[part 8 of 11: package /CANAnalyzer/CommunicationClusters]
AUTOSAR XML (schema 00051)
package /CANAnalyzer/CommunicationClusters  (continued)
  can cluster CAN_FD_IPB_41  (continued)
    can physical channel Channel  (continued)
      frame StatusUWBRangingFDD1FBD_HL: id 0x1C8, frame-length=64, can-addressing-mode=STANDARD, can-frame-rx-behavior=CAN-FD, can-frame-tx-behavior=CAN-FD
        pdu StatusUWBRangingFDD1FBD_HL: length=64, unused-bit-pattern=0
          signal StatusUWBRangingFDD1FBD_HL_SessionIDShort: start 0, 8 bit, little-endian, data-type-policy=OVERRIDE, base-type=uint8, compu {phys=raw}, range phys 0..252
          signal StatusUWBRangingFDD1FBD_HL_UWBSessionID: start 8, 32 bit, little-endian, data-type-policy=OVERRIDE, base-type=uint32, compu {phys=raw}, range phys 0..4294967292
          signal StatusUWBRangingFDD1FBD_HL_RangingBlock: start 40, 16 bit, little-endian, data-type-policy=OVERRIDE, base-type=uint16, compu {phys=raw}, range phys 0..65532
          signal StatusUWBRangingFDD1FBD_HL_HoppingFlag: start 56, 8 bit, little-endian, data-type-policy=OVERRIDE, base-type=uint8, compu {phys=raw}, range phys 0..252
          signal StatusUWBRangingFDD1FBD_HL_RoundIndex: start 64, 16 bit, little-endian, data-type-policy=OVERRIDE, base-type=uint16, compu {phys=raw}, range phys 0..65532
          signal StatusUWBRangingFDD1FBD_HL_FinalSTSIndex: start 80, 32 bit, little-endian, data-type-policy=OVERRIDE, base-type=uint32, compu {phys=raw}, range phys 0..4294967292
          signal StatusUWBRangingFDD1FBD_HL_FinalTimeStamp: start 112, 32 bit, little-endian, data-type-policy=OVERRIDE, base-type=uint32, compu {phys=raw}, range phys 0..4294967292
          signal StatusUWBRangingFDD1FBD_HL_NumberResponder: start 144, 8 bit, little-endian, data-type-policy=OVERRIDE, base-type=uint8, compu {phys=raw}, range phys 0..252
          signal StatusUWBRangingFDD1FBD_HL_IndexResponder1: start 152, 8 bit, little-endian, data-type-policy=OVERRIDE, base-type=uint8, compu {phys=raw}, range phys 0..252
          signal StatusUWBRangingFDD1FBD_HL_TimeStampResponder1: start 160, 32 bit, little-endian, data-type-policy=OVERRIDE, base-type=uint32, compu {phys=raw}, range phys 0..4294967292
          signal StatusUWBRangingFDD1FBD_HL_TimeStampUncertaintyResponder1: start 192, 8 bit, little-endian, data-type-policy=OVERRIDE, base-type=uint8, compu {phys=raw}, range phys 0..252
          signal StatusUWBRangingFDD1FBD_HL_StatusResponder1: start 200, 8 bit, little-endian, data-type-policy=OVERRIDE, base-type=uint8, compu {phys=raw}, range phys 0..252
          signal StatusUWBRangingFDD1FBD_HL_IndexResponder2: start 208, 8 bit, little-endian, data-type-policy=OVERRIDE, base-type=uint8, compu {phys=raw}, range phys 0..252
          signal StatusUWBRangingFDD1FBD_HL_TimeStampResponder2: start 216, 32 bit, little-endian, data-type-policy=OVERRIDE, base-type=uint32, compu {phys=raw}, range phys 0..4294967292
          signal StatusUWBRangingFDD1FBD_HL_TimeStampUncertaintyResponder2: start 248, 8 bit, little-endian, data-type-policy=OVERRIDE, base-type=uint8, compu {phys=raw}, range phys 0..252
          signal StatusUWBRangingFDD1FBD_HL_StatusResponder2: start 256, 8 bit, little-endian, data-type-policy=OVERRIDE, base-type=uint8, compu {phys=raw}, range phys 0..252
          signal StatusUWBRangingFDD1FBD_HL_IndexResponder3: start 264, 8 bit, little-endian, data-type-policy=OVERRIDE, base-type=uint8, compu {phys=raw}, range phys 0..252
          signal StatusUWBRangingFDD1FBD_HL_TimeStampResponder3: start 272, 32 bit, little-endian, data-type-policy=OVERRIDE, base-type=uint32, compu {phys=raw}, range phys 0..4294967292
          signal StatusUWBRangingFDD1FBD_HL_TimeStampUncertaintyResponder3: start 304, 8 bit, little-endian, data-type-policy=OVERRIDE, base-type=uint8, compu {phys=raw}, range phys 0..252
          signal StatusUWBRangingFDD1FBD_HL_StatusResponder3: start 312, 8 bit, little-endian, data-type-policy=OVERRIDE, base-type=uint8, compu {phys=raw}, range phys 0..252
          signal StatusUWBRangingFDD1FBD_HL_IndexResponder4: start 320, 8 bit, little-endian, data-type-policy=OVERRIDE, base-type=uint8, compu {phys=raw}, range phys 0..252
          signal StatusUWBRangingFDD1FBD_HL_TimeStampResponder4: start 328, 32 bit, little-endian, data-type-policy=OVERRIDE, base-type=uint32, compu {phys=raw}, range phys 0..4294967292
          signal StatusUWBRangingFDD1FBD_HL_TimeStampUncertaintyResponder4: start 360, 8 bit, little-endian, data-type-policy=OVERRIDE, base-type=uint8, compu {phys=raw}, range phys 0..252
          signal StatusUWBRangingFDD1FBD_HL_StatusResponder4: start 368, 8 bit, little-endian, data-type-policy=OVERRIDE, base-type=uint8, compu {phys=raw}, range phys 0..252
          signal StatusUWBRangingFDD1FBD_HL_IndexResponder5: start 376, 8 bit, little-endian, data-type-policy=OVERRIDE, base-type=uint8, compu {phys=raw}, range phys 0..252
          signal StatusUWBRangingFDD1FBD_HL_TimeStampResponder5: start 384, 32 bit, little-endian, data-type-policy=OVERRIDE, base-type=uint32, compu {phys=raw}, range phys 0..4294967292
          signal StatusUWBRangingFDD1FBD_HL_TimeStampUncertaintyResponder5: start 416, 8 bit, little-endian, data-type-policy=OVERRIDE, base-type=uint8, compu {phys=raw}, range phys 0..252
          signal StatusUWBRangingFDD1FBD_HL_StatusResponder5: start 424, 8 bit, little-endian, data-type-policy=OVERRIDE, base-type=uint8, compu {phys=raw}, range phys 0..252
          signal StatusUWBRangingFDD1FBD_HL_IndexResponder6: start 432, 8 bit, little-endian, data-type-policy=OVERRIDE, base-type=uint8, compu {phys=raw}, range phys 0..252
          signal StatusUWBRangingFDD1FBD_HL_TimeStampResponder6: start 440, 32 bit, little-endian, data-type-policy=OVERRIDE, base-type=uint32, compu {phys=raw}, range phys 0..4294967292
          signal StatusUWBRangingFDD1FBD_HL_TimeStampUncertaintyResponder6: start 472, 8 bit, little-endian, data-type-policy=OVERRIDE, base-type=uint8, compu {phys=raw}, range phys 0..252
          signal StatusUWBRangingFDD1FBD_HL_StatusResponder6: start 480, 8 bit, little-endian, data-type-policy=OVERRIDE, base-type=uint8, compu {phys=raw}, range phys 0..252
          signal StatusUWBRangingFDD1FBD_HL_IV0: start 488, 8 bit, little-endian, data-type-policy=OVERRIDE, base-type=uint8, compu {phys=raw}, range phys 0..255
          signal StatusUWBRangingFDD1FBD_HL_IV1: start 496, 8 bit, little-endian, data-type-policy=OVERRIDE, base-type=uint8, compu {phys=raw}, range phys 0..255
      frame StatusUWBRangingFDD1FBD_HM: id 0x1C3, frame-length=64, can-addressing-mode=STANDARD, can-frame-rx-behavior=CAN-FD, can-frame-tx-behavior=CAN-FD
        pdu StatusUWBRangingFDD1FBD_HM: length=64, unused-bit-pattern=0
          signal StatusUWBRangingFDD1FBD_HM_SessionIDShort: start 0, 8 bit, little-endian, data-type-policy=OVERRIDE, base-type=uint8, compu {phys=raw}, range phys 0..252
          signal StatusUWBRangingFDD1FBD_HM_UWBSessionID: start 8, 32 bit, little-endian, data-type-policy=OVERRIDE, base-type=uint32, compu {phys=raw}, range phys 0..4294967292
          signal StatusUWBRangingFDD1FBD_HM_RangingBlock: start 40, 16 bit, little-endian, data-type-policy=OVERRIDE, base-type=uint16, compu {phys=raw}, range phys 0..65532
          signal StatusUWBRangingFDD1FBD_HM_HoppingFlag: start 56, 8 bit, little-endian, data-type-policy=OVERRIDE, base-type=uint8, compu {phys=raw}, range phys 0..252
          signal StatusUWBRangingFDD1FBD_HM_RoundIndex: start 64, 16 bit, little-endian, data-type-policy=OVERRIDE, base-type=uint16, compu {phys=raw}, range phys 0..65532
          signal StatusUWBRangingFDD1FBD_HM_FinalSTSIndex: start 80, 32 bit, little-endian, data-type-policy=OVERRIDE, base-type=uint32, compu {phys=raw}, range phys 0..4294967292
          signal StatusUWBRangingFDD1FBD_HM_FinalTimeStamp: start 112, 32 bit, little-endian, data-type-policy=OVERRIDE, base-type=uint32, compu {phys=raw}, range phys 0..4294967292
          signal StatusUWBRangingFDD1FBD_HM_NumberResponder: start 144, 8 bit, little-endian, data-type-policy=OVERRIDE, base-type=uint8, compu {phys=raw}, range phys 0..252
          signal StatusUWBRangingFDD1FBD_HM_IndexResponder1: start 152, 8 bit, little-endian, data-type-policy=OVERRIDE, base-type=uint8, compu {phys=raw}, range phys 0..252
          signal StatusUWBRangingFDD1FBD_HM_TimeStampResponder1: start 160, 32 bit, little-endian, data-type-policy=OVERRIDE, base-type=uint32, compu {phys=raw}, range phys 0..4294967292
          signal StatusUWBRangingFDD1FBD_HM_TimeStampUncertaintyResponder1: start 192, 8 bit, little-endian, data-type-policy=OVERRIDE, base-type=uint8, compu {phys=raw}, range phys 0..252
          signal StatusUWBRangingFDD1FBD_HM_StatusResponder1: start 200, 8 bit, little-endian, data-type-policy=OVERRIDE, base-type=uint8, compu {phys=raw}, range phys 0..252
          signal StatusUWBRangingFDD1FBD_HM_IndexResponder2: start 208, 8 bit, little-endian, data-type-policy=OVERRIDE, base-type=uint8, compu {phys=raw}, range phys 0..252
          signal StatusUWBRangingFDD1FBD_HM_TimeStampResponder2: start 216, 32 bit, little-endian, data-type-policy=OVERRIDE, base-type=uint32, compu {phys=raw}, range phys 0..4294967292
          signal StatusUWBRangingFDD1FBD_HM_TimeStampUncertaintyResponder2: start 248, 8 bit, little-endian, data-type-policy=OVERRIDE, base-type=uint8, compu {phys=raw}, range phys 0..252
          signal StatusUWBRangingFDD1FBD_HM_StatusResponder2: start 256, 8 bit, little-endian, data-type-policy=OVERRIDE, base-type=uint8, compu {phys=raw}, range phys 0..252
          signal StatusUWBRangingFDD1FBD_HM_IndexResponder3: start 264, 8 bit, little-endian, data-type-policy=OVERRIDE, base-type=uint8, compu {phys=raw}, range phys 0..252
          signal StatusUWBRangingFDD1FBD_HM_TimeStampResponder3: start 272, 32 bit, little-endian, data-type-policy=OVERRIDE, base-type=uint32, compu {phys=raw}, range phys 0..4294967292
          signal StatusUWBRangingFDD1FBD_HM_TimeStampUncertaintyResponder3: start 304, 8 bit, little-endian, data-type-policy=OVERRIDE, base-type=uint8, compu {phys=raw}, range phys 0..252
          signal StatusUWBRangingFDD1FBD_HM_StatusResponder3: start 312, 8 bit, little-endian, data-type-policy=OVERRIDE, base-type=uint8, compu {phys=raw}, range phys 0..252
          signal StatusUWBRangingFDD1FBD_HM_IndexResponder4: start 320, 8 bit, little-endian, data-type-policy=OVERRIDE, base-type=uint8, compu {phys=raw}, range phys 0..252
          signal StatusUWBRangingFDD1FBD_HM_TimeStampResponder4: start 328, 32 bit, little-endian, data-type-policy=OVERRIDE, base-type=uint32, compu {phys=raw}, range phys 0..4294967292
          signal StatusUWBRangingFDD1FBD_HM_TimeStampUncertaintyResponder4: start 360, 8 bit, little-endian, data-type-policy=OVERRIDE, base-type=uint8, compu {phys=raw}, range phys 0..252
          signal StatusUWBRangingFDD1FBD_HM_StatusResponder4: start 368, 8 bit, little-endian, data-type-policy=OVERRIDE, base-type=uint8, compu {phys=raw}, range phys 0..252
          signal StatusUWBRangingFDD1FBD_HM_IndexResponder5: start 376, 8 bit, little-endian, data-type-policy=OVERRIDE, base-type=uint8, compu {phys=raw}, range phys 0..252
          signal StatusUWBRangingFDD1FBD_HM_TimeStampResponder5: start 384, 32 bit, little-endian, data-type-policy=OVERRIDE, base-type=uint32, compu {phys=raw}, range phys 0..4294967292
          signal StatusUWBRangingFDD1FBD_HM_TimeStampUncertaintyResponder5: start 416, 8 bit, little-endian, data-type-policy=OVERRIDE, base-type=uint8, compu {phys=raw}, range phys 0..252
          signal StatusUWBRangingFDD1FBD_HM_StatusResponder5: start 424, 8 bit, little-endian, data-type-policy=OVERRIDE, base-type=uint8, compu {phys=raw}, range phys 0..252
          signal StatusUWBRangingFDD1FBD_HM_IndexResponder6: start 432, 8 bit, little-endian, data-type-policy=OVERRIDE, base-type=uint8, compu {phys=raw}, range phys 0..252
          signal StatusUWBRangingFDD1FBD_HM_TimeStampResponder6: start 440, 32 bit, little-endian, data-type-policy=OVERRIDE, base-type=uint32, compu {phys=raw}, range phys 0..4294967292
          signal StatusUWBRangingFDD1FBD_HM_TimeStampUncertaintyResponder6: start 472, 8 bit, little-endian, data-type-policy=OVERRIDE, base-type=uint8, compu {phys=raw}, range phys 0..252
          signal StatusUWBRangingFDD1FBD_HM_StatusResponder6: start 480, 8 bit, little-endian, data-type-policy=OVERRIDE, base-type=uint8, compu {phys=raw}, range phys 0..252
          signal StatusUWBRangingFDD1FBD_HM_IV0: start 488, 8 bit, little-endian, data-type-policy=OVERRIDE, base-type=uint8, compu {phys=raw}, range phys 0..255
          signal StatusUWBRangingFDD1FBD_HM_IV1: start 496, 8 bit, little-endian, data-type-policy=OVERRIDE, base-type=uint8, compu {phys=raw}, range phys 0..255
      frame StatusUWBRangingFDD1FBD_HR: id 0x1C9, frame-length=64, can-addressing-mode=STANDARD, can-frame-rx-behavior=CAN-FD, can-frame-tx-behavior=CAN-FD
        pdu StatusUWBRangingFDD1FBD_HR: length=64, unused-bit-pattern=0
          signal StatusUWBRangingFDD1FBD_HR_SessionIDShort: start 0, 8 bit, little-endian, data-type-policy=OVERRIDE, base-type=uint8, compu {phys=raw}, range phys 0..252
          signal StatusUWBRangingFDD1FBD_HR_UWBSessionID: start 8, 32 bit, little-endian, data-type-policy=OVERRIDE, base-type=uint32, compu {phys=raw}, range phys 0..4294967292
          signal StatusUWBRangingFDD1FBD_HR_RangingBlock: start 40, 16 bit, little-endian, data-type-policy=OVERRIDE, base-type=uint16, compu {phys=raw}, range phys 0..65532
          signal StatusUWBRangingFDD1FBD_HR_HoppingFlag: start 56, 8 bit, little-endian, data-type-policy=OVERRIDE, base-type=uint8, compu {phys=raw}, range phys 0..252
          signal StatusUWBRangingFDD1FBD_HR_RoundIndex: start 64, 16 bit, little-endian, data-type-policy=OVERRIDE, base-type=uint16, compu {phys=raw}, range phys 0..65532
          signal StatusUWBRangingFDD1FBD_HR_FinalSTSIndex: start 80, 32 bit, little-endian, data-type-policy=OVERRIDE, base-type=uint32, compu {phys=raw}, range phys 0..4294967292
          signal StatusUWBRangingFDD1FBD_HR_FinalTimeStamp: start 112, 32 bit, little-endian, data-type-policy=OVERRIDE, base-type=uint32, compu {phys=raw}, range phys 0..4294967292
          signal StatusUWBRangingFDD1FBD_HR_NumberResponder: start 144, 8 bit, little-endian, data-type-policy=OVERRIDE, base-type=uint8, compu {phys=raw}, range phys 0..252
          signal StatusUWBRangingFDD1FBD_HR_IndexResponder1: start 152, 8 bit, little-endian, data-type-policy=OVERRIDE, base-type=uint8, compu {phys=raw}, range phys 0..252
          signal StatusUWBRangingFDD1FBD_HR_TimeStampResponder1: start 160, 32 bit, little-endian, data-type-policy=OVERRIDE, base-type=uint32, compu {phys=raw}, range phys 0..4294967292
          signal StatusUWBRangingFDD1FBD_HR_TimeStampUncertaintyResponder1: start 192, 8 bit, little-endian, data-type-policy=OVERRIDE, base-type=uint8, compu {phys=raw}, range phys 0..252
          signal StatusUWBRangingFDD1FBD_HR_StatusResponder1: start 200, 8 bit, little-endian, data-type-policy=OVERRIDE, base-type=uint8, compu {phys=raw}, range phys 0..252
          signal StatusUWBRangingFDD1FBD_HR_IndexResponder2: start 208, 8 bit, little-endian, data-type-policy=OVERRIDE, base-type=uint8, compu {phys=raw}, range phys 0..252
          signal StatusUWBRangingFDD1FBD_HR_TimeStampResponder2: start 216, 32 bit, little-endian, data-type-policy=OVERRIDE, base-type=uint32, compu {phys=raw}, range phys 0..4294967292
          signal StatusUWBRangingFDD1FBD_HR_TimeStampUncertaintyResponder2: start 248, 8 bit, little-endian, data-type-policy=OVERRIDE, base-type=uint8, compu {phys=raw}, range phys 0..252
          signal StatusUWBRangingFDD1FBD_HR_StatusResponder2: start 256, 8 bit, little-endian, data-type-policy=OVERRIDE, base-type=uint8, compu {phys=raw}, range phys 0..252
          signal StatusUWBRangingFDD1FBD_HR_IndexResponder3: start 264, 8 bit, little-endian, data-type-policy=OVERRIDE, base-type=uint8, compu {phys=raw}, range phys 0..252
          signal StatusUWBRangingFDD1FBD_HR_TimeStampResponder3: start 272, 32 bit, little-endian, data-type-policy=OVERRIDE, base-type=uint32, compu {phys=raw}, range phys 0..4294967292
          signal StatusUWBRangingFDD1FBD_HR_TimeStampUncertaintyResponder3: start 304, 8 bit, little-endian, data-type-policy=OVERRIDE, base-type=uint8, compu {phys=raw}, range phys 0..252
          signal StatusUWBRangingFDD1FBD_HR_StatusResponder3: start 312, 8 bit, little-endian, data-type-policy=OVERRIDE, base-type=uint8, compu {phys=raw}, range phys 0..252
          signal StatusUWBRangingFDD1FBD_HR_IndexResponder4: start 320, 8 bit, little-endian, data-type-policy=OVERRIDE, base-type=uint8, compu {phys=raw}, range phys 0..252
          signal StatusUWBRangingFDD1FBD_HR_TimeStampResponder4: start 328, 32 bit, little-endian, data-type-policy=OVERRIDE, base-type=uint32, compu {phys=raw}, range phys 0..4294967292
          signal StatusUWBRangingFDD1FBD_HR_TimeStampUncertaintyResponder4: start 360, 8 bit, little-endian, data-type-policy=OVERRIDE, base-type=uint8, compu {phys=raw}, range phys 0..252
          signal StatusUWBRangingFDD1FBD_HR_StatusResponder4: start 368, 8 bit, little-endian, data-type-policy=OVERRIDE, base-type=uint8, compu {phys=raw}, range phys 0..252
          signal StatusUWBRangingFDD1FBD_HR_IndexResponder5: start 376, 8 bit, little-endian, data-type-policy=OVERRIDE, base-type=uint8, compu {phys=raw}, range phys 0..252
          signal StatusUWBRangingFDD1FBD_HR_TimeStampResponder5: start 384, 32 bit, little-endian, data-type-policy=OVERRIDE, base-type=uint32, compu {phys=raw}, range phys 0..4294967292
          signal StatusUWBRangingFDD1FBD_HR_TimeStampUncertaintyResponder5: start 416, 8 bit, little-endian, data-type-policy=OVERRIDE, base-type=uint8, compu {phys=raw}, range phys 0..252
          signal StatusUWBRangingFDD1FBD_HR_StatusResponder5: start 424, 8 bit, little-endian, data-type-policy=OVERRIDE, base-type=uint8, compu {phys=raw}, range phys 0..252
          signal StatusUWBRangingFDD1FBD_HR_IndexResponder6: start 432, 8 bit, little-endian, data-type-policy=OVERRIDE, base-type=uint8, compu {phys=raw}, range phys 0..252
          signal StatusUWBRangingFDD1FBD_HR_TimeStampResponder6: start 440, 32 bit, little-endian, data-type-policy=OVERRIDE, base-type=uint32, compu {phys=raw}, range phys 0..4294967292
          signal StatusUWBRangingFDD1FBD_HR_TimeStampUncertaintyResponder6: start 472, 8 bit, little-endian, data-type-policy=OVERRIDE, base-type=uint8, compu {phys=raw}, range phys 0..252
          signal StatusUWBRangingFDD1FBD_HR_StatusResponder6: start 480, 8 bit, little-endian, data-type-policy=OVERRIDE, base-type=uint8, compu {phys=raw}, range phys 0..252
          signal StatusUWBRangingFDD1FBD_HR_IV0: start 488, 8 bit, little-endian, data-type-policy=OVERRIDE, base-type=uint8, compu {phys=raw}, range phys 0..255
          signal StatusUWBRangingFDD1FBD_HR_IV1: start 496, 8 bit, little-endian, data-type-policy=OVERRIDE, base-type=uint8, compu {phys=raw}, range phys 0..255
      frame StatusUWBRangingFDD1FBD_Miko: id 0x1C4, frame-length=64, can-addressing-mode=STANDARD, can-frame-rx-behavior=CAN-FD, can-frame-tx-behavior=CAN-FD
        pdu StatusUWBRangingFDD1FBD_Miko: length=64, unused-bit-pattern=0
          signal StatusUWBRangingFDD1FBD_Miko_SessionIDShort: start 0, 8 bit, little-endian, data-type-policy=OVERRIDE, base-type=uint8, compu {phys=raw}, range phys 0..252
          signal StatusUWBRangingFDD1FBD_Miko_UWBSessionID: start 8, 32 bit, little-endian, data-type-policy=OVERRIDE, base-type=uint32, compu {phys=raw}, range phys 0..4294967292
          signal StatusUWBRangingFDD1FBD_Miko_RangingBlock: start 40, 16 bit, little-endian, data-type-policy=OVERRIDE, base-type=uint16, compu {phys=raw}, range phys 0..65532
          signal StatusUWBRangingFDD1FBD_Miko_HoppingFlag: start 56, 8 bit, little-endian, data-type-policy=OVERRIDE, base-type=uint8, compu {phys=raw}, range phys 0..252
          signal StatusUWBRangingFDD1FBD_Miko_RoundIndex: start 64, 16 bit, little-endian, data-type-policy=OVERRIDE, base-type=uint16, compu {phys=raw}, range phys 0..65532
          signal StatusUWBRangingFDD1FBD_Miko_FinalSTSIndex: start 80, 32 bit, little-endian, data-type-policy=OVERRIDE, base-type=uint32, compu {phys=raw}, range phys 0..4294967292
          signal StatusUWBRangingFDD1FBD_Miko_FinalTimeStamp: start 112, 32 bit, little-endian, data-type-policy=OVERRIDE, base-type=uint32, compu {phys=raw}, range phys 0..4294967292
          signal StatusUWBRangingFDD1FBD_Miko_NumberResponder: start 144, 8 bit, little-endian, data-type-policy=OVERRIDE, base-type=uint8, compu {phys=raw}, range phys 0..252
          signal StatusUWBRangingFDD1FBD_Miko_IndexResponder1: start 152, 8 bit, little-endian, data-type-policy=OVERRIDE, base-type=uint8, compu {phys=raw}, range phys 0..252
          signal StatusUWBRangingFDD1FBD_Miko_TimeStampResponder1: start 160, 32 bit, little-endian, data-type-policy=OVERRIDE, base-type=uint32, compu {phys=raw}, range phys 0..4294967292
          signal StatusUWBRangingFDD1FBD_Miko_TimeStampUncertaintyResponder1: start 192, 8 bit, little-endian, data-type-policy=OVERRIDE, base-type=uint8, compu {phys=raw}, range phys 0..252
          signal StatusUWBRangingFDD1FBD_Miko_StatusResponder1: start 200, 8 bit, little-endian, data-type-policy=OVERRIDE, base-type=uint8, compu {phys=raw}, range phys 0..252
          signal StatusUWBRangingFDD1FBD_Miko_IndexResponder2: start 208, 8 bit, little-endian, data-type-policy=OVERRIDE, base-type=uint8, compu {phys=raw}, range phys 0..252
          signal StatusUWBRangingFDD1FBD_Miko_TimeStampResponder2: start 216, 32 bit, little-endian, data-type-policy=OVERRIDE, base-type=uint32, compu {phys=raw}, range phys 0..4294967292
          signal StatusUWBRangingFDD1FBD_Miko_TimeStampUncertaintyResponder2: start 248, 8 bit, little-endian, data-type-policy=OVERRIDE, base-type=uint8, compu {phys=raw}, range phys 0..252
          signal StatusUWBRangingFDD1FBD_Miko_StatusResponder2: start 256, 8 bit, little-endian, data-type-policy=OVERRIDE, base-type=uint8, compu {phys=raw}, range phys 0..252
          signal StatusUWBRangingFDD1FBD_Miko_IndexResponder3: start 264, 8 bit, little-endian, data-type-policy=OVERRIDE, base-type=uint8, compu {phys=raw}, range phys 0..252
          signal StatusUWBRangingFDD1FBD_Miko_TimeStampResponder3: start 272, 32 bit, little-endian, data-type-policy=OVERRIDE, base-type=uint32, compu {phys=raw}, range phys 0..4294967292
          signal StatusUWBRangingFDD1FBD_Miko_TimeStampUncertaintyResponder3: start 304, 8 bit, little-endian, data-type-policy=OVERRIDE, base-type=uint8, compu {phys=raw}, range phys 0..252
          signal StatusUWBRangingFDD1FBD_Miko_StatusResponder3: start 312, 8 bit, little-endian, data-type-policy=OVERRIDE, base-type=uint8, compu {phys=raw}, range phys 0..252
          signal StatusUWBRangingFDD1FBD_Miko_IndexResponder4: start 320, 8 bit, little-endian, data-type-policy=OVERRIDE, base-type=uint8, compu {phys=raw}, range phys 0..252
          signal StatusUWBRangingFDD1FBD_Miko_TimeStampResponder4: start 328, 32 bit, little-endian, data-type-policy=OVERRIDE, base-type=uint32, compu {phys=raw}, range phys 0..4294967292
          signal StatusUWBRangingFDD1FBD_Miko_TimeStampUncertaintyResponder4: start 360, 8 bit, little-endian, data-type-policy=OVERRIDE, base-type=uint8, compu {phys=raw}, range phys 0..252
          signal StatusUWBRangingFDD1FBD_Miko_StatusResponder4: start 368, 8 bit, little-endian, data-type-policy=OVERRIDE, base-type=uint8, compu {phys=raw}, range phys 0..252
          signal StatusUWBRangingFDD1FBD_Miko_IndexResponder5: start 376, 8 bit, little-endian, data-type-policy=OVERRIDE, base-type=uint8, compu {phys=raw}, range phys 0..252
          signal StatusUWBRangingFDD1FBD_Miko_TimeStampResponder5: start 384, 32 bit, little-endian, data-type-policy=OVERRIDE, base-type=uint32, compu {phys=raw}, range phys 0..4294967292
          signal StatusUWBRangingFDD1FBD_Miko_TimeStampUncertaintyResponder5: start 416, 8 bit, little-endian, data-type-policy=OVERRIDE, base-type=uint8, compu {phys=raw}, range phys 0..252
          signal StatusUWBRangingFDD1FBD_Miko_StatusResponder5: start 424, 8 bit, little-endian, data-type-policy=OVERRIDE, base-type=uint8, compu {phys=raw}, range phys 0..252
          signal StatusUWBRangingFDD1FBD_Miko_IndexResponder6: start 432, 8 bit, little-endian, data-type-policy=OVERRIDE, base-type=uint8, compu {phys=raw}, range phys 0..252
          signal StatusUWBRangingFDD1FBD_Miko_TimeStampResponder6: start 440, 32 bit, little-endian, data-type-policy=OVERRIDE, base-type=uint32, compu {phys=raw}, range phys 0..4294967292
          signal StatusUWBRangingFDD1FBD_Miko_TimeStampUncertaintyResponder6: start 472, 8 bit, little-endian, data-type-policy=OVERRIDE, base-type=uint8, compu {phys=raw}, range phys 0..252
          signal StatusUWBRangingFDD1FBD_Miko_StatusResponder6: start 480, 8 bit, little-endian, data-type-policy=OVERRIDE, base-type=uint8, compu {phys=raw}, range phys 0..252
          signal StatusUWBRangingFDD1FBD_Miko_IV0: start 488, 8 bit, little-endian, data-type-policy=OVERRIDE, base-type=uint8, compu {phys=raw}, range phys 0..255
          signal StatusUWBRangingFDD1FBD_Miko_IV1: start 496, 8 bit, little-endian, data-type-policy=OVERRIDE, base-type=uint8, compu {phys=raw}, range phys 0..255
      frame StatusUWBRangingFDD1FBD_MM: id 0x1BC, frame-length=64, can-addressing-mode=STANDARD, can-frame-rx-behavior=CAN-FD, can-frame-tx-behavior=CAN-FD
        pdu StatusUWBRangingFDD1FBD_MM: length=64, unused-bit-pattern=0
          signal StatusUWBRangingFDD1FBD_MM_SessionIDShort: start 0, 8 bit, little-endian, data-type-policy=OVERRIDE, base-type=uint8, compu {phys=raw}, range phys 0..252
          signal StatusUWBRangingFDD1FBD_MM_UWBSessionID: start 8, 32 bit, little-endian, data-type-policy=OVERRIDE, base-type=uint32, compu {phys=raw}, range phys 0..4294967292
          signal StatusUWBRangingFDD1FBD_MM_RangingBlock: start 40, 16 bit, little-endian, data-type-policy=OVERRIDE, base-type=uint16, compu {phys=raw}, range phys 0..65532
          signal StatusUWBRangingFDD1FBD_MM_HoppingFlag: start 56, 8 bit, little-endian, data-type-policy=OVERRIDE, base-type=uint8, compu {phys=raw}, range phys 0..252
          signal StatusUWBRangingFDD1FBD_MM_RoundIndex: start 64, 16 bit, little-endian, data-type-policy=OVERRIDE, base-type=uint16, compu {phys=raw}, range phys 0..65532
          signal StatusUWBRangingFDD1FBD_MM_FinalSTSIndex: start 80, 32 bit, little-endian, data-type-policy=OVERRIDE, base-type=uint32, compu {phys=raw}, range phys 0..4294967292
          signal StatusUWBRangingFDD1FBD_MM_FinalTimeStamp: start 112, 32 bit, little-endian, data-type-policy=OVERRIDE, base-type=uint32, compu {phys=raw}, range phys 0..4294967292
          signal StatusUWBRangingFDD1FBD_MM_NumberResponder: start 144, 8 bit, little-endian, data-type-policy=OVERRIDE, base-type=uint8, compu {phys=raw}, range phys 0..252
          signal StatusUWBRangingFDD1FBD_MM_IndexResponder1: start 152, 8 bit, little-endian, data-type-policy=OVERRIDE, base-type=uint8, compu {phys=raw}, range phys 0..252
          signal StatusUWBRangingFDD1FBD_MM_TimeStampResponder1: start 160, 32 bit, little-endian, data-type-policy=OVERRIDE, base-type=uint32, compu {phys=raw}, range phys 0..4294967292
          signal StatusUWBRangingFDD1FBD_MM_TimeStampUncertaintyResponder1: start 192, 8 bit, little-endian, data-type-policy=OVERRIDE, base-type=uint8, compu {phys=raw}, range phys 0..252
          signal StatusUWBRangingFDD1FBD_MM_StatusResponder1: start 200, 8 bit, little-endian, data-type-policy=OVERRIDE, base-type=uint8, compu {phys=raw}, range phys 0..252
          signal StatusUWBRangingFDD1FBD_MM_IndexResponder2: start 208, 8 bit, little-endian, data-type-policy=OVERRIDE, base-type=uint8, compu {phys=raw}, range phys 0..252
          signal StatusUWBRangingFDD1FBD_MM_TimeStampResponder2: start 216, 32 bit, little-endian, data-type-policy=OVERRIDE, base-type=uint32, compu {phys=raw}, range phys 0..4294967292
          signal StatusUWBRangingFDD1FBD_MM_TimeStampUncertaintyResponder2: start 248, 8 bit, little-endian, data-type-policy=OVERRIDE, base-type=uint8, compu {phys=raw}, range phys 0..252
          signal StatusUWBRangingFDD1FBD_MM_StatusResponder2: start 256, 8 bit, little-endian, data-type-policy=OVERRIDE, base-type=uint8, compu {phys=raw}, range phys 0..252
          signal StatusUWBRangingFDD1FBD_MM_IndexResponder3: start 264, 8 bit, little-endian, data-type-policy=OVERRIDE, base-type=uint8, compu {phys=raw}, range phys 0..252
          signal StatusUWBRangingFDD1FBD_MM_TimeStampResponder3: start 272, 32 bit, little-endian, data-type-policy=OVERRIDE, base-type=uint32, compu {phys=raw}, range phys 0..4294967292
          signal StatusUWBRangingFDD1FBD_MM_TimeStampUncertaintyResponder3: start 304, 8 bit, little-endian, data-type-policy=OVERRIDE, base-type=uint8, compu {phys=raw}, range phys 0..252
          signal StatusUWBRangingFDD1FBD_MM_StatusResponder3: start 312, 8 bit, little-endian, data-type-policy=OVERRIDE, base-type=uint8, compu {phys=raw}, range phys 0..252
          signal StatusUWBRangingFDD1FBD_MM_IndexResponder4: start 320, 8 bit, little-endian, data-type-policy=OVERRIDE, base-type=uint8, compu {phys=raw}, range phys 0..252
          signal StatusUWBRangingFDD1FBD_MM_TimeStampResponder4: start 328, 32 bit, little-endian, data-type-policy=OVERRIDE, base-type=uint32, compu {phys=raw}, range phys 0..4294967292
          signal StatusUWBRangingFDD1FBD_MM_TimeStampUncertaintyResponder4: start 360, 8 bit, little-endian, data-type-policy=OVERRIDE, base-type=uint8, compu {phys=raw}, range phys 0..252
          signal StatusUWBRangingFDD1FBD_MM_StatusResponder4: start 368, 8 bit, little-endian, data-type-policy=OVERRIDE, base-type=uint8, compu {phys=raw}, range phys 0..252
          signal StatusUWBRangingFDD1FBD_MM_IndexResponder5: start 376, 8 bit, little-endian, data-type-policy=OVERRIDE, base-type=uint8, compu {phys=raw}, range phys 0..252
          signal StatusUWBRangingFDD1FBD_MM_TimeStampResponder5: start 384, 32 bit, little-endian, data-type-policy=OVERRIDE, base-type=uint32, compu {phys=raw}, range phys 0..4294967292
          signal StatusUWBRangingFDD1FBD_MM_TimeStampUncertaintyResponder5: start 416, 8 bit, little-endian, data-type-policy=OVERRIDE, base-type=uint8, compu {phys=raw}, range phys 0..252
          signal StatusUWBRangingFDD1FBD_MM_StatusResponder5: start 424, 8 bit, little-endian, data-type-policy=OVERRIDE, base-type=uint8, compu {phys=raw}, range phys 0..252
          signal StatusUWBRangingFDD1FBD_MM_IndexResponder6: start 432, 8 bit, little-endian, data-type-policy=OVERRIDE, base-type=uint8, compu {phys=raw}, range phys 0..252
          signal StatusUWBRangingFDD1FBD_MM_TimeStampResponder6: start 440, 32 bit, little-endian, data-type-policy=OVERRIDE, base-type=uint32, compu {phys=raw}, range phys 0..4294967292
          signal StatusUWBRangingFDD1FBD_MM_TimeStampUncertaintyResponder6: start 472, 8 bit, little-endian, data-type-policy=OVERRIDE, base-type=uint8, compu {phys=raw}, range phys 0..252
          signal StatusUWBRangingFDD1FBD_MM_StatusResponder6: start 480, 8 bit, little-endian, data-type-policy=OVERRIDE, base-type=uint8, compu {phys=raw}, range phys 0..252
          signal StatusUWBRangingFDD1FBD_MM_IV0: start 488, 8 bit, little-endian, data-type-policy=OVERRIDE, base-type=uint8, compu {phys=raw}, range phys 0..255
          signal StatusUWBRangingFDD1FBD_MM_IV1: start 496, 8 bit, little-endian, data-type-policy=OVERRIDE, base-type=uint8, compu {phys=raw}, range phys 0..255
      frame StatusUWBRangingFDD1FBD_SML: id 0x1CA, frame-length=64, can-addressing-mode=STANDARD, can-frame-rx-behavior=CAN-FD, can-frame-tx-behavior=CAN-FD
        pdu StatusUWBRangingFDD1FBD_SML: length=64, unused-bit-pattern=0
          signal StatusUWBRangingFDD1FBD_SML_SessionIDShort: start 0, 8 bit, little-endian, data-type-policy=OVERRIDE, base-type=uint8, compu {phys=raw}, range phys 0..252
          signal StatusUWBRangingFDD1FBD_SML_UWBSessionID: start 8, 32 bit, little-endian, data-type-policy=OVERRIDE, base-type=uint32, compu {phys=raw}, range phys 0..4294967292
          signal StatusUWBRangingFDD1FBD_SML_RangingBlock: start 40, 16 bit, little-endian, data-type-policy=OVERRIDE, base-type=uint16, compu {phys=raw}, range phys 0..65532
          signal StatusUWBRangingFDD1FBD_SML_HoppingFlag: start 56, 8 bit, little-endian, data-type-policy=OVERRIDE, base-type=uint8, compu {phys=raw}, range phys 0..252
          signal StatusUWBRangingFDD1FBD_SML_RoundIndex: start 64, 16 bit, little-endian, data-type-policy=OVERRIDE, base-type=uint16, compu {phys=raw}, range phys 0..65532
          signal StatusUWBRangingFDD1FBD_SML_FinalSTSIndex: start 80, 32 bit, little-endian, data-type-policy=OVERRIDE, base-type=uint32, compu {phys=raw}, range phys 0..4294967292
          signal StatusUWBRangingFDD1FBD_SML_FinalTimeStamp: start 112, 32 bit, little-endian, data-type-policy=OVERRIDE, base-type=uint32, compu {phys=raw}, range phys 0..4294967292
          signal StatusUWBRangingFDD1FBD_SML_NumberResponder: start 144, 8 bit, little-endian, data-type-policy=OVERRIDE, base-type=uint8, compu {phys=raw}, range phys 0..252
          signal StatusUWBRangingFDD1FBD_SML_IndexResponder1: start 152, 8 bit, little-endian, data-type-policy=OVERRIDE, base-type=uint8, compu {phys=raw}, range phys 0..252
          signal StatusUWBRangingFDD1FBD_SML_TimeStampResponder1: start 160, 32 bit, little-endian, data-type-policy=OVERRIDE, base-type=uint32, compu {phys=raw}, range phys 0..4294967292
          signal StatusUWBRangingFDD1FBD_SML_TimeStampUncertaintyResponder1: start 192, 8 bit, little-endian, data-type-policy=OVERRIDE, base-type=uint8, compu {phys=raw}, range phys 0..252
          signal StatusUWBRangingFDD1FBD_SML_StatusResponder1: start 200, 8 bit, little-endian, data-type-policy=OVERRIDE, base-type=uint8, compu {phys=raw}, range phys 0..252
          signal StatusUWBRangingFDD1FBD_SML_IndexResponder2: start 208, 8 bit, little-endian, data-type-policy=OVERRIDE, base-type=uint8, compu {phys=raw}, range phys 0..252
          signal StatusUWBRangingFDD1FBD_SML_TimeStampResponder2: start 216, 32 bit, little-endian, data-type-policy=OVERRIDE, base-type=uint32, compu {phys=raw}, range phys 0..4294967292
          signal StatusUWBRangingFDD1FBD_SML_TimeStampUncertaintyResponder2: start 248, 8 bit, little-endian, data-type-policy=OVERRIDE, base-type=uint8, compu {phys=raw}, range phys 0..252
          signal StatusUWBRangingFDD1FBD_SML_StatusResponder2: start 256, 8 bit, little-endian, data-type-policy=OVERRIDE, base-type=uint8, compu {phys=raw}, range phys 0..252
          signal StatusUWBRangingFDD1FBD_SML_IndexResponder3: start 264, 8 bit, little-endian, data-type-policy=OVERRIDE, base-type=uint8, compu {phys=raw}, range phys 0..252
          signal StatusUWBRangingFDD1FBD_SML_TimeStampResponder3: start 272, 32 bit, little-endian, data-type-policy=OVERRIDE, base-type=uint32, compu {phys=raw}, range phys 0..4294967292
          signal StatusUWBRangingFDD1FBD_SML_TimeStampUncertaintyResponder3: start 304, 8 bit, little-endian, data-type-policy=OVERRIDE, base-type=uint8, compu {phys=raw}, range phys 0..252
          signal StatusUWBRangingFDD1FBD_SML_StatusResponder3: start 312, 8 bit, little-endian, data-type-policy=OVERRIDE, base-type=uint8, compu {phys=raw}, range phys 0..252
          signal StatusUWBRangingFDD1FBD_SML_IndexResponder4: start 320, 8 bit, little-endian, data-type-policy=OVERRIDE, base-type=uint8, compu {phys=raw}, range phys 0..252
          signal StatusUWBRangingFDD1FBD_SML_TimeStampResponder4: start 328, 32 bit, little-endian, data-type-policy=OVERRIDE, base-type=uint32, compu {phys=raw}, range phys 0..4294967292
          signal StatusUWBRangingFDD1FBD_SML_TimeStampUncertaintyResponder4: start 360, 8 bit, little-endian, data-type-policy=OVERRIDE, base-type=uint8, compu {phys=raw}, range phys 0..252
          signal StatusUWBRangingFDD1FBD_SML_StatusResponder4: start 368, 8 bit, little-endian, data-type-policy=OVERRIDE, base-type=uint8, compu {phys=raw}, range phys 0..252
          signal StatusUWBRangingFDD1FBD_SML_IndexResponder5: start 376, 8 bit, little-endian, data-type-policy=OVERRIDE, base-type=uint8, compu {phys=raw}, range phys 0..252
          signal StatusUWBRangingFDD1FBD_SML_TimeStampResponder5: start 384, 32 bit, little-endian, data-type-policy=OVERRIDE, base-type=uint32, compu {phys=raw}, range phys 0..4294967292
          signal StatusUWBRangingFDD1FBD_SML_TimeStampUncertaintyResponder5: start 416, 8 bit, little-endian, data-type-policy=OVERRIDE, base-type=uint8, compu {phys=raw}, range phys 0..252
          signal StatusUWBRangingFDD1FBD_SML_StatusResponder5: start 424, 8 bit, little-endian, data-type-policy=OVERRIDE, base-type=uint8, compu {phys=raw}, range phys 0..252
          signal StatusUWBRangingFDD1FBD_SML_IndexResponder6: start 432, 8 bit, little-endian, data-type-policy=OVERRIDE, base-type=uint8, compu {phys=raw}, range phys 0..252
          signal StatusUWBRangingFDD1FBD_SML_TimeStampResponder6: start 440, 32 bit, little-endian, data-type-policy=OVERRIDE, base-type=uint32, compu {phys=raw}, range phys 0..4294967292
          signal StatusUWBRangingFDD1FBD_SML_TimeStampUncertaintyResponder6: start 472, 8 bit, little-endian, data-type-policy=OVERRIDE, base-type=uint8, compu {phys=raw}, range phys 0..252
          signal StatusUWBRangingFDD1FBD_SML_StatusResponder6: start 480, 8 bit, little-endian, data-type-policy=OVERRIDE, base-type=uint8, compu {phys=raw}, range phys 0..252
          signal StatusUWBRangingFDD1FBD_SML_IV0: start 488, 8 bit, little-endian, data-type-policy=OVERRIDE, base-type=uint8, compu {phys=raw}, range phys 0..255
          signal StatusUWBRangingFDD1FBD_SML_IV1: start 496, 8 bit, little-endian, data-type-policy=OVERRIDE, base-type=uint8, compu {phys=raw}, range phys 0..255
      frame StatusUWBRangingFDD1FBD_SMR: id 0x1CB, frame-length=64, can-addressing-mode=STANDARD, can-frame-rx-behavior=CAN-FD, can-frame-tx-behavior=CAN-FD
        pdu StatusUWBRangingFDD1FBD_SMR: length=64, unused-bit-pattern=0
          signal StatusUWBRangingFDD1FBD_SMR_SessionIDShort: start 0, 8 bit, little-endian, data-type-policy=OVERRIDE, base-type=uint8, compu {phys=raw}, range phys 0..252
          signal StatusUWBRangingFDD1FBD_SMR_UWBSessionID: start 8, 32 bit, little-endian, data-type-policy=OVERRIDE, base-type=uint32, compu {phys=raw}, range phys 0..4294967292
          signal StatusUWBRangingFDD1FBD_SMR_RangingBlock: start 40, 16 bit, little-endian, data-type-policy=OVERRIDE, base-type=uint16, compu {phys=raw}, range phys 0..65532
          signal StatusUWBRangingFDD1FBD_SMR_HoppingFlag: start 56, 8 bit, little-endian, data-type-policy=OVERRIDE, base-type=uint8, compu {phys=raw}, range phys 0..252
          signal StatusUWBRangingFDD1FBD_SMR_RoundIndex: start 64, 16 bit, little-endian, data-type-policy=OVERRIDE, base-type=uint16, compu {phys=raw}, range phys 0..65532
          signal StatusUWBRangingFDD1FBD_SMR_FinalSTSIndex: start 80, 32 bit, little-endian, data-type-policy=OVERRIDE, base-type=uint32, compu {phys=raw}, range phys 0..4294967292
          signal StatusUWBRangingFDD1FBD_SMR_FinalTimeStamp: start 112, 32 bit, little-endian, data-type-policy=OVERRIDE, base-type=uint32, compu {phys=raw}, range phys 0..4294967292
          signal StatusUWBRangingFDD1FBD_SMR_NumberResponder: start 144, 8 bit, little-endian, data-type-policy=OVERRIDE, base-type=uint8, compu {phys=raw}, range phys 0..252
          signal StatusUWBRangingFDD1FBD_SMR_IndexResponder1: start 152, 8 bit, little-endian, data-type-policy=OVERRIDE, base-type=uint8, compu {phys=raw}, range phys 0..252
          signal StatusUWBRangingFDD1FBD_SMR_TimeStampResponder1: start 160, 32 bit, little-endian, data-type-policy=OVERRIDE, base-type=uint32, compu {phys=raw}, range phys 0..4294967292
          signal StatusUWBRangingFDD1FBD_SMR_TimeStampUncertaintyResponder1: start 192, 8 bit, little-endian, data-type-policy=OVERRIDE, base-type=uint8, compu {phys=raw}, range phys 0..252
          signal StatusUWBRangingFDD1FBD_SMR_StatusResponder1: start 200, 8 bit, little-endian, data-type-policy=OVERRIDE, base-type=uint8, compu {phys=raw}, range phys 0..252
          signal StatusUWBRangingFDD1FBD_SMR_IndexResponder2: start 208, 8 bit, little-endian, data-type-policy=OVERRIDE, base-type=uint8, compu {phys=raw}, range phys 0..252
          signal StatusUWBRangingFDD1FBD_SMR_TimeStampResponder2: start 216, 32 bit, little-endian, data-type-policy=OVERRIDE, base-type=uint32, compu {phys=raw}, range phys 0..4294967292
          signal StatusUWBRangingFDD1FBD_SMR_TimeStampUncertaintyResponder2: start 248, 8 bit, little-endian, data-type-policy=OVERRIDE, base-type=uint8, compu {phys=raw}, range phys 0..252
          signal StatusUWBRangingFDD1FBD_SMR_StatusResponder2: start 256, 8 bit, little-endian, data-type-policy=OVERRIDE, base-type=uint8, compu {phys=raw}, range phys 0..252
          signal StatusUWBRangingFDD1FBD_SMR_IndexResponder3: start 264, 8 bit, little-endian, data-type-policy=OVERRIDE, base-type=uint8, compu {phys=raw}, range phys 0..252
          signal StatusUWBRangingFDD1FBD_SMR_TimeStampResponder3: start 272, 32 bit, little-endian, data-type-policy=OVERRIDE, base-type=uint32, compu {phys=raw}, range phys 0..4294967292
          signal StatusUWBRangingFDD1FBD_SMR_TimeStampUncertaintyResponder3: start 304, 8 bit, little-endian, data-type-policy=OVERRIDE, base-type=uint8, compu {phys=raw}, range phys 0..252
          signal StatusUWBRangingFDD1FBD_SMR_StatusResponder3: start 312, 8 bit, little-endian, data-type-policy=OVERRIDE, base-type=uint8, compu {phys=raw}, range phys 0..252
          signal StatusUWBRangingFDD1FBD_SMR_IndexResponder4: start 320, 8 bit, little-endian, data-type-policy=OVERRIDE, base-type=uint8, compu {phys=raw}, range phys 0..252
          signal StatusUWBRangingFDD1FBD_SMR_TimeStampResponder4: start 328, 32 bit, little-endian, data-type-policy=OVERRIDE, base-type=uint32, compu {phys=raw}, range phys 0..4294967292
          signal StatusUWBRangingFDD1FBD_SMR_TimeStampUncertaintyResponder4: start 360, 8 bit, little-endian, data-type-policy=OVERRIDE, base-type=uint8, compu {phys=raw}, range phys 0..252
          signal StatusUWBRangingFDD1FBD_SMR_StatusResponder4: start 368, 8 bit, little-endian, data-type-policy=OVERRIDE, base-type=uint8, compu {phys=raw}, range phys 0..252
          signal StatusUWBRangingFDD1FBD_SMR_IndexResponder5: start 376, 8 bit, little-endian, data-type-policy=OVERRIDE, base-type=uint8, compu {phys=raw}, range phys 0..252
          signal StatusUWBRangingFDD1FBD_SMR_TimeStampResponder5: start 384, 32 bit, little-endian, data-type-policy=OVERRIDE, base-type=uint32, compu {phys=raw}, range phys 0..4294967292
          signal StatusUWBRangingFDD1FBD_SMR_TimeStampUncertaintyResponder5: start 416, 8 bit, little-endian, data-type-policy=OVERRIDE, base-type=uint8, compu {phys=raw}, range phys 0..252
          signal StatusUWBRangingFDD1FBD_SMR_StatusResponder5: start 424, 8 bit, little-endian, data-type-policy=OVERRIDE, base-type=uint8, compu {phys=raw}, range phys 0..252
          signal StatusUWBRangingFDD1FBD_SMR_IndexResponder6: start 432, 8 bit, little-endian, data-type-policy=OVERRIDE, base-type=uint8, compu {phys=raw}, range phys 0..252
          signal StatusUWBRangingFDD1FBD_SMR_TimeStampResponder6: start 440, 32 bit, little-endian, data-type-policy=OVERRIDE, base-type=uint32, compu {phys=raw}, range phys 0..4294967292
          signal StatusUWBRangingFDD1FBD_SMR_TimeStampUncertaintyResponder6: start 472, 8 bit, little-endian, data-type-policy=OVERRIDE, base-type=uint8, compu {phys=raw}, range phys 0..252
          signal StatusUWBRangingFDD1FBD_SMR_StatusResponder6: start 480, 8 bit, little-endian, data-type-policy=OVERRIDE, base-type=uint8, compu {phys=raw}, range phys 0..252
          signal StatusUWBRangingFDD1FBD_SMR_IV0: start 488, 8 bit, little-endian, data-type-policy=OVERRIDE, base-type=uint8, compu {phys=raw}, range phys 0..255
          signal StatusUWBRangingFDD1FBD_SMR_IV1: start 496, 8 bit, little-endian, data-type-policy=OVERRIDE, base-type=uint8, compu {phys=raw}, range phys 0..255
      frame StatusUWBRangingFDD1FBD_Trunk: id 0x1C5, frame-length=64, can-addressing-mode=STANDARD, can-frame-rx-behavior=CAN-FD, can-frame-tx-behavior=CAN-FD
        pdu StatusUWBRangingFDD1FBD_Trunk: length=64, unused-bit-pattern=0
          signal StatusUWBRangingFDD1FBD_Trunk_SessionIDShort: start 0, 8 bit, little-endian, data-type-policy=OVERRIDE, base-type=uint8, compu {phys=raw}, range phys 0..252
          signal StatusUWBRangingFDD1FBD_Trunk_UWBSessionID: start 8, 32 bit, little-endian, data-type-policy=OVERRIDE, base-type=uint32, compu {phys=raw}, range phys 0..4294967292
          signal StatusUWBRangingFDD1FBD_Trunk_RangingBlock: start 40, 16 bit, little-endian, data-type-policy=OVERRIDE, base-type=uint16, compu {phys=raw}, range phys 0..65532
          signal StatusUWBRangingFDD1FBD_Trunk_HoppingFlag: start 56, 8 bit, little-endian, data-type-policy=OVERRIDE, base-type=uint8, compu {phys=raw}, range phys 0..252
          signal StatusUWBRangingFDD1FBD_Trunk_RoundIndex: start 64, 16 bit, little-endian, data-type-policy=OVERRIDE, base-type=uint16, compu {phys=raw}, range phys 0..65532
          signal StatusUWBRangingFDD1FBD_Trunk_FinalSTSIndex: start 80, 32 bit, little-endian, data-type-policy=OVERRIDE, base-type=uint32, compu {phys=raw}, range phys 0..4294967292
          signal StatusUWBRangingFDD1FBD_Trunk_FinalTimeStamp: start 112, 32 bit, little-endian, data-type-policy=OVERRIDE, base-type=uint32, compu {phys=raw}, range phys 0..4294967292
          signal StatusUWBRangingFDD1FBD_Trunk_NumberResponder: start 144, 8 bit, little-endian, data-type-policy=OVERRIDE, base-type=uint8, compu {phys=raw}, range phys 0..252
          signal StatusUWBRangingFDD1FBD_Trunk_IndexResponder1: start 152, 8 bit, little-endian, data-type-policy=OVERRIDE, base-type=uint8, compu {phys=raw}, range phys 0..252
          signal StatusUWBRangingFDD1FBD_Trunk_TimeStampResponder1: start 160, 32 bit, little-endian, data-type-policy=OVERRIDE, base-type=uint32, compu {phys=raw}, range phys 0..4294967292
          signal StatusUWBRangingFDD1FBD_Trunk_TimeStampUncertaintyResponder1: start 192, 8 bit, little-endian, data-type-policy=OVERRIDE, base-type=uint8, compu {phys=raw}, range phys 0..252
          signal StatusUWBRangingFDD1FBD_Trunk_StatusResponder1: start 200, 8 bit, little-endian, data-type-policy=OVERRIDE, base-type=uint8, compu {phys=raw}, range phys 0..252
          signal StatusUWBRangingFDD1FBD_Trunk_IndexResponder2: start 208, 8 bit, little-endian, data-type-policy=OVERRIDE, base-type=uint8, compu {phys=raw}, range phys 0..252
          signal StatusUWBRangingFDD1FBD_Trunk_TimeStampResponder2: start 216, 32 bit, little-endian, data-type-policy=OVERRIDE, base-type=uint32, compu {phys=raw}, range phys 0..4294967292
          signal StatusUWBRangingFDD1FBD_Trunk_TimeStampUncertaintyResponder2: start 248, 8 bit, little-endian, data-type-policy=OVERRIDE, base-type=uint8, compu {phys=raw}, range phys 0..252
          signal StatusUWBRangingFDD1FBD_Trunk_StatusResponder2: start 256, 8 bit, little-endian, data-type-policy=OVERRIDE, base-type=uint8, compu {phys=raw}, range phys 0..252
          signal StatusUWBRangingFDD1FBD_Trunk_IndexResponder3: start 264, 8 bit, little-endian, data-type-policy=OVERRIDE, base-type=uint8, compu {phys=raw}, range phys 0..252
          signal StatusUWBRangingFDD1FBD_Trunk_TimeStampResponder3: start 272, 32 bit, little-endian, data-type-policy=OVERRIDE, base-type=uint32, compu {phys=raw}, range phys 0..4294967292
          signal StatusUWBRangingFDD1FBD_Trunk_TimeStampUncertaintyResponder3: start 304, 8 bit, little-endian, data-type-policy=OVERRIDE, base-type=uint8, compu {phys=raw}, range phys 0..252
          signal StatusUWBRangingFDD1FBD_Trunk_StatusResponder3: start 312, 8 bit, little-endian, data-type-policy=OVERRIDE, base-type=uint8, compu {phys=raw}, range phys 0..252
          signal StatusUWBRangingFDD1FBD_Trunk_IndexResponder4: start 320, 8 bit, little-endian, data-type-policy=OVERRIDE, base-type=uint8, compu {phys=raw}, range phys 0..252
          signal StatusUWBRangingFDD1FBD_Trunk_TimeStampResponder4: start 328, 32 bit, little-endian, data-type-policy=OVERRIDE, base-type=uint32, compu {phys=raw}, range phys 0..4294967292
          signal StatusUWBRangingFDD1FBD_Trunk_TimeStampUncertaintyResponder4: start 360, 8 bit, little-endian, data-type-policy=OVERRIDE, base-type=uint8, compu {phys=raw}, range phys 0..252
          signal StatusUWBRangingFDD1FBD_Trunk_StatusResponder4: start 368, 8 bit, little-endian, data-type-policy=OVERRIDE, base-type=uint8, compu {phys=raw}, range phys 0..252
          signal StatusUWBRangingFDD1FBD_Trunk_IndexResponder5: start 376, 8 bit, little-endian, data-type-policy=OVERRIDE, base-type=uint8, compu {phys=raw}, range phys 0..252
          signal StatusUWBRangingFDD1FBD_Trunk_TimeStampResponder5: start 384, 32 bit, little-endian, data-type-policy=OVERRIDE, base-type=uint32, compu {phys=raw}, range phys 0..4294967292
          signal StatusUWBRangingFDD1FBD_Trunk_TimeStampUncertaintyResponder5: start 416, 8 bit, little-endian, data-type-policy=OVERRIDE, base-type=uint8, compu {phys=raw}, range phys 0..252
          signal StatusUWBRangingFDD1FBD_Trunk_StatusResponder5: start 424, 8 bit, little-endian, data-type-policy=OVERRIDE, base-type=uint8, compu {phys=raw}, range phys 0..252
          signal StatusUWBRangingFDD1FBD_Trunk_IndexResponder6: start 432, 8 bit, little-endian, data-type-policy=OVERRIDE, base-type=uint8, compu {phys=raw}, range phys 0..252
          signal StatusUWBRangingFDD1FBD_Trunk_TimeStampResponder6: start 440, 32 bit, little-endian, data-type-policy=OVERRIDE, base-type=uint32, compu {phys=raw}, range phys 0..4294967292
          signal StatusUWBRangingFDD1FBD_Trunk_TimeStampUncertaintyResponder6: start 472, 8 bit, little-endian, data-type-policy=OVERRIDE, base-type=uint8, compu {phys=raw}, range phys 0..252
          signal StatusUWBRangingFDD1FBD_Trunk_StatusResponder6: start 480, 8 bit, little-endian, data-type-policy=OVERRIDE, base-type=uint8, compu {phys=raw}, range phys 0..252
          signal StatusUWBRangingFDD1FBD_Trunk_IV0: start 488, 8 bit, little-endian, data-type-policy=OVERRIDE, base-type=uint8, compu {phys=raw}, range phys 0..255
          signal StatusUWBRangingFDD1FBD_Trunk_IV1: start 496, 8 bit, little-endian, data-type-policy=OVERRIDE, base-type=uint8, compu {phys=raw}, range phys 0..255
      frame StatusUWBRangingFDD1FBD_VL: id 0x1C6, frame-length=64, can-addressing-mode=STANDARD, can-frame-rx-behavior=CAN-FD, can-frame-tx-behavior=CAN-FD
        pdu StatusUWBRangingFDD1FBD_VL: length=64, unused-bit-pattern=0
          signal StatusUWBRangingFDD1FBD_VL_SessionIDShort: start 0, 8 bit, little-endian, data-type-policy=OVERRIDE, base-type=uint8, compu {phys=raw}, range phys 0..252
          signal StatusUWBRangingFDD1FBD_VL_UWBSessionID: start 8, 32 bit, little-endian, data-type-policy=OVERRIDE, base-type=uint32, compu {phys=raw}, range phys 0..4294967292
          signal StatusUWBRangingFDD1FBD_VL_RangingBlock: start 40, 16 bit, little-endian, data-type-policy=OVERRIDE, base-type=uint16, compu {phys=raw}, range phys 0..65532
          signal StatusUWBRangingFDD1FBD_VL_HoppingFlag: start 56, 8 bit, little-endian, data-type-policy=OVERRIDE, base-type=uint8, compu {phys=raw}, range phys 0..252
          signal StatusUWBRangingFDD1FBD_VL_RoundIndex: start 64, 16 bit, little-endian, data-type-policy=OVERRIDE, base-type=uint16, compu {phys=raw}, range phys 0..65532
          signal StatusUWBRangingFDD1FBD_VL_FinalSTSIndex: start 80, 32 bit, little-endian, data-type-policy=OVERRIDE, base-type=uint32, compu {phys=raw}, range phys 0..4294967292
          signal StatusUWBRangingFDD1FBD_VL_FinalTimeStamp: start 112, 32 bit, little-endian, data-type-policy=OVERRIDE, base-type=uint32, compu {phys=raw}, range phys 0..4294967292
          signal StatusUWBRangingFDD1FBD_VL_NumberResponder: start 144, 8 bit, little-endian, data-type-policy=OVERRIDE, base-type=uint8, compu {phys=raw}, range phys 0..252
          signal StatusUWBRangingFDD1FBD_VL_IndexResponder1: start 152, 8 bit, little-endian, data-type-policy=OVERRIDE, base-type=uint8, compu {phys=raw}, range phys 0..252
          signal StatusUWBRangingFDD1FBD_VL_TimeStampResponder1: start 160, 32 bit, little-endian, data-type-policy=OVERRIDE, base-type=uint32, compu {phys=raw}, range phys 0..4294967292
          signal StatusUWBRangingFDD1FBD_VL_TimeStampUncertaintyResponder1: start 192, 8 bit, little-endian, data-type-policy=OVERRIDE, base-type=uint8, compu {phys=raw}, range phys 0..252
          signal StatusUWBRangingFDD1FBD_VL_StatusResponder1: start 200, 8 bit, little-endian, data-type-policy=OVERRIDE, base-type=uint8, compu {phys=raw}, range phys 0..252
          signal StatusUWBRangingFDD1FBD_VL_IndexResponder2: start 208, 8 bit, little-endian, data-type-policy=OVERRIDE, base-type=uint8, compu {phys=raw}, range phys 0..252
          signal StatusUWBRangingFDD1FBD_VL_TimeStampResponder2: start 216, 32 bit, little-endian, data-type-policy=OVERRIDE, base-type=uint32, compu {phys=raw}, range phys 0..4294967292
          signal StatusUWBRangingFDD1FBD_VL_TimeStampUncertaintyResponder2: start 248, 8 bit, little-endian, data-type-policy=OVERRIDE, base-type=uint8, compu {phys=raw}, range phys 0..252
          signal StatusUWBRangingFDD1FBD_VL_StatusResponder2: start 256, 8 bit, little-endian, data-type-policy=OVERRIDE, base-type=uint8, compu {phys=raw}, range phys 0..252
          signal StatusUWBRangingFDD1FBD_VL_IndexResponder3: start 264, 8 bit, little-endian, data-type-policy=OVERRIDE, base-type=uint8, compu {phys=raw}, range phys 0..252
          signal StatusUWBRangingFDD1FBD_VL_TimeStampResponder3: start 272, 32 bit, little-endian, data-type-policy=OVERRIDE, base-type=uint32, compu {phys=raw}, range phys 0..4294967292
          signal StatusUWBRangingFDD1FBD_VL_TimeStampUncertaintyResponder3: start 304, 8 bit, little-endian, data-type-policy=OVERRIDE, base-type=uint8, compu {phys=raw}, range phys 0..252
          signal StatusUWBRangingFDD1FBD_VL_StatusResponder3: start 312, 8 bit, little-endian, data-type-policy=OVERRIDE, base-type=uint8, compu {phys=raw}, range phys 0..252
          signal StatusUWBRangingFDD1FBD_VL_IndexResponder4: start 320, 8 bit, little-endian, data-type-policy=OVERRIDE, base-type=uint8, compu {phys=raw}, range phys 0..252
          signal StatusUWBRangingFDD1FBD_VL_TimeStampResponder4: start 328, 32 bit, little-endian, data-type-policy=OVERRIDE, base-type=uint32, compu {phys=raw}, range phys 0..4294967292
          signal StatusUWBRangingFDD1FBD_VL_TimeStampUncertaintyResponder4: start 360, 8 bit, little-endian, data-type-policy=OVERRIDE, base-type=uint8, compu {phys=raw}, range phys 0..252
          signal StatusUWBRangingFDD1FBD_VL_StatusResponder4: start 368, 8 bit, little-endian, data-type-policy=OVERRIDE, base-type=uint8, compu {phys=raw}, range phys 0..252
          signal StatusUWBRangingFDD1FBD_VL_IndexResponder5: start 376, 8 bit, little-endian, data-type-policy=OVERRIDE, base-type=uint8, compu {phys=raw}, range phys 0..252
          signal StatusUWBRangingFDD1FBD_VL_TimeStampResponder5: start 384, 32 bit, little-endian, data-type-policy=OVERRIDE, base-type=uint32, compu {phys=raw}, range phys 0..4294967292
          signal StatusUWBRangingFDD1FBD_VL_TimeStampUncertaintyResponder5: start 416, 8 bit, little-endian, data-type-policy=OVERRIDE, base-type=uint8, compu {phys=raw}, range phys 0..252
          signal StatusUWBRangingFDD1FBD_VL_StatusResponder5: start 424, 8 bit, little-endian, data-type-policy=OVERRIDE, base-type=uint8, compu {phys=raw}, range phys 0..252
          signal StatusUWBRangingFDD1FBD_VL_IndexResponder6: start 432, 8 bit, little-endian, data-type-policy=OVERRIDE, base-type=uint8, compu {phys=raw}, range phys 0..252
          signal StatusUWBRangingFDD1FBD_VL_TimeStampResponder6: start 440, 32 bit, little-endian, data-type-policy=OVERRIDE, base-type=uint32, compu {phys=raw}, range phys 0..4294967292
          signal StatusUWBRangingFDD1FBD_VL_TimeStampUncertaintyResponder6: start 472, 8 bit, little-endian, data-type-policy=OVERRIDE, base-type=uint8, compu {phys=raw}, range phys 0..252
          signal StatusUWBRangingFDD1FBD_VL_StatusResponder6: start 480, 8 bit, little-endian, data-type-policy=OVERRIDE, base-type=uint8, compu {phys=raw}, range phys 0..252
          signal StatusUWBRangingFDD1FBD_VL_IV0: start 488, 8 bit, little-endian, data-type-policy=OVERRIDE, base-type=uint8, compu {phys=raw}, range phys 0..255
          signal StatusUWBRangingFDD1FBD_VL_IV1: start 496, 8 bit, little-endian, data-type-policy=OVERRIDE, base-type=uint8, compu {phys=raw}, range phys 0..255
      frame StatusUWBRangingFDD1FBD_VM: id 0x1C2, frame-length=64, can-addressing-mode=STANDARD, can-frame-rx-behavior=CAN-FD, can-frame-tx-behavior=CAN-FD
        pdu StatusUWBRangingFDD1FBD_VM: length=64, unused-bit-pattern=0
          signal StatusUWBRangingFDD1FBD_VM_SessionIDShort: start 0, 8 bit, little-endian, data-type-policy=OVERRIDE, base-type=uint8, compu {phys=raw}, range phys 0..252
          signal StatusUWBRangingFDD1FBD_VM_UWBSessionID: start 8, 32 bit, little-endian, data-type-policy=OVERRIDE, base-type=uint32, compu {phys=raw}, range phys 0..4294967292
          signal StatusUWBRangingFDD1FBD_VM_RangingBlock: start 40, 16 bit, little-endian, data-type-policy=OVERRIDE, base-type=uint16, compu {phys=raw}, range phys 0..65532
          signal StatusUWBRangingFDD1FBD_VM_HoppingFlag: start 56, 8 bit, little-endian, data-type-policy=OVERRIDE, base-type=uint8, compu {phys=raw}, range phys 0..252
          signal StatusUWBRangingFDD1FBD_VM_RoundIndex: start 64, 16 bit, little-endian, data-type-policy=OVERRIDE, base-type=uint16, compu {phys=raw}, range phys 0..65532
          signal StatusUWBRangingFDD1FBD_VM_FinalSTSIndex: start 80, 32 bit, little-endian, data-type-policy=OVERRIDE, base-type=uint32, compu {phys=raw}, range phys 0..4294967292
          signal StatusUWBRangingFDD1FBD_VM_FinalTimeStamp: start 112, 32 bit, little-endian, data-type-policy=OVERRIDE, base-type=uint32, compu {phys=raw}, range phys 0..4294967292
          signal StatusUWBRangingFDD1FBD_VM_NumberResponder: start 144, 8 bit, little-endian, data-type-policy=OVERRIDE, base-type=uint8, compu {phys=raw}, range phys 0..252
          signal StatusUWBRangingFDD1FBD_VM_IndexResponder1: start 152, 8 bit, little-endian, data-type-policy=OVERRIDE, base-type=uint8, compu {phys=raw}, range phys 0..252
          signal StatusUWBRangingFDD1FBD_VM_TimeStampResponder1: start 160, 32 bit, little-endian, data-type-policy=OVERRIDE, base-type=uint32, compu {phys=raw}, range phys 0..4294967292
          signal StatusUWBRangingFDD1FBD_VM_TimeStampUncertaintyResponder1: start 192, 8 bit, little-endian, data-type-policy=OVERRIDE, base-type=uint8, compu {phys=raw}, range phys 0..252
          signal StatusUWBRangingFDD1FBD_VM_StatusResponder1: start 200, 8 bit, little-endian, data-type-policy=OVERRIDE, base-type=uint8, compu {phys=raw}, range phys 0..252
          signal StatusUWBRangingFDD1FBD_VM_IndexResponder2: start 208, 8 bit, little-endian, data-type-policy=OVERRIDE, base-type=uint8, compu {phys=raw}, range phys 0..252
          signal StatusUWBRangingFDD1FBD_VM_TimeStampResponder2: start 216, 32 bit, little-endian, data-type-policy=OVERRIDE, base-type=uint32, compu {phys=raw}, range phys 0..4294967292
          signal StatusUWBRangingFDD1FBD_VM_TimeStampUncertaintyResponder2: start 248, 8 bit, little-endian, data-type-policy=OVERRIDE, base-type=uint8, compu {phys=raw}, range phys 0..252
          signal StatusUWBRangingFDD1FBD_VM_StatusResponder2: start 256, 8 bit, little-endian, data-type-policy=OVERRIDE, base-type=uint8, compu {phys=raw}, range phys 0..252
          signal StatusUWBRangingFDD1FBD_VM_IndexResponder3: start 264, 8 bit, little-endian, data-type-policy=OVERRIDE, base-type=uint8, compu {phys=raw}, range phys 0..252
          signal StatusUWBRangingFDD1FBD_VM_TimeStampResponder3: start 272, 32 bit, little-endian, data-type-policy=OVERRIDE, base-type=uint32, compu {phys=raw}, range phys 0..4294967292
          signal StatusUWBRangingFDD1FBD_VM_TimeStampUncertaintyResponder3: start 304, 8 bit, little-endian, data-type-policy=OVERRIDE, base-type=uint8, compu {phys=raw}, range phys 0..252
          signal StatusUWBRangingFDD1FBD_VM_StatusResponder3: start 312, 8 bit, little-endian, data-type-policy=OVERRIDE, base-type=uint8, compu {phys=raw}, range phys 0..252
          signal StatusUWBRangingFDD1FBD_VM_IndexResponder4: start 320, 8 bit, little-endian, data-type-policy=OVERRIDE, base-type=uint8, compu {phys=raw}, range phys 0..252
          signal StatusUWBRangingFDD1FBD_VM_TimeStampResponder4: start 328, 32 bit, little-endian, data-type-policy=OVERRIDE, base-type=uint32, compu {phys=raw}, range phys 0..4294967292
          signal StatusUWBRangingFDD1FBD_VM_TimeStampUncertaintyResponder4: start 360, 8 bit, little-endian, data-type-policy=OVERRIDE, base-type=uint8, compu {phys=raw}, range phys 0..252
          signal StatusUWBRangingFDD1FBD_VM_StatusResponder4: start 368, 8 bit, little-endian, data-type-policy=OVERRIDE, base-type=uint8, compu {phys=raw}, range phys 0..252
          signal StatusUWBRangingFDD1FBD_VM_IndexResponder5: start 376, 8 bit, little-endian, data-type-policy=OVERRIDE, base-type=uint8, compu {phys=raw}, range phys 0..252
          signal StatusUWBRangingFDD1FBD_VM_TimeStampResponder5: start 384, 32 bit, little-endian, data-type-policy=OVERRIDE, base-type=uint32, compu {phys=raw}, range phys 0..4294967292
          signal StatusUWBRangingFDD1FBD_VM_TimeStampUncertaintyResponder5: start 416, 8 bit, little-endian, data-type-policy=OVERRIDE, base-type=uint8, compu {phys=raw}, range phys 0..252
          signal StatusUWBRangingFDD1FBD_VM_StatusResponder5: start 424, 8 bit, little-endian, data-type-policy=OVERRIDE, base-type=uint8, compu {phys=raw}, range phys 0..252
          signal StatusUWBRangingFDD1FBD_VM_IndexResponder6: start 432, 8 bit, little-endian, data-type-policy=OVERRIDE, base-type=uint8, compu {phys=raw}, range phys 0..252
          signal StatusUWBRangingFDD1FBD_VM_TimeStampResponder6: start 440, 32 bit, little-endian, data-type-policy=OVERRIDE, base-type=uint32, compu {phys=raw}, range phys 0..4294967292
          signal StatusUWBRangingFDD1FBD_VM_TimeStampUncertaintyResponder6: start 472, 8 bit, little-endian, data-type-policy=OVERRIDE, base-type=uint8, compu {phys=raw}, range phys 0..252
          signal StatusUWBRangingFDD1FBD_VM_StatusResponder6: start 480, 8 bit, little-endian, data-type-policy=OVERRIDE, base-type=uint8, compu {phys=raw}, range phys 0..252
          signal StatusUWBRangingFDD1FBD_VM_IV0: start 488, 8 bit, little-endian, data-type-policy=OVERRIDE, base-type=uint8, compu {phys=raw}, range phys 0..255
          signal StatusUWBRangingFDD1FBD_VM_IV1: start 496, 8 bit, little-endian, data-type-policy=OVERRIDE, base-type=uint8, compu {phys=raw}, range phys 0..255
      frame StatusUWBRangingFDD1FBD_VR: id 0x1C7, frame-length=64, can-addressing-mode=STANDARD, can-frame-rx-behavior=CAN-FD, can-frame-tx-behavior=CAN-FD
        pdu StatusUWBRangingFDD1FBD_VR: length=64, unused-bit-pattern=0
          signal StatusUWBRangingFDD1FBD_VR_SessionIDShort: start 0, 8 bit, little-endian, data-type-policy=OVERRIDE, base-type=uint8, compu {phys=raw}, range phys 0..252
          signal StatusUWBRangingFDD1FBD_VR_UWBSessionID: start 8, 32 bit, little-endian, data-type-policy=OVERRIDE, base-type=uint32, compu {phys=raw}, range phys 0..4294967292
          signal StatusUWBRangingFDD1FBD_VR_RangingBlock: start 40, 16 bit, little-endian, data-type-policy=OVERRIDE, base-type=uint16, compu {phys=raw}, range phys 0..65532
          signal StatusUWBRangingFDD1FBD_VR_HoppingFlag: start 56, 8 bit, little-endian, data-type-policy=OVERRIDE, base-type=uint8, compu {phys=raw}, range phys 0..252
          signal StatusUWBRangingFDD1FBD_VR_RoundIndex: start 64, 16 bit, little-endian, data-type-policy=OVERRIDE, base-type=uint16, compu {phys=raw}, range phys 0..65532
          signal StatusUWBRangingFDD1FBD_VR_FinalSTSIndex: start 80, 32 bit, little-endian, data-type-policy=OVERRIDE, base-type=uint32, compu {phys=raw}, range phys 0..4294967292
          signal StatusUWBRangingFDD1FBD_VR_FinalTimeStamp: start 112, 32 bit, little-endian, data-type-policy=OVERRIDE, base-type=uint32, compu {phys=raw}, range phys 0..4294967292
          signal StatusUWBRangingFDD1FBD_VR_NumberResponder: start 144, 8 bit, little-endian, data-type-policy=OVERRIDE, base-type=uint8, compu {phys=raw}, range phys 0..252
          signal StatusUWBRangingFDD1FBD_VR_IndexResponder1: start 152, 8 bit, little-endian, data-type-policy=OVERRIDE, base-type=uint8, compu {phys=raw}, range phys 0..252
          signal StatusUWBRangingFDD1FBD_VR_TimeStampResponder1: start 160, 32 bit, little-endian, data-type-policy=OVERRIDE, base-type=uint32, compu {phys=raw}, range phys 0..4294967292
          signal StatusUWBRangingFDD1FBD_VR_TimeStampUncertaintyResponder1: start 192, 8 bit, little-endian, data-type-policy=OVERRIDE, base-type=uint8, compu {phys=raw}, range phys 0..252
          signal StatusUWBRangingFDD1FBD_VR_StatusResponder1: start 200, 8 bit, little-endian, data-type-policy=OVERRIDE, base-type=uint8, compu {phys=raw}, range phys 0..252
          signal StatusUWBRangingFDD1FBD_VR_IndexResponder2: start 208, 8 bit, little-endian, data-type-policy=OVERRIDE, base-type=uint8, compu {phys=raw}, range phys 0..252
          signal StatusUWBRangingFDD1FBD_VR_TimeStampResponder2: start 216, 32 bit, little-endian, data-type-policy=OVERRIDE, base-type=uint32, compu {phys=raw}, range phys 0..4294967292
          signal StatusUWBRangingFDD1FBD_VR_TimeStampUncertaintyResponder2: start 248, 8 bit, little-endian, data-type-policy=OVERRIDE, base-type=uint8, compu {phys=raw}, range phys 0..252
          signal StatusUWBRangingFDD1FBD_VR_StatusResponder2: start 256, 8 bit, little-endian, data-type-policy=OVERRIDE, base-type=uint8, compu {phys=raw}, range phys 0..252
          signal StatusUWBRangingFDD1FBD_VR_IndexResponder3: start 264, 8 bit, little-endian, data-type-policy=OVERRIDE, base-type=uint8, compu {phys=raw}, range phys 0..252
          signal StatusUWBRangingFDD1FBD_VR_TimeStampResponder3: start 272, 32 bit, little-endian, data-type-policy=OVERRIDE, base-type=uint32, compu {phys=raw}, range phys 0..4294967292
          signal StatusUWBRangingFDD1FBD_VR_TimeStampUncertaintyResponder3: start 304, 8 bit, little-endian, data-type-policy=OVERRIDE, base-type=uint8, compu {phys=raw}, range phys 0..252
          signal StatusUWBRangingFDD1FBD_VR_StatusResponder3: start 312, 8 bit, little-endian, data-type-policy=OVERRIDE, base-type=uint8, compu {phys=raw}, range phys 0..252
          signal StatusUWBRangingFDD1FBD_VR_IndexResponder4: start 320, 8 bit, little-endian, data-type-policy=OVERRIDE, base-type=uint8, compu {phys=raw}, range phys 0..252
          signal StatusUWBRangingFDD1FBD_VR_TimeStampResponder4: start 328, 32 bit, little-endian, data-type-policy=OVERRIDE, base-type=uint32, compu {phys=raw}, range phys 0..4294967292
          signal StatusUWBRangingFDD1FBD_VR_TimeStampUncertaintyResponder4: start 360, 8 bit, little-endian, data-type-policy=OVERRIDE, base-type=uint8, compu {phys=raw}, range phys 0..252
          signal StatusUWBRangingFDD1FBD_VR_StatusResponder4: start 368, 8 bit, little-endian, data-type-policy=OVERRIDE, base-type=uint8, compu {phys=raw}, range phys 0..252
          signal StatusUWBRangingFDD1FBD_VR_IndexResponder5: start 376, 8 bit, little-endian, data-type-policy=OVERRIDE, base-type=uint8, compu {phys=raw}, range phys 0..252
          signal StatusUWBRangingFDD1FBD_VR_TimeStampResponder5: start 384, 32 bit, little-endian, data-type-policy=OVERRIDE, base-type=uint32, compu {phys=raw}, range phys 0..4294967292
          signal StatusUWBRangingFDD1FBD_VR_TimeStampUncertaintyResponder5: start 416, 8 bit, little-endian, data-type-policy=OVERRIDE, base-type=uint8, compu {phys=raw}, range phys 0..252
          signal StatusUWBRangingFDD1FBD_VR_StatusResponder5: start 424, 8 bit, little-endian, data-type-policy=OVERRIDE, base-type=uint8, compu {phys=raw}, range phys 0..252
          signal StatusUWBRangingFDD1FBD_VR_IndexResponder6: start 432, 8 bit, little-endian, data-type-policy=OVERRIDE, base-type=uint8, compu {phys=raw}, range phys 0..252
          signal StatusUWBRangingFDD1FBD_VR_TimeStampResponder6: start 440, 32 bit, little-endian, data-type-policy=OVERRIDE, base-type=uint32, compu {phys=raw}, range phys 0..4294967292
          signal StatusUWBRangingFDD1FBD_VR_TimeStampUncertaintyResponder6: start 472, 8 bit, little-endian, data-type-policy=OVERRIDE, base-type=uint8, compu {phys=raw}, range phys 0..252
          signal StatusUWBRangingFDD1FBD_VR_StatusResponder6: start 480, 8 bit, little-endian, data-type-policy=OVERRIDE, base-type=uint8, compu {phys=raw}, range phys 0..252
          signal StatusUWBRangingFDD1FBD_VR_IV0: start 488, 8 bit, little-endian, data-type-policy=OVERRIDE, base-type=uint8, compu {phys=raw}, range phys 0..255
          signal StatusUWBRangingFDD1FBD_VR_IV1: start 496, 8 bit, little-endian, data-type-policy=OVERRIDE, base-type=uint8, compu {phys=raw}, range phys 0..255
      frame StatusUWBRangingFDD2FBD_HL: id 0x1D2, frame-length=48, can-addressing-mode=STANDARD, can-frame-rx-behavior=CAN-FD, can-frame-tx-behavior=CAN-FD
        pdu StatusUWBRangingFDD2FBD_HL: length=48, unused-bit-pattern=0
          signal StatusUWBRangingFDD2FBD_HL_SessionIDShort: start 0, 8 bit, little-endian, data-type-policy=OVERRIDE, base-type=uint8, compu {phys=raw}, range phys 0..252
          signal StatusUWBRangingFDD2FBD_HL_IndexResponder7: start 8, 8 bit, little-endian, data-type-policy=OVERRIDE, base-type=uint8, compu {phys=raw}, range phys 0..252
          signal StatusUWBRangingFDD2FBD_HL_TimeStampResponder7: start 16, 32 bit, little-endian, data-type-policy=OVERRIDE, base-type=uint32, compu {phys=raw}, range phys 0..4294967292
          signal StatusUWBRangingFDD2FBD_HL_TimeStampUncertaintyResponder7: start 48, 8 bit, little-endian, data-type-policy=OVERRIDE, base-type=uint8, compu {phys=raw}, range phys 0..252
          signal StatusUWBRangingFDD2FBD_HL_StatusResponder7: start 56, 8 bit, little-endian, data-type-policy=OVERRIDE, base-type=uint8, compu {phys=raw}, range phys 0..252
          signal StatusUWBRangingFDD2FBD_HL_IndexResponder8: start 64, 8 bit, little-endian, data-type-policy=OVERRIDE, base-type=uint8, compu {phys=raw}, range phys 0..252
          signal StatusUWBRangingFDD2FBD_HL_TimeStampResponder8: start 72, 32 bit, little-endian, data-type-policy=OVERRIDE, base-type=uint32, compu {phys=raw}, range phys 0..4294967292
          signal StatusUWBRangingFDD2FBD_HL_TimeStampUncertaintyResponder8: start 104, 8 bit, little-endian, data-type-policy=OVERRIDE, base-type=uint8, compu {phys=raw}, range phys 0..252
          signal StatusUWBRangingFDD2FBD_HL_StatusResponder8: start 112, 8 bit, little-endian, data-type-policy=OVERRIDE, base-type=uint8, compu {phys=raw}, range phys 0..252
          signal StatusUWBRangingFDD2FBD_HL_IndexResponder9: start 120, 8 bit, little-endian, data-type-policy=OVERRIDE, base-type=uint8, compu {phys=raw}, range phys 0..252
          signal StatusUWBRangingFDD2FBD_HL_TimeStampResponder9: start 128, 32 bit, little-endian, data-type-policy=OVERRIDE, base-type=uint32, compu {phys=raw}, range phys 0..4294967292
          signal StatusUWBRangingFDD2FBD_HL_TimeStampUncertaintyResponder9: start 160, 8 bit, little-endian, data-type-policy=OVERRIDE, base-type=uint8, compu {phys=raw}, range phys 0..252
          signal StatusUWBRangingFDD2FBD_HL_StatusResponder9: start 168, 8 bit, little-endian, data-type-policy=OVERRIDE, base-type=uint8, compu {phys=raw}, range phys 0..252
          signal StatusUWBRangingFDD2FBD_HL_IndexResponder10: start 176, 8 bit, little-endian, data-type-policy=OVERRIDE, base-type=uint8, compu {phys=raw}, range phys 0..252
          signal StatusUWBRangingFDD2FBD_HL_TimeStampResponder10: start 184, 32 bit, little-endian, data-type-policy=OVERRIDE, base-type=uint32, compu {phys=raw}, range phys 0..4294967292
          signal StatusUWBRangingFDD2FBD_HL_TimeStampUncertaintyResponder10: start 216, 8 bit, little-endian, data-type-policy=OVERRIDE, base-type=uint8, compu {phys=raw}, range phys 0..252
          signal StatusUWBRangingFDD2FBD_HL_StatusResponder10: start 224, 8 bit, little-endian, data-type-policy=OVERRIDE, base-type=uint8, compu {phys=raw}, range phys 0..252
          signal StatusUWBRangingFDD2FBD_HL_TimeStampPoll: start 232, 64 bit, little-endian, data-type-policy=OVERRIDE, base-type=uint64, compu {phys=raw}, range phys 0..18446744073709551612
          signal StatusUWBRangingFDD2FBD_HL_Signature: start 296, 64 bit, little-endian, data-type-policy=OVERRIDE, base-type=uint64, compu {phys=raw}, range phys 0..18446744073709551614
          signal StatusUWBRangingFDD2FBD_HL_IV2: start 360, 8 bit, little-endian, data-type-policy=OVERRIDE, base-type=uint8, compu {phys=raw}, range phys 0..255
          signal StatusUWBRangingFDD2FBD_HL_IV3: start 368, 8 bit, little-endian, data-type-policy=OVERRIDE, base-type=uint8, compu {phys=raw}, range phys 0..255
      frame StatusUWBRangingFDD2FBD_HM: id 0x1CD, frame-length=48, can-addressing-mode=STANDARD, can-frame-rx-behavior=CAN-FD, can-frame-tx-behavior=CAN-FD
        pdu StatusUWBRangingFDD2FBD_HM: length=48, unused-bit-pattern=0
          signal StatusUWBRangingFDD2FBD_HM_SessionIDShort: start 0, 8 bit, little-endian, data-type-policy=OVERRIDE, base-type=uint8, compu {phys=raw}, range phys 0..252
          signal StatusUWBRangingFDD2FBD_HM_IndexResponder7: start 8, 8 bit, little-endian, data-type-policy=OVERRIDE, base-type=uint8, compu {phys=raw}, range phys 0..252
          signal StatusUWBRangingFDD2FBD_HM_TimeStampResponder7: start 16, 32 bit, little-endian, data-type-policy=OVERRIDE, base-type=uint32, compu {phys=raw}, range phys 0..4294967292
          signal StatusUWBRangingFDD2FBD_HM_TimeStampUncertaintyResponder7: start 48, 8 bit, little-endian, data-type-policy=OVERRIDE, base-type=uint8, compu {phys=raw}, range phys 0..252
          signal StatusUWBRangingFDD2FBD_HM_StatusResponder7: start 56, 8 bit, little-endian, data-type-policy=OVERRIDE, base-type=uint8, compu {phys=raw}, range phys 0..252
          signal StatusUWBRangingFDD2FBD_HM_IndexResponder8: start 64, 8 bit, little-endian, data-type-policy=OVERRIDE, base-type=uint8, compu {phys=raw}, range phys 0..252
          signal StatusUWBRangingFDD2FBD_HM_TimeStampResponder8: start 72, 32 bit, little-endian, data-type-policy=OVERRIDE, base-type=uint32, compu {phys=raw}, range phys 0..4294967292
          signal StatusUWBRangingFDD2FBD_HM_TimeStampUncertaintyResponder8: start 104, 8 bit, little-endian, data-type-policy=OVERRIDE, base-type=uint8, compu {phys=raw}, range phys 0..252
          signal StatusUWBRangingFDD2FBD_HM_StatusResponder8: start 112, 8 bit, little-endian, data-type-policy=OVERRIDE, base-type=uint8, compu {phys=raw}, range phys 0..252
          signal StatusUWBRangingFDD2FBD_HM_IndexResponder9: start 120, 8 bit, little-endian, data-type-policy=OVERRIDE, base-type=uint8, compu {phys=raw}, range phys 0..252
          signal StatusUWBRangingFDD2FBD_HM_TimeStampResponder9: start 128, 32 bit, little-endian, data-type-policy=OVERRIDE, base-type=uint32, compu {phys=raw}, range phys 0..4294967292
          signal StatusUWBRangingFDD2FBD_HM_TimeStampUncertaintyResponder9: start 160, 8 bit, little-endian, data-type-policy=OVERRIDE, base-type=uint8, compu {phys=raw}, range phys 0..252
          signal StatusUWBRangingFDD2FBD_HM_StatusResponder9: start 168, 8 bit, little-endian, data-type-policy=OVERRIDE, base-type=uint8, compu {phys=raw}, range phys 0..252
          signal StatusUWBRangingFDD2FBD_HM_IndexResponder10: start 176, 8 bit, little-endian, data-type-policy=OVERRIDE, base-type=uint8, compu {phys=raw}, range phys 0..252
          signal StatusUWBRangingFDD2FBD_HM_TimeStampResponder10: start 184, 32 bit, little-endian, data-type-policy=OVERRIDE, base-type=uint32, compu {phys=raw}, range phys 0..4294967292
          signal StatusUWBRangingFDD2FBD_HM_TimeStampUncertaintyResponder10: start 216, 8 bit, little-endian, data-type-policy=OVERRIDE, base-type=uint8, compu {phys=raw}, range phys 0..252
          signal StatusUWBRangingFDD2FBD_HM_StatusResponder10: start 224, 8 bit, little-endian, data-type-policy=OVERRIDE, base-type=uint8, compu {phys=raw}, range phys 0..252
          signal StatusUWBRangingFDD2FBD_HM_TimeStampPoll: start 232, 64 bit, little-endian, data-type-policy=OVERRIDE, base-type=uint64, compu {phys=raw}, range phys 0..18446744073709551612
          signal StatusUWBRangingFDD2FBD_HM_Signature: start 296, 64 bit, little-endian, data-type-policy=OVERRIDE, base-type=uint64, compu {phys=raw}, range phys 0..18446744073709551614
          signal StatusUWBRangingFDD2FBD_HM_IV2: start 360, 8 bit, little-endian, data-type-policy=OVERRIDE, base-type=uint8, compu {phys=raw}, range phys 0..255
          signal StatusUWBRangingFDD2FBD_HM_IV3: start 368, 8 bit, little-endian, data-type-policy=OVERRIDE, base-type=uint8, compu {phys=raw}, range phys 0..255
      frame StatusUWBRangingFDD2FBD_HR: id 0x1D3, frame-length=48, can-addressing-mode=STANDARD, can-frame-rx-behavior=CAN-FD, can-frame-tx-behavior=CAN-FD
        pdu StatusUWBRangingFDD2FBD_HR: length=48, unused-bit-pattern=0
          signal StatusUWBRangingFDD2FBD_HR_SessionIDShort: start 0, 8 bit, little-endian, data-type-policy=OVERRIDE, base-type=uint8, compu {phys=raw}, range phys 0..252
          signal StatusUWBRangingFDD2FBD_HR_IndexResponder7: start 8, 8 bit, little-endian, data-type-policy=OVERRIDE, base-type=uint8, compu {phys=raw}, range phys 0..252
          signal StatusUWBRangingFDD2FBD_HR_TimeStampResponder7: start 16, 32 bit, little-endian, data-type-policy=OVERRIDE, base-type=uint32, compu {phys=raw}, range phys 0..4294967292
          signal StatusUWBRangingFDD2FBD_HR_TimeStampUncertaintyResponder7: start 48, 8 bit, little-endian, data-type-policy=OVERRIDE, base-type=uint8, compu {phys=raw}, range phys 0..252
          signal StatusUWBRangingFDD2FBD_HR_StatusResponder7: start 56, 8 bit, little-endian, data-type-policy=OVERRIDE, base-type=uint8, compu {phys=raw}, range phys 0..252
          signal StatusUWBRangingFDD2FBD_HR_IndexResponder8: start 64, 8 bit, little-endian, data-type-policy=OVERRIDE, base-type=uint8, compu {phys=raw}, range phys 0..252
          signal StatusUWBRangingFDD2FBD_HR_TimeStampResponder8: start 72, 32 bit, little-endian, data-type-policy=OVERRIDE, base-type=uint32, compu {phys=raw}, range phys 0..4294967292
          signal StatusUWBRangingFDD2FBD_HR_TimeStampUncertaintyResponder8: start 104, 8 bit, little-endian, data-type-policy=OVERRIDE, base-type=uint8, compu {phys=raw}, range phys 0..252
          signal StatusUWBRangingFDD2FBD_HR_StatusResponder8: start 112, 8 bit, little-endian, data-type-policy=OVERRIDE, base-type=uint8, compu {phys=raw}, range phys 0..252
          signal StatusUWBRangingFDD2FBD_HR_IndexResponder9: start 120, 8 bit, little-endian, data-type-policy=OVERRIDE, base-type=uint8, compu {phys=raw}, range phys 0..252
          signal StatusUWBRangingFDD2FBD_HR_TimeStampResponder9: start 128, 32 bit, little-endian, data-type-policy=OVERRIDE, base-type=uint32, compu {phys=raw}, range phys 0..4294967292
          signal StatusUWBRangingFDD2FBD_HR_TimeStampUncertaintyResponder9: start 160, 8 bit, little-endian, data-type-policy=OVERRIDE, base-type=uint8, compu {phys=raw}, range phys 0..252
          signal StatusUWBRangingFDD2FBD_HR_StatusResponder9: start 168, 8 bit, little-endian, data-type-policy=OVERRIDE, base-type=uint8, compu {phys=raw}, range phys 0..252
          signal StatusUWBRangingFDD2FBD_HR_IndexResponder10: start 176, 8 bit, little-endian, data-type-policy=OVERRIDE, base-type=uint8, compu {phys=raw}, range phys 0..252
          signal StatusUWBRangingFDD2FBD_HR_TimeStampResponder10: start 184, 32 bit, little-endian, data-type-policy=OVERRIDE, base-type=uint32, compu {phys=raw}, range phys 0..4294967292
          signal StatusUWBRangingFDD2FBD_HR_TimeStampUncertaintyResponder10: start 216, 8 bit, little-endian, data-type-policy=OVERRIDE, base-type=uint8, compu {phys=raw}, range phys 0..252
          signal StatusUWBRangingFDD2FBD_HR_StatusResponder10: start 224, 8 bit, little-endian, data-type-policy=OVERRIDE, base-type=uint8, compu {phys=raw}, range phys 0..252
          signal StatusUWBRangingFDD2FBD_HR_TimeStampPoll: start 232, 64 bit, little-endian, data-type-policy=OVERRIDE, base-type=uint64, compu {phys=raw}, range phys 0..18446744073709551612
          signal StatusUWBRangingFDD2FBD_HR_Signature: start 296, 64 bit, little-endian, data-type-policy=OVERRIDE, base-type=uint64, compu {phys=raw}, range phys 0..18446744073709551614
          signal StatusUWBRangingFDD2FBD_HR_IV2: start 360, 8 bit, little-endian, data-type-policy=OVERRIDE, base-type=uint8, compu {phys=raw}, range phys 0..255
          signal StatusUWBRangingFDD2FBD_HR_IV3: start 368, 8 bit, little-endian, data-type-policy=OVERRIDE, base-type=uint8, compu {phys=raw}, range phys 0..255
      frame StatusUWBRangingFDD2FBD_Miko: id 0x1CE, frame-length=48, can-addressing-mode=STANDARD, can-frame-rx-behavior=CAN-FD, can-frame-tx-behavior=CAN-FD
        pdu StatusUWBRangingFDD2FBD_Miko: length=48, unused-bit-pattern=0
          signal StatusUWBRangingFDD2FBD_Miko_SessionIDShort: start 0, 8 bit, little-endian, data-type-policy=OVERRIDE, base-type=uint8, compu {phys=raw}, range phys 0..252
          signal StatusUWBRangingFDD2FBD_Miko_IndexResponder7: start 8, 8 bit, little-endian, data-type-policy=OVERRIDE, base-type=uint8, compu {phys=raw}, range phys 0..252
          signal StatusUWBRangingFDD2FBD_Miko_TimeStampResponder7: start 16, 32 bit, little-endian, data-type-policy=OVERRIDE, base-type=uint32, compu {phys=raw}, range phys 0..4294967292
          signal StatusUWBRangingFDD2FBD_Miko_TimeStampUncertaintyResponder7: start 48, 8 bit, little-endian, data-type-policy=OVERRIDE, base-type=uint8, compu {phys=raw}, range phys 0..252
          signal StatusUWBRangingFDD2FBD_Miko_StatusResponder7: start 56, 8 bit, little-endian, data-type-policy=OVERRIDE, base-type=uint8, compu {phys=raw}, range phys 0..252
          signal StatusUWBRangingFDD2FBD_Miko_IndexResponder8: start 64, 8 bit, little-endian, data-type-policy=OVERRIDE, base-type=uint8, compu {phys=raw}, range phys 0..252
          signal StatusUWBRangingFDD2FBD_Miko_TimeStampResponder8: start 72, 32 bit, little-endian, data-type-policy=OVERRIDE, base-type=uint32, compu {phys=raw}, range phys 0..4294967292
          signal StatusUWBRangingFDD2FBD_Miko_TimeStampUncertaintyResponder8: start 104, 8 bit, little-endian, data-type-policy=OVERRIDE, base-type=uint8, compu {phys=raw}, range phys 0..252
          signal StatusUWBRangingFDD2FBD_Miko_StatusResponder8: start 112, 8 bit, little-endian, data-type-policy=OVERRIDE, base-type=uint8, compu {phys=raw}, range phys 0..252
          signal StatusUWBRangingFDD2FBD_Miko_IndexResponder9: start 120, 8 bit, little-endian, data-type-policy=OVERRIDE, base-type=uint8, compu {phys=raw}, range phys 0..252
          signal StatusUWBRangingFDD2FBD_Miko_TimeStampResponder9: start 128, 32 bit, little-endian, data-type-policy=OVERRIDE, base-type=uint32, compu {phys=raw}, range phys 0..4294967292
          signal StatusUWBRangingFDD2FBD_Miko_TimeStampUncertaintyResponder9: start 160, 8 bit, little-endian, data-type-policy=OVERRIDE, base-type=uint8, compu {phys=raw}, range phys 0..252
          signal StatusUWBRangingFDD2FBD_Miko_StatusResponder9: start 168, 8 bit, little-endian, data-type-policy=OVERRIDE, base-type=uint8, compu {phys=raw}, range phys 0..252
          signal StatusUWBRangingFDD2FBD_Miko_IndexResponder10: start 176, 8 bit, little-endian, data-type-policy=OVERRIDE, base-type=uint8, compu {phys=raw}, range phys 0..252
          signal StatusUWBRangingFDD2FBD_Miko_TimeStampResponder10: start 184, 32 bit, little-endian, data-type-policy=OVERRIDE, base-type=uint32, compu {phys=raw}, range phys 0..4294967292
          signal StatusUWBRangingFDD2FBD_Miko_TimeStampUncertaintyResponder10: start 216, 8 bit, little-endian, data-type-policy=OVERRIDE, base-type=uint8, compu {phys=raw}, range phys 0..252
          signal StatusUWBRangingFDD2FBD_Miko_StatusResponder10: start 224, 8 bit, little-endian, data-type-policy=OVERRIDE, base-type=uint8, compu {phys=raw}, range phys 0..252
          signal StatusUWBRangingFDD2FBD_Miko_TimeStampPoll: start 232, 64 bit, little-endian, data-type-policy=OVERRIDE, base-type=uint64, compu {phys=raw}, range phys 0..18446744073709551612
          signal StatusUWBRangingFDD2FBD_Miko_Signature: start 296, 64 bit, little-endian, data-type-policy=OVERRIDE, base-type=uint64, compu {phys=raw}, range phys 0..18446744073709551614
          signal StatusUWBRangingFDD2FBD_Miko_IV2: start 360, 8 bit, little-endian, data-type-policy=OVERRIDE, base-type=uint8, compu {phys=raw}, range phys 0..255
          signal StatusUWBRangingFDD2FBD_Miko_IV3: start 368, 8 bit, little-endian, data-type-policy=OVERRIDE, base-type=uint8, compu {phys=raw}, range phys 0..255
      frame StatusUWBRangingFDD2FBD_MM: id 0x1BD, frame-length=48, can-addressing-mode=STANDARD, can-frame-rx-behavior=CAN-FD, can-frame-tx-behavior=CAN-FD
        pdu StatusUWBRangingFDD2FBD_MM: length=48, unused-bit-pattern=0
          signal StatusUWBRangingFDD2FBD_MM_SessionIDShort: start 0, 8 bit, little-endian, data-type-policy=OVERRIDE, base-type=uint8, compu {phys=raw}, range phys 0..252
          signal StatusUWBRangingFDD2FBD_MM_IndexResponder7: start 8, 8 bit, little-endian, data-type-policy=OVERRIDE, base-type=uint8, compu {phys=raw}, range phys 0..252
          signal StatusUWBRangingFDD2FBD_MM_TimeStampResponder7: start 16, 32 bit, little-endian, data-type-policy=OVERRIDE, base-type=uint32, compu {phys=raw}, range phys 0..4294967292
          signal StatusUWBRangingFDD2FBD_MM_TimeStampUncertaintyResponder7: start 48, 8 bit, little-endian, data-type-policy=OVERRIDE, base-type=uint8, compu {phys=raw}, range phys 0..252
          signal StatusUWBRangingFDD2FBD_MM_StatusResponder7: start 56, 8 bit, little-endian, data-type-policy=OVERRIDE, base-type=uint8, compu {phys=raw}, range phys 0..252
          signal StatusUWBRangingFDD2FBD_MM_IndexResponder8: start 64, 8 bit, little-endian, data-type-policy=OVERRIDE, base-type=uint8, compu {phys=raw}, range phys 0..252
          signal StatusUWBRangingFDD2FBD_MM_TimeStampResponder8: start 72, 32 bit, little-endian, data-type-policy=OVERRIDE, base-type=uint32, compu {phys=raw}, range phys 0..4294967292
          signal StatusUWBRangingFDD2FBD_MM_TimeStampUncertaintyResponder8: start 104, 8 bit, little-endian, data-type-policy=OVERRIDE, base-type=uint8, compu {phys=raw}, range phys 0..252
          signal StatusUWBRangingFDD2FBD_MM_StatusResponder8: start 112, 8 bit, little-endian, data-type-policy=OVERRIDE, base-type=uint8, compu {phys=raw}, range phys 0..252
          signal StatusUWBRangingFDD2FBD_MM_IndexResponder9: start 120, 8 bit, little-endian, data-type-policy=OVERRIDE, base-type=uint8, compu {phys=raw}, range phys 0..252
          signal StatusUWBRangingFDD2FBD_MM_TimeStampResponder9: start 128, 32 bit, little-endian, data-type-policy=OVERRIDE, base-type=uint32, compu {phys=raw}, range phys 0..4294967292
          signal StatusUWBRangingFDD2FBD_MM_TimeStampUncertaintyResponder9: start 160, 8 bit, little-endian, data-type-policy=OVERRIDE, base-type=uint8, compu {phys=raw}, range phys 0..252
          signal StatusUWBRangingFDD2FBD_MM_StatusResponder9: start 168, 8 bit, little-endian, data-type-policy=OVERRIDE, base-type=uint8, compu {phys=raw}, range phys 0..252
          signal StatusUWBRangingFDD2FBD_MM_IndexResponder10: start 176, 8 bit, little-endian, data-type-policy=OVERRIDE, base-type=uint8, compu {phys=raw}, range phys 0..252
          signal StatusUWBRangingFDD2FBD_MM_TimeStampResponder10: start 184, 32 bit, little-endian, data-type-policy=OVERRIDE, base-type=uint32, compu {phys=raw}, range phys 0..4294967292
          signal StatusUWBRangingFDD2FBD_MM_TimeStampUncertaintyResponder10: start 216, 8 bit, little-endian, data-type-policy=OVERRIDE, base-type=uint8, compu {phys=raw}, range phys 0..252
          signal StatusUWBRangingFDD2FBD_MM_StatusResponder10: start 224, 8 bit, little-endian, data-type-policy=OVERRIDE, base-type=uint8, compu {phys=raw}, range phys 0..252
          signal StatusUWBRangingFDD2FBD_MM_TimeStampPoll: start 232, 64 bit, little-endian, data-type-policy=OVERRIDE, base-type=uint64, compu {phys=raw}, range phys 0..18446744073709551612
          signal StatusUWBRangingFDD2FBD_MM_Signature: start 296, 64 bit, little-endian, data-type-policy=OVERRIDE, base-type=uint64, compu {phys=raw}, range phys 0..18446744073709551614
          signal StatusUWBRangingFDD2FBD_MM_IV2: start 360, 8 bit, little-endian, data-type-policy=OVERRIDE, base-type=uint8, compu {phys=raw}, range phys 0..255
          signal StatusUWBRangingFDD2FBD_MM_IV3: start 368, 8 bit, little-endian, data-type-policy=OVERRIDE, base-type=uint8, compu {phys=raw}, range phys 0..255
      frame StatusUWBRangingFDD2FBD_SML: id 0x1D4, frame-length=48, can-addressing-mode=STANDARD, can-frame-rx-behavior=CAN-FD, can-frame-tx-behavior=CAN-FD
        pdu StatusUWBRangingFDD2FBD_SML: length=48, unused-bit-pattern=0
          signal StatusUWBRangingFDD2FBD_SML_SessionIDShort: start 0, 8 bit, little-endian, data-type-policy=OVERRIDE, base-type=uint8, compu {phys=raw}, range phys 0..252
          signal StatusUWBRangingFDD2FBD_SML_IndexResponder7: start 8, 8 bit, little-endian, data-type-policy=OVERRIDE, base-type=uint8, compu {phys=raw}, range phys 0..252
          signal StatusUWBRangingFDD2FBD_SML_TimeStampResponder7: start 16, 32 bit, little-endian, data-type-policy=OVERRIDE, base-type=uint32, compu {phys=raw}, range phys 0..4294967292
          signal StatusUWBRangingFDD2FBD_SML_TimeStampUncertaintyResponder7: start 48, 8 bit, little-endian, data-type-policy=OVERRIDE, base-type=uint8, compu {phys=raw}, range phys 0..252
          signal StatusUWBRangingFDD2FBD_SML_StatusResponder7: start 56, 8 bit, little-endian, data-type-policy=OVERRIDE, base-type=uint8, compu {phys=raw}, range phys 0..252
          signal StatusUWBRangingFDD2FBD_SML_IndexResponder8: start 64, 8 bit, little-endian, data-type-policy=OVERRIDE, base-type=uint8, compu {phys=raw}, range phys 0..252
          signal StatusUWBRangingFDD2FBD_SML_TimeStampResponder8: start 72, 32 bit, little-endian, data-type-policy=OVERRIDE, base-type=uint32, compu {phys=raw}, range phys 0..4294967292
          signal StatusUWBRangingFDD2FBD_SML_TimeStampUncertaintyResponder8: start 104, 8 bit, little-endian, data-type-policy=OVERRIDE, base-type=uint8, compu {phys=raw}, range phys 0..252
          signal StatusUWBRangingFDD2FBD_SML_StatusResponder8: start 112, 8 bit, little-endian, data-type-policy=OVERRIDE, base-type=uint8, compu {phys=raw}, range phys 0..252
          signal StatusUWBRangingFDD2FBD_SML_IndexResponder9: start 120, 8 bit, little-endian, data-type-policy=OVERRIDE, base-type=uint8, compu {phys=raw}, range phys 0..252
          signal StatusUWBRangingFDD2FBD_SML_TimeStampResponder9: start 128, 32 bit, little-endian, data-type-policy=OVERRIDE, base-type=uint32, compu {phys=raw}, range phys 0..4294967292
          signal StatusUWBRangingFDD2FBD_SML_TimeStampUncertaintyResponder9: start 160, 8 bit, little-endian, data-type-policy=OVERRIDE, base-type=uint8, compu {phys=raw}, range phys 0..252
          signal StatusUWBRangingFDD2FBD_SML_StatusResponder9: start 168, 8 bit, little-endian, data-type-policy=OVERRIDE, base-type=uint8, compu {phys=raw}, range phys 0..252
          signal StatusUWBRangingFDD2FBD_SML_IndexResponder10: start 176, 8 bit, little-endian, data-type-policy=OVERRIDE, base-type=uint8, compu {phys=raw}, range phys 0..252
          signal StatusUWBRangingFDD2FBD_SML_TimeStampResponder10: start 184, 32 bit, little-endian, data-type-policy=OVERRIDE, base-type=uint32, compu {phys=raw}, range phys 0..4294967292
          signal StatusUWBRangingFDD2FBD_SML_TimeStampUncertaintyResponder10: start 216, 8 bit, little-endian, data-type-policy=OVERRIDE, base-type=uint8, compu {phys=raw}, range phys 0..252
          signal StatusUWBRangingFDD2FBD_SML_StatusResponder10: start 224, 8 bit, little-endian, data-type-policy=OVERRIDE, base-type=uint8, compu {phys=raw}, range phys 0..252
          signal StatusUWBRangingFDD2FBD_SML_TimeStampPoll: start 232, 64 bit, little-endian, data-type-policy=OVERRIDE, base-type=uint64, compu {phys=raw}, range phys 0..18446744073709551612
          signal StatusUWBRangingFDD2FBD_SML_Signature: start 296, 64 bit, little-endian, data-type-policy=OVERRIDE, base-type=uint64, compu {phys=raw}, range phys 0..18446744073709551614
          signal StatusUWBRangingFDD2FBD_SML_IV2: start 360, 8 bit, little-endian, data-type-policy=OVERRIDE, base-type=uint8, compu {phys=raw}, range phys 0..255
          signal StatusUWBRangingFDD2FBD_SML_IV3: start 368, 8 bit, little-endian, data-type-policy=OVERRIDE, base-type=uint8, compu {phys=raw}, range phys 0..255
      frame StatusUWBRangingFDD2FBD_SMR: id 0x1D5, frame-length=48, can-addressing-mode=STANDARD, can-frame-rx-behavior=CAN-FD, can-frame-tx-behavior=CAN-FD
        pdu StatusUWBRangingFDD2FBD_SMR: length=48, unused-bit-pattern=0
          signal StatusUWBRangingFDD2FBD_SMR_SessionIDShort: start 0, 8 bit, little-endian, data-type-policy=OVERRIDE, base-type=uint8, compu {phys=raw}, range phys 0..252
          signal StatusUWBRangingFDD2FBD_SMR_IndexResponder7: start 8, 8 bit, little-endian, data-type-policy=OVERRIDE, base-type=uint8, compu {phys=raw}, range phys 0..252
          signal StatusUWBRangingFDD2FBD_SMR_TimeStampResponder7: start 16, 32 bit, little-endian, data-type-policy=OVERRIDE, base-type=uint32, compu {phys=raw}, range phys 0..4294967292
          signal StatusUWBRangingFDD2FBD_SMR_TimeStampUncertaintyResponder7: start 48, 8 bit, little-endian, data-type-policy=OVERRIDE, base-type=uint8, compu {phys=raw}, range phys 0..252
          signal StatusUWBRangingFDD2FBD_SMR_StatusResponder7: start 56, 8 bit, little-endian, data-type-policy=OVERRIDE, base-type=uint8, compu {phys=raw}, range phys 0..252
          signal StatusUWBRangingFDD2FBD_SMR_IndexResponder8: start 64, 8 bit, little-endian, data-type-policy=OVERRIDE, base-type=uint8, compu {phys=raw}, range phys 0..252
          signal StatusUWBRangingFDD2FBD_SMR_TimeStampResponder8: start 72, 32 bit, little-endian, data-type-policy=OVERRIDE, base-type=uint32, compu {phys=raw}, range phys 0..4294967292
          signal StatusUWBRangingFDD2FBD_SMR_TimeStampUncertaintyResponder8: start 104, 8 bit, little-endian, data-type-policy=OVERRIDE, base-type=uint8, compu {phys=raw}, range phys 0..252
          signal StatusUWBRangingFDD2FBD_SMR_StatusResponder8: start 112, 8 bit, little-endian, data-type-policy=OVERRIDE, base-type=uint8, compu {phys=raw}, range phys 0..252
          signal StatusUWBRangingFDD2FBD_SMR_IndexResponder9: start 120, 8 bit, little-endian, data-type-policy=OVERRIDE, base-type=uint8, compu {phys=raw}, range phys 0..252
          signal StatusUWBRangingFDD2FBD_SMR_TimeStampResponder9: start 128, 32 bit, little-endian, data-type-policy=OVERRIDE, base-type=uint32, compu {phys=raw}, range phys 0..4294967292
          signal StatusUWBRangingFDD2FBD_SMR_TimeStampUncertaintyResponder9: start 160, 8 bit, little-endian, data-type-policy=OVERRIDE, base-type=uint8, compu {phys=raw}, range phys 0..252
          signal StatusUWBRangingFDD2FBD_SMR_StatusResponder9: start 168, 8 bit, little-endian, data-type-policy=OVERRIDE, base-type=uint8, compu {phys=raw}, range phys 0..252
          signal StatusUWBRangingFDD2FBD_SMR_IndexResponder10: start 176, 8 bit, little-endian, data-type-policy=OVERRIDE, base-type=uint8, compu {phys=raw}, range phys 0..252
          signal StatusUWBRangingFDD2FBD_SMR_TimeStampResponder10: start 184, 32 bit, little-endian, data-type-policy=OVERRIDE, base-type=uint32, compu {phys=raw}, range phys 0..4294967292
          signal StatusUWBRangingFDD2FBD_SMR_TimeStampUncertaintyResponder10: start 216, 8 bit, little-endian, data-type-policy=OVERRIDE, base-type=uint8, compu {phys=raw}, range phys 0..252
          signal StatusUWBRangingFDD2FBD_SMR_StatusResponder10: start 224, 8 bit, little-endian, data-type-policy=OVERRIDE, base-type=uint8, compu {phys=raw}, range phys 0..252
          signal StatusUWBRangingFDD2FBD_SMR_TimeStampPoll: start 232, 64 bit, little-endian, data-type-policy=OVERRIDE, base-type=uint64, compu {phys=raw}, range phys 0..18446744073709551612
          signal StatusUWBRangingFDD2FBD_SMR_Signature: start 296, 64 bit, little-endian, data-type-policy=OVERRIDE, base-type=uint64, compu {phys=raw}, range phys 0..18446744073709551614
          signal StatusUWBRangingFDD2FBD_SMR_IV2: start 360, 8 bit, little-endian, data-type-policy=OVERRIDE, base-type=uint8, compu {phys=raw}, range phys 0..255
          signal StatusUWBRangingFDD2FBD_SMR_IV3: start 368, 8 bit, little-endian, data-type-policy=OVERRIDE, base-type=uint8, compu {phys=raw}, range phys 0..255
      frame StatusUWBRangingFDD2FBD_Trunk: id 0x1CF, frame-length=48, can-addressing-mode=STANDARD, can-frame-rx-behavior=CAN-FD, can-frame-tx-behavior=CAN-FD
        pdu StatusUWBRangingFDD2FBD_Trunk: length=48, unused-bit-pattern=0
          signal StatusUWBRangingFDD2FBD_Trunk_SessionIDShort: start 0, 8 bit, little-endian, data-type-policy=OVERRIDE, base-type=uint8, compu {phys=raw}, range phys 0..252
          signal StatusUWBRangingFDD2FBD_Trunk_IndexResponder7: start 8, 8 bit, little-endian, data-type-policy=OVERRIDE, base-type=uint8, compu {phys=raw}, range phys 0..252
          signal StatusUWBRangingFDD2FBD_Trunk_TimeStampResponder7: start 16, 32 bit, little-endian, data-type-policy=OVERRIDE, base-type=uint32, compu {phys=raw}, range phys 0..4294967292
          signal StatusUWBRangingFDD2FBD_Trunk_TimeStampUncertaintyResponder7: start 48, 8 bit, little-endian, data-type-policy=OVERRIDE, base-type=uint8, compu {phys=raw}, range phys 0..252
          signal StatusUWBRangingFDD2FBD_Trunk_StatusResponder7: start 56, 8 bit, little-endian, data-type-policy=OVERRIDE, base-type=uint8, compu {phys=raw}, range phys 0..252
          signal StatusUWBRangingFDD2FBD_Trunk_IndexResponder8: start 64, 8 bit, little-endian, data-type-policy=OVERRIDE, base-type=uint8, compu {phys=raw}, range phys 0..252
          signal StatusUWBRangingFDD2FBD_Trunk_TimeStampResponder8: start 72, 32 bit, little-endian, data-type-policy=OVERRIDE, base-type=uint32, compu {phys=raw}, range phys 0..4294967292
          signal StatusUWBRangingFDD2FBD_Trunk_TimeStampUncertaintyResponder8: start 104, 8 bit, little-endian, data-type-policy=OVERRIDE, base-type=uint8, compu {phys=raw}, range phys 0..252
          signal StatusUWBRangingFDD2FBD_Trunk_StatusResponder8: start 112, 8 bit, little-endian, data-type-policy=OVERRIDE, base-type=uint8, compu {phys=raw}, range phys 0..252
          signal StatusUWBRangingFDD2FBD_Trunk_IndexResponder9: start 120, 8 bit, little-endian, data-type-policy=OVERRIDE, base-type=uint8, compu {phys=raw}, range phys 0..252
          signal StatusUWBRangingFDD2FBD_Trunk_TimeStampResponder9: start 128, 32 bit, little-endian, data-type-policy=OVERRIDE, base-type=uint32, compu {phys=raw}, range phys 0..4294967292
          signal StatusUWBRangingFDD2FBD_Trunk_TimeStampUncertaintyResponder9: start 160, 8 bit, little-endian, data-type-policy=OVERRIDE, base-type=uint8, compu {phys=raw}, range phys 0..252
          signal StatusUWBRangingFDD2FBD_Trunk_StatusResponder9: start 168, 8 bit, little-endian, data-type-policy=OVERRIDE, base-type=uint8, compu {phys=raw}, range phys 0..252
          signal StatusUWBRangingFDD2FBD_Trunk_IndexResponder10: start 176, 8 bit, little-endian, data-type-policy=OVERRIDE, base-type=uint8, compu {phys=raw}, range phys 0..252
          signal StatusUWBRangingFDD2FBD_Trunk_TimeStampResponder10: start 184, 32 bit, little-endian, data-type-policy=OVERRIDE, base-type=uint32, compu {phys=raw}, range phys 0..4294967292
          signal StatusUWBRangingFDD2FBD_Trunk_TimeStampUncertaintyResponder10: start 216, 8 bit, little-endian, data-type-policy=OVERRIDE, base-type=uint8, compu {phys=raw}, range phys 0..252
          signal StatusUWBRangingFDD2FBD_Trunk_StatusResponder10: start 224, 8 bit, little-endian, data-type-policy=OVERRIDE, base-type=uint8, compu {phys=raw}, range phys 0..252
          signal StatusUWBRangingFDD2FBD_Trunk_TimeStampPoll: start 232, 64 bit, little-endian, data-type-policy=OVERRIDE, base-type=uint64, compu {phys=raw}, range phys 0..18446744073709551612
          signal StatusUWBRangingFDD2FBD_Trunk_Signature: start 296, 64 bit, little-endian, data-type-policy=OVERRIDE, base-type=uint64, compu {phys=raw}, range phys 0..18446744073709551614
          signal StatusUWBRangingFDD2FBD_Trunk_IV2: start 360, 8 bit, little-endian, data-type-policy=OVERRIDE, base-type=uint8, compu {phys=raw}, range phys 0..255
          signal StatusUWBRangingFDD2FBD_Trunk_IV3: start 368, 8 bit, little-endian, data-type-policy=OVERRIDE, base-type=uint8, compu {phys=raw}, range phys 0..255
      frame StatusUWBRangingFDD2FBD_VL: id 0x1D0, frame-length=48, can-addressing-mode=STANDARD, can-frame-rx-behavior=CAN-FD, can-frame-tx-behavior=CAN-FD
        pdu StatusUWBRangingFDD2FBD_VL: length=48, unused-bit-pattern=0
          signal StatusUWBRangingFDD2FBD_VL_SessionIDShort: start 0, 8 bit, little-endian, data-type-policy=OVERRIDE, base-type=uint8, compu {phys=raw}, range phys 0..252
          signal StatusUWBRangingFDD2FBD_VL_IndexResponder7: start 8, 8 bit, little-endian, data-type-policy=OVERRIDE, base-type=uint8, compu {phys=raw}, range phys 0..252
          signal StatusUWBRangingFDD2FBD_VL_TimeStampResponder7: start 16, 32 bit, little-endian, data-type-policy=OVERRIDE, base-type=uint32, compu {phys=raw}, range phys 0..4294967292
          signal StatusUWBRangingFDD2FBD_VL_TimeStampUncertaintyResponder7: start 48, 8 bit, little-endian, data-type-policy=OVERRIDE, base-type=uint8, compu {phys=raw}, range phys 0..252
          signal StatusUWBRangingFDD2FBD_VL_StatusResponder7: start 56, 8 bit, little-endian, data-type-policy=OVERRIDE, base-type=uint8, compu {phys=raw}, range phys 0..252
          signal StatusUWBRangingFDD2FBD_VL_IndexResponder8: start 64, 8 bit, little-endian, data-type-policy=OVERRIDE, base-type=uint8, compu {phys=raw}, range phys 0..252
          signal StatusUWBRangingFDD2FBD_VL_TimeStampResponder8: start 72, 32 bit, little-endian, data-type-policy=OVERRIDE, base-type=uint32, compu {phys=raw}, range phys 0..4294967292
          signal StatusUWBRangingFDD2FBD_VL_TimeStampUncertaintyResponder8: start 104, 8 bit, little-endian, data-type-policy=OVERRIDE, base-type=uint8, compu {phys=raw}, range phys 0..252
          signal StatusUWBRangingFDD2FBD_VL_StatusResponder8: start 112, 8 bit, little-endian, data-type-policy=OVERRIDE, base-type=uint8, compu {phys=raw}, range phys 0..252
          signal StatusUWBRangingFDD2FBD_VL_IndexResponder9: start 120, 8 bit, little-endian, data-type-policy=OVERRIDE, base-type=uint8, compu {phys=raw}, range phys 0..252
          signal StatusUWBRangingFDD2FBD_VL_TimeStampResponder9: start 128, 32 bit, little-endian, data-type-policy=OVERRIDE, base-type=uint32, compu {phys=raw}, range phys 0..4294967292
          signal StatusUWBRangingFDD2FBD_VL_TimeStampUncertaintyResponder9: start 160, 8 bit, little-endian, data-type-policy=OVERRIDE, base-type=uint8, compu {phys=raw}, range phys 0..252
          signal StatusUWBRangingFDD2FBD_VL_StatusResponder9: start 168, 8 bit, little-endian, data-type-policy=OVERRIDE, base-type=uint8, compu {phys=raw}, range phys 0..252
          signal StatusUWBRangingFDD2FBD_VL_IndexResponder10: start 176, 8 bit, little-endian, data-type-policy=OVERRIDE, base-type=uint8, compu {phys=raw}, range phys 0..252
          signal StatusUWBRangingFDD2FBD_VL_TimeStampResponder10: start 184, 32 bit, little-endian, data-type-policy=OVERRIDE, base-type=uint32, compu {phys=raw}, range phys 0..4294967292
          signal StatusUWBRangingFDD2FBD_VL_TimeStampUncertaintyResponder10: start 216, 8 bit, little-endian, data-type-policy=OVERRIDE, base-type=uint8, compu {phys=raw}, range phys 0..252
          signal StatusUWBRangingFDD2FBD_VL_StatusResponder10: start 224, 8 bit, little-endian, data-type-policy=OVERRIDE, base-type=uint8, compu {phys=raw}, range phys 0..252
          signal StatusUWBRangingFDD2FBD_VL_TimeStampPoll: start 232, 64 bit, little-endian, data-type-policy=OVERRIDE, base-type=uint64, compu {phys=raw}, range phys 0..18446744073709551612
          signal StatusUWBRangingFDD2FBD_VL_Signature: start 296, 64 bit, little-endian, data-type-policy=OVERRIDE, base-type=uint64, compu {phys=raw}, range phys 0..18446744073709551614
          signal StatusUWBRangingFDD2FBD_VL_IV2: start 360, 8 bit, little-endian, data-type-policy=OVERRIDE, base-type=uint8, compu {phys=raw}, range phys 0..255
          signal StatusUWBRangingFDD2FBD_VL_IV3: start 368, 8 bit, little-endian, data-type-policy=OVERRIDE, base-type=uint8, compu {phys=raw}, range phys 0..255
      frame StatusUWBRangingFDD2FBD_VM: id 0x1CC, frame-length=48, can-addressing-mode=STANDARD, can-frame-rx-behavior=CAN-FD, can-frame-tx-behavior=CAN-FD
        pdu StatusUWBRangingFDD2FBD_VM: length=48, unused-bit-pattern=0
          signal StatusUWBRangingFDD2FBD_VM_SessionIDShort: start 0, 8 bit, little-endian, data-type-policy=OVERRIDE, base-type=uint8, compu {phys=raw}, range phys 0..252
          signal StatusUWBRangingFDD2FBD_VM_IndexResponder7: start 8, 8 bit, little-endian, data-type-policy=OVERRIDE, base-type=uint8, compu {phys=raw}, range phys 0..252
          signal StatusUWBRangingFDD2FBD_VM_TimeStampResponder7: start 16, 32 bit, little-endian, data-type-policy=OVERRIDE, base-type=uint32, compu {phys=raw}, range phys 0..4294967292
          signal StatusUWBRangingFDD2FBD_VM_TimeStampUncertaintyResponder7: start 48, 8 bit, little-endian, data-type-policy=OVERRIDE, base-type=uint8, compu {phys=raw}, range phys 0..252
          signal StatusUWBRangingFDD2FBD_VM_StatusResponder7: start 56, 8 bit, little-endian, data-type-policy=OVERRIDE, base-type=uint8, compu {phys=raw}, range phys 0..252
          signal StatusUWBRangingFDD2FBD_VM_IndexResponder8: start 64, 8 bit, little-endian, data-type-policy=OVERRIDE, base-type=uint8, compu {phys=raw}, range phys 0..252
          signal StatusUWBRangingFDD2FBD_VM_TimeStampResponder8: start 72, 32 bit, little-endian, data-type-policy=OVERRIDE, base-type=uint32, compu {phys=raw}, range phys 0..4294967292
          signal StatusUWBRangingFDD2FBD_VM_TimeStampUncertaintyResponder8: start 104, 8 bit, little-endian, data-type-policy=OVERRIDE, base-type=uint8, compu {phys=raw}, range phys 0..252
          signal StatusUWBRangingFDD2FBD_VM_StatusResponder8: start 112, 8 bit, little-endian, data-type-policy=OVERRIDE, base-type=uint8, compu {phys=raw}, range phys 0..252
          signal StatusUWBRangingFDD2FBD_VM_IndexResponder9: start 120, 8 bit, little-endian, data-type-policy=OVERRIDE, base-type=uint8, compu {phys=raw}, range phys 0..252
          signal StatusUWBRangingFDD2FBD_VM_TimeStampResponder9: start 128, 32 bit, little-endian, data-type-policy=OVERRIDE, base-type=uint32, compu {phys=raw}, range phys 0..4294967292
          signal StatusUWBRangingFDD2FBD_VM_TimeStampUncertaintyResponder9: start 160, 8 bit, little-endian, data-type-policy=OVERRIDE, base-type=uint8, compu {phys=raw}, range phys 0..252
          signal StatusUWBRangingFDD2FBD_VM_StatusResponder9: start 168, 8 bit, little-endian, data-type-policy=OVERRIDE, base-type=uint8, compu {phys=raw}, range phys 0..252
          signal StatusUWBRangingFDD2FBD_VM_IndexResponder10: start 176, 8 bit, little-endian, data-type-policy=OVERRIDE, base-type=uint8, compu {phys=raw}, range phys 0..252
          signal StatusUWBRangingFDD2FBD_VM_TimeStampResponder10: start 184, 32 bit, little-endian, data-type-policy=OVERRIDE, base-type=uint32, compu {phys=raw}, range phys 0..4294967292
          signal StatusUWBRangingFDD2FBD_VM_TimeStampUncertaintyResponder10: start 216, 8 bit, little-endian, data-type-policy=OVERRIDE, base-type=uint8, compu {phys=raw}, range phys 0..252
          signal StatusUWBRangingFDD2FBD_VM_StatusResponder10: start 224, 8 bit, little-endian, data-type-policy=OVERRIDE, base-type=uint8, compu {phys=raw}, range phys 0..252
          signal StatusUWBRangingFDD2FBD_VM_TimeStampPoll: start 232, 64 bit, little-endian, data-type-policy=OVERRIDE, base-type=uint64, compu {phys=raw}, range phys 0..18446744073709551612
          signal StatusUWBRangingFDD2FBD_VM_Signature: start 296, 64 bit, little-endian, data-type-policy=OVERRIDE, base-type=uint64, compu {phys=raw}, range phys 0..18446744073709551614
          signal StatusUWBRangingFDD2FBD_VM_IV2: start 360, 8 bit, little-endian, data-type-policy=OVERRIDE, base-type=uint8, compu {phys=raw}, range phys 0..255
          signal StatusUWBRangingFDD2FBD_VM_IV3: start 368, 8 bit, little-endian, data-type-policy=OVERRIDE, base-type=uint8, compu {phys=raw}, range phys 0..255
      frame StatusUWBRangingFDD2FBD_VR: id 0x1D1, frame-length=48, can-addressing-mode=STANDARD, can-frame-rx-behavior=CAN-FD, can-frame-tx-behavior=CAN-FD
        pdu StatusUWBRangingFDD2FBD_VR: length=48, unused-bit-pattern=0
          signal StatusUWBRangingFDD2FBD_VR_SessionIDShort: start 0, 8 bit, little-endian, data-type-policy=OVERRIDE, base-type=uint8, compu {phys=raw}, range phys 0..252
          signal StatusUWBRangingFDD2FBD_VR_IndexResponder7: start 8, 8 bit, little-endian, data-type-policy=OVERRIDE, base-type=uint8, compu {phys=raw}, range phys 0..252
          signal StatusUWBRangingFDD2FBD_VR_TimeStampResponder7: start 16, 32 bit, little-endian, data-type-policy=OVERRIDE, base-type=uint32, compu {phys=raw}, range phys 0..4294967292
          signal StatusUWBRangingFDD2FBD_VR_TimeStampUncertaintyResponder7: start 48, 8 bit, little-endian, data-type-policy=OVERRIDE, base-type=uint8, compu {phys=raw}, range phys 0..252
          signal StatusUWBRangingFDD2FBD_VR_StatusResponder7: start 56, 8 bit, little-endian, data-type-policy=OVERRIDE, base-type=uint8, compu {phys=raw}, range phys 0..252
          signal StatusUWBRangingFDD2FBD_VR_IndexResponder8: start 64, 8 bit, little-endian, data-type-policy=OVERRIDE, base-type=uint8, compu {phys=raw}, range phys 0..252
          signal StatusUWBRangingFDD2FBD_VR_TimeStampResponder8: start 72, 32 bit, little-endian, data-type-policy=OVERRIDE, base-type=uint32, compu {phys=raw}, range phys 0..4294967292
          signal StatusUWBRangingFDD2FBD_VR_TimeStampUncertaintyResponder8: start 104, 8 bit, little-endian, data-type-policy=OVERRIDE, base-type=uint8, compu {phys=raw}, range phys 0..252
          signal StatusUWBRangingFDD2FBD_VR_StatusResponder8: start 112, 8 bit, little-endian, data-type-policy=OVERRIDE, base-type=uint8, compu {phys=raw}, range phys 0..252
          signal StatusUWBRangingFDD2FBD_VR_IndexResponder9: start 120, 8 bit, little-endian, data-type-policy=OVERRIDE, base-type=uint8, compu {phys=raw}, range phys 0..252
          signal StatusUWBRangingFDD2FBD_VR_TimeStampResponder9: start 128, 32 bit, little-endian, data-type-policy=OVERRIDE, base-type=uint32, compu {phys=raw}, range phys 0..4294967292
          signal StatusUWBRangingFDD2FBD_VR_TimeStampUncertaintyResponder9: start 160, 8 bit, little-endian, data-type-policy=OVERRIDE, base-type=uint8, compu {phys=raw}, range phys 0..252
          signal StatusUWBRangingFDD2FBD_VR_StatusResponder9: start 168, 8 bit, little-endian, data-type-policy=OVERRIDE, base-type=uint8, compu {phys=raw}, range phys 0..252
          signal StatusUWBRangingFDD2FBD_VR_IndexResponder10: start 176, 8 bit, little-endian, data-type-policy=OVERRIDE, base-type=uint8, compu {phys=raw}, range phys 0..252
          signal StatusUWBRangingFDD2FBD_VR_TimeStampResponder10: start 184, 32 bit, little-endian, data-type-policy=OVERRIDE, base-type=uint32, compu {phys=raw}, range phys 0..4294967292
          signal StatusUWBRangingFDD2FBD_VR_TimeStampUncertaintyResponder10: start 216, 8 bit, little-endian, data-type-policy=OVERRIDE, base-type=uint8, compu {phys=raw}, range phys 0..252
          signal StatusUWBRangingFDD2FBD_VR_StatusResponder10: start 224, 8 bit, little-endian, data-type-policy=OVERRIDE, base-type=uint8, compu {phys=raw}, range phys 0..252
          signal StatusUWBRangingFDD2FBD_VR_TimeStampPoll: start 232, 64 bit, little-endian, data-type-policy=OVERRIDE, base-type=uint64, compu {phys=raw}, range phys 0..18446744073709551612
          signal StatusUWBRangingFDD2FBD_VR_Signature: start 296, 64 bit, little-endian, data-type-policy=OVERRIDE, base-type=uint64, compu {phys=raw}, range phys 0..18446744073709551614
          signal StatusUWBRangingFDD2FBD_VR_IV2: start 360, 8 bit, little-endian, data-type-policy=OVERRIDE, base-type=uint8, compu {phys=raw}, range phys 0..255
          signal StatusUWBRangingFDD2FBD_VR_IV3: start 368, 8 bit, little-endian, data-type-policy=OVERRIDE, base-type=uint8, compu {phys=raw}, range phys 0..255
      frame StatusWakeUpFBDOnlyMode_HL: id 0xB0, frame-length=8, can-addressing-mode=STANDARD, can-frame-rx-behavior=CAN-20, can-frame-tx-behavior=CAN-20
        pdu StatusWakeUpFBDOnlyMode_HL: length=8, unused-bit-pattern=0
          signal StatusWakeUpFBDOnlyMode_HL_PowerMode: start 0, 8 bit, little-endian, data-type-policy=OVERRIDE, compu {phys=raw}
      frame StatusWakeUpFBDOnlyMode_HM: id 0xAB, frame-length=8, can-addressing-mode=STANDARD, can-frame-rx-behavior=CAN-20, can-frame-tx-behavior=CAN-20
        pdu StatusWakeUpFBDOnlyMode_HM: length=8, unused-bit-pattern=0
          signal StatusWakeUpFBDOnlyMode_HM_PowerMode: start 0, 8 bit, little-endian, data-type-policy=OVERRIDE, compu {phys=raw}
      frame StatusWakeUpFBDOnlyMode_HR: id 0xB1, frame-length=8, can-addressing-mode=STANDARD, can-frame-rx-behavior=CAN-20, can-frame-tx-behavior=CAN-20
        pdu StatusWakeUpFBDOnlyMode_HR: length=8, unused-bit-pattern=0
          signal StatusWakeUpFBDOnlyMode_HR_PowerMode: start 0, 8 bit, little-endian, data-type-policy=OVERRIDE, compu {phys=raw}
      frame StatusWakeUpFBDOnlyMode_Miko: id 0xAC, frame-length=8, can-addressing-mode=STANDARD, can-frame-rx-behavior=CAN-20, can-frame-tx-behavior=CAN-20
        pdu StatusWakeUpFBDOnlyMode_Miko: length=8, unused-bit-pattern=0
          signal StatusWakeUpFBDOnlyMode_Miko_PowerMode: start 0, 8 bit, little-endian, data-type-policy=OVERRIDE, compu {phys=raw}
      frame StatusWakeUpFBDOnlyMode_MM: id 0xB5, frame-length=8, can-addressing-mode=STANDARD, can-frame-rx-behavior=CAN-20, can-frame-tx-behavior=CAN-20
        pdu StatusWakeUpFBDOnlyMode_MM: length=8, unused-bit-pattern=0
          signal StatusWakeUpFBDOnlyMode_MM_PowerMode: start 0, 8 bit, little-endian, data-type-policy=OVERRIDE, compu {phys=raw}
      frame StatusWakeUpFBDOnlyMode_SML: id 0xB2, frame-length=8, can-addressing-mode=STANDARD, can-frame-rx-behavior=CAN-20, can-frame-tx-behavior=CAN-20
        pdu StatusWakeUpFBDOnlyMode_SML: length=8, unused-bit-pattern=0
          signal StatusWakeUpFBDOnlyMode_SML_PowerMode: start 0, 8 bit, little-endian, data-type-policy=OVERRIDE, compu {phys=raw}
      frame StatusWakeUpFBDOnlyMode_SMR: id 0xB3, frame-length=8, can-addressing-mode=STANDARD, can-frame-rx-behavior=CAN-20, can-frame-tx-behavior=CAN-20
        pdu StatusWakeUpFBDOnlyMode_SMR: length=8, unused-bit-pattern=0
          signal StatusWakeUpFBDOnlyMode_SMR_PowerMode: start 0, 8 bit, little-endian, data-type-policy=OVERRIDE, compu {phys=raw}
      frame StatusWakeUpFBDOnlyMode_Trunk: id 0xAD, frame-length=8, can-addressing-mode=STANDARD, can-frame-rx-behavior=CAN-20, can-frame-tx-behavior=CAN-20
        pdu StatusWakeUpFBDOnlyMode_Trunk: length=8, unused-bit-pattern=0
          signal StatusWakeUpFBDOnlyMode_Trunk_PowerMode: start 0, 8 bit, little-endian, data-type-policy=OVERRIDE, compu {phys=raw}
      frame StatusWakeUpFBDOnlyMode_VL: id 0xAE, frame-length=8, can-addressing-mode=STANDARD, can-frame-rx-behavior=CAN-20, can-frame-tx-behavior=CAN-20
        pdu StatusWakeUpFBDOnlyMode_VL: length=8, unused-bit-pattern=0
          signal StatusWakeUpFBDOnlyMode_VL_PowerMode: start 0, 8 bit, little-endian, data-type-policy=OVERRIDE, compu {phys=raw}
      frame StatusWakeUpFBDOnlyMode_VM: id 0xAA, frame-length=8, can-addressing-mode=STANDARD, can-frame-rx-behavior=CAN-20, can-frame-tx-behavior=CAN-20
        pdu StatusWakeUpFBDOnlyMode_VM: length=8, unused-bit-pattern=0
          signal StatusWakeUpFBDOnlyMode_VM_PowerMode: start 0, 8 bit, little-endian, data-type-policy=OVERRIDE, compu {phys=raw}
      frame StatusWakeUpFBDOnlyMode_VR: id 0xAF, frame-length=8, can-addressing-mode=STANDARD, can-frame-rx-behavior=CAN-20, can-frame-tx-behavior=CAN-20
        pdu StatusWakeUpFBDOnlyMode_VR: length=8, unused-bit-pattern=0
          signal StatusWakeUpFBDOnlyMode_VR_PowerMode: start 0, 8 bit, little-endian, data-type-policy=OVERRIDE, compu {phys=raw}
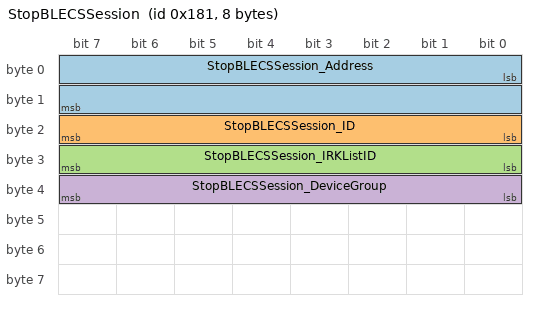
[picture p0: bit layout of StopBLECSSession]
      frame StopBLECSSession: id 0x181, frame-length=8, can-addressing-mode=STANDARD, can-frame-rx-behavior=CAN-20, can-frame-tx-behavior=CAN-20
        pdu StopBLECSSession: length=8, unused-bit-pattern=0
          signal StopBLECSSession_Address: start 0, 16 bit, little-endian, data-type-policy=OVERRIDE, compu {phys=raw}
          signal StopBLECSSession_ID: start 16, 8 bit, little-endian, data-type-policy=OVERRIDE, base-type=uint8, compu {phys=raw}, range phys 0..252
          signal StopBLECSSession_IRKListID: start 24, 8 bit, little-endian, data-type-policy=OVERRIDE, base-type=uint8, compu {phys=raw}, range phys 0..252
          signal StopBLECSSession_DeviceGroup: start 32, 8 bit, little-endian, data-type-policy=OVERRIDE, base-type=uint8, compu {phys=raw}, range phys 0..252
      frame TimeSyncDeviceOffsetFBD_HL: id 0x74, frame-length=16, can-addressing-mode=STANDARD, can-frame-rx-behavior=CAN-FD, can-frame-tx-behavior=CAN-FD
        pdu TimeSyncDeviceOffsetFBD_HL: length=16, unused-bit-pattern=0
          signal TimeSyncDeviceOffsetFBD_HL_SessionIDShort: start 0, 8 bit, little-endian, data-type-policy=OVERRIDE, base-type=uint8, compu {phys=raw}, range phys 0..252
          signal TimeSyncDeviceOffsetFBD_HL_IRKListID: start 8, 8 bit, little-endian, data-type-policy=OVERRIDE, base-type=uint8, compu {phys=raw}, range phys 0..252
          signal TimeSyncDeviceOffsetFBD_HL_TimeOffset: start 16, 64 bit, little-endian, data-type-policy=OVERRIDE, base-type=uint64, compu {phys=raw}, range phys 0..18446744073709551612
          signal TimeSyncDeviceOffsetFBD_HL_TimeOffsetUncertainty: start 80, 16 bit, little-endian, data-type-policy=OVERRIDE, base-type=uint16, compu {phys=raw}, range phys 0..65532
          signal TimeSyncDeviceOffsetFBD_HL_UWBDeviceTimeUncertainity: start 96, 8 bit, little-endian, data-type-policy=OVERRIDE, base-type=uint8, compu {phys=raw}, range phys 0..252
          signal TimeSyncDeviceOffsetFBD_HL_UWBDeviceMaxPPM: start 104, 16 bit, little-endian, data-type-policy=OVERRIDE, base-type=uint16, compu {phys=raw}, range phys 0..65532
          signal TimeSyncDeviceOffsetFBD_HL_UWBClockSkewMeasurementAvailable: start 120, 8 bit, little-endian, data-type-policy=OVERRIDE, base-type=uint8, compu {phys=raw}, range phys 0..252
      frame TimeSyncDeviceOffsetFBD_HM: id 0x6F, frame-length=16, can-addressing-mode=STANDARD, can-frame-rx-behavior=CAN-FD, can-frame-tx-behavior=CAN-FD
        pdu TimeSyncDeviceOffsetFBD_HM: length=16, unused-bit-pattern=0
          signal TimeSyncDeviceOffsetFBD_HM_SessionIDShort: start 0, 8 bit, little-endian, data-type-policy=OVERRIDE, base-type=uint8, compu {phys=raw}, range phys 0..252
          signal TimeSyncDeviceOffsetFBD_HM_IRKListID: start 8, 8 bit, little-endian, data-type-policy=OVERRIDE, base-type=uint8, compu {phys=raw}, range phys 0..252
          signal TimeSyncDeviceOffsetFBD_HM_TimeOffset: start 16, 64 bit, little-endian, data-type-policy=OVERRIDE, base-type=uint64, compu {phys=raw}, range phys 0..18446744073709551612
          signal TimeSyncDeviceOffsetFBD_HM_TimeOffsetUncertainty: start 80, 16 bit, little-endian, data-type-policy=OVERRIDE, base-type=uint16, compu {phys=raw}, range phys 0..65532
          signal TimeSyncDeviceOffsetFBD_HM_UWBDeviceTimeUncertainity: start 96, 8 bit, little-endian, data-type-policy=OVERRIDE, base-type=uint8, compu {phys=raw}, range phys 0..252
          signal TimeSyncDeviceOffsetFBD_HM_UWBDeviceMaxPPM: start 104, 16 bit, little-endian, data-type-policy=OVERRIDE, base-type=uint16, compu {phys=raw}, range phys 0..65532
          signal TimeSyncDeviceOffsetFBD_HM_UWBClockSkewMeasurementAvailable: start 120, 8 bit, little-endian, data-type-policy=OVERRIDE, base-type=uint8, compu {phys=raw}, range phys 0..252
      frame TimeSyncDeviceOffsetFBD_HR: id 0x75, frame-length=16, can-addressing-mode=STANDARD, can-frame-rx-behavior=CAN-FD, can-frame-tx-behavior=CAN-FD
        pdu TimeSyncDeviceOffsetFBD_HR: length=16, unused-bit-pattern=0
          signal TimeSyncDeviceOffsetFBD_HR_SessionIDShort: start 0, 8 bit, little-endian, data-type-policy=OVERRIDE, base-type=uint8, compu {phys=raw}, range phys 0..252
          signal TimeSyncDeviceOffsetFBD_HR_IRKListID: start 8, 8 bit, little-endian, data-type-policy=OVERRIDE, base-type=uint8, compu {phys=raw}, range phys 0..252
          signal TimeSyncDeviceOffsetFBD_HR_TimeOffset: start 16, 64 bit, little-endian, data-type-policy=OVERRIDE, base-type=uint64, compu {phys=raw}, range phys 0..18446744073709551612
          signal TimeSyncDeviceOffsetFBD_HR_TimeOffsetUncertainty: start 80, 16 bit, little-endian, data-type-policy=OVERRIDE, base-type=uint16, compu {phys=raw}, range phys 0..65532
          signal TimeSyncDeviceOffsetFBD_HR_UWBDeviceTimeUncertainity: start 96, 8 bit, little-endian, data-type-policy=OVERRIDE, base-type=uint8, compu {phys=raw}, range phys 0..252
          signal TimeSyncDeviceOffsetFBD_HR_UWBDeviceMaxPPM: start 104, 16 bit, little-endian, data-type-policy=OVERRIDE, base-type=uint16, compu {phys=raw}, range phys 0..65532
          signal TimeSyncDeviceOffsetFBD_HR_UWBClockSkewMeasurementAvailable: start 120, 8 bit, little-endian, data-type-policy=OVERRIDE, base-type=uint8, compu {phys=raw}, range phys 0..252
      frame TimeSyncDeviceOffsetFBD_Miko: id 0x70, frame-length=16, can-addressing-mode=STANDARD, can-frame-rx-behavior=CAN-FD, can-frame-tx-behavior=CAN-FD
        pdu TimeSyncDeviceOffsetFBD_Miko: length=16, unused-bit-pattern=0
          signal TimeSyncDeviceOffsetFBD_Miko_SessionIDShort: start 0, 8 bit, little-endian, data-type-policy=OVERRIDE, base-type=uint8, compu {phys=raw}, range phys 0..252
          signal TimeSyncDeviceOffsetFBD_Miko_IRKListID: start 8, 8 bit, little-endian, data-type-policy=OVERRIDE, base-type=uint8, compu {phys=raw}, range phys 0..252
          signal TimeSyncDeviceOffsetFBD_Miko_TimeOffset: start 16, 64 bit, little-endian, data-type-policy=OVERRIDE, base-type=uint64, compu {phys=raw}, range phys 0..18446744073709551612
          signal TimeSyncDeviceOffsetFBD_Miko_TimeOffsetUncertainty: start 80, 16 bit, little-endian, data-type-policy=OVERRIDE, base-type=uint16, compu {phys=raw}, range phys 0..65532
          signal TimeSyncDeviceOffsetFBD_Miko_UWBDeviceTimeUncertainity: start 96, 8 bit, little-endian, data-type-policy=OVERRIDE, base-type=uint8, compu {phys=raw}, range phys 0..252
          signal TimeSyncDeviceOffsetFBD_Miko_UWBDeviceMaxPPM: start 104, 16 bit, little-endian, data-type-policy=OVERRIDE, base-type=uint16, compu {phys=raw}, range phys 0..65532
          signal TimeSyncDeviceOffsetFBD_Miko_UWBClockSkewMeasurementAvailable: start 120, 8 bit, little-endian, data-type-policy=OVERRIDE, base-type=uint8, compu {phys=raw}, range phys 0..252
      frame TimeSyncDeviceOffsetFBD_MM: id 0x32B, frame-length=16, can-addressing-mode=STANDARD, can-frame-rx-behavior=CAN-FD, can-frame-tx-behavior=CAN-FD
        pdu TimeSyncDeviceOffsetFBD_MM: length=16, unused-bit-pattern=0
          signal TimeSyncDeviceOffsetFBD_MM_SessionIDShort: start 0, 8 bit, little-endian, data-type-policy=OVERRIDE, base-type=uint8, compu {phys=raw}, range phys 0..252
          signal TimeSyncDeviceOffsetFBD_MM_IRKListID: start 8, 8 bit, little-endian, data-type-policy=OVERRIDE, base-type=uint8, compu {phys=raw}, range phys 0..252
          signal TimeSyncDeviceOffsetFBD_MM_TimeOffset: start 16, 64 bit, little-endian, data-type-policy=OVERRIDE, base-type=uint64, compu {phys=raw}, range phys 0..18446744073709551612
          signal TimeSyncDeviceOffsetFBD_MM_TimeOffsetUncertainty: start 80, 16 bit, little-endian, data-type-policy=OVERRIDE, base-type=uint16, compu {phys=raw}, range phys 0..65532
          signal TimeSyncDeviceOffsetFBD_MM_UWBDeviceTimeUncertainity: start 96, 8 bit, little-endian, data-type-policy=OVERRIDE, base-type=uint8, compu {phys=raw}, range phys 0..252
          signal TimeSyncDeviceOffsetFBD_MM_UWBDeviceMaxPPM: start 104, 16 bit, little-endian, data-type-policy=OVERRIDE, base-type=uint16, compu {phys=raw}, range phys 0..65532
          signal TimeSyncDeviceOffsetFBD_MM_UWBClockSkewMeasurementAvailable: start 120, 8 bit, little-endian, data-type-policy=OVERRIDE, base-type=uint8, compu {phys=raw}, range phys 0..252
      frame TimeSyncDeviceOffsetFBD_SML: id 0x76, frame-length=16, can-addressing-mode=STANDARD, can-frame-rx-behavior=CAN-FD, can-frame-tx-behavior=CAN-FD
        pdu TimeSyncDeviceOffsetFBD_SML: length=16, unused-bit-pattern=0
          signal TimeSyncDeviceOffsetFBD_SML_SessionIDShort: start 0, 8 bit, little-endian, data-type-policy=OVERRIDE, base-type=uint8, compu {phys=raw}, range phys 0..252
          signal TimeSyncDeviceOffsetFBD_SML_IRKListID: start 8, 8 bit, little-endian, data-type-policy=OVERRIDE, base-type=uint8, compu {phys=raw}, range phys 0..252
          signal TimeSyncDeviceOffsetFBD_SML_TimeOffset: start 16, 64 bit, little-endian, data-type-policy=OVERRIDE, base-type=uint64, compu {phys=raw}, range phys 0..18446744073709551612
          signal TimeSyncDeviceOffsetFBD_SML_TimeOffsetUncertainty: start 80, 16 bit, little-endian, data-type-policy=OVERRIDE, base-type=uint16, compu {phys=raw}, range phys 0..65532
          signal TimeSyncDeviceOffsetFBD_SML_UWBDeviceTimeUncertainity: start 96, 8 bit, little-endian, data-type-policy=OVERRIDE, base-type=uint8, compu {phys=raw}, range phys 0..252
          signal TimeSyncDeviceOffsetFBD_SML_UWBDeviceMaxPPM: start 104, 16 bit, little-endian, data-type-policy=OVERRIDE, base-type=uint16, compu {phys=raw}, range phys 0..65532
          signal TimeSyncDeviceOffsetFBD_SML_UWBClockSkewMeasurementAvailable: start 120, 8 bit, little-endian, data-type-policy=OVERRIDE, base-type=uint8, compu {phys=raw}, range phys 0..252
      frame TimeSyncDeviceOffsetFBD_SMR: id 0x77, frame-length=16, can-addressing-mode=STANDARD, can-frame-rx-behavior=CAN-FD, can-frame-tx-behavior=CAN-FD
        pdu TimeSyncDeviceOffsetFBD_SMR: length=16, unused-bit-pattern=0
          signal TimeSyncDeviceOffsetFBD_SMR_SessionIDShort: start 0, 8 bit, little-endian, data-type-policy=OVERRIDE, base-type=uint8, compu {phys=raw}, range phys 0..252
          signal TimeSyncDeviceOffsetFBD_SMR_IRKListID: start 8, 8 bit, little-endian, data-type-policy=OVERRIDE, base-type=uint8, compu {phys=raw}, range phys 0..252
          signal TimeSyncDeviceOffsetFBD_SMR_TimeOffset: start 16, 64 bit, little-endian, data-type-policy=OVERRIDE, base-type=uint64, compu {phys=raw}, range phys 0..18446744073709551612
          signal TimeSyncDeviceOffsetFBD_SMR_TimeOffsetUncertainty: start 80, 16 bit, little-endian, data-type-policy=OVERRIDE, base-type=uint16, compu {phys=raw}, range phys 0..65532
          signal TimeSyncDeviceOffsetFBD_SMR_UWBDeviceTimeUncertainity: start 96, 8 bit, little-endian, data-type-policy=OVERRIDE, base-type=uint8, compu {phys=raw}, range phys 0..252
          signal TimeSyncDeviceOffsetFBD_SMR_UWBDeviceMaxPPM: start 104, 16 bit, little-endian, data-type-policy=OVERRIDE, base-type=uint16, compu {phys=raw}, range phys 0..65532
          signal TimeSyncDeviceOffsetFBD_SMR_UWBClockSkewMeasurementAvailable: start 120, 8 bit, little-endian, data-type-policy=OVERRIDE, base-type=uint8, compu {phys=raw}, range phys 0..252
      frame TimeSyncDeviceOffsetFBD_Trunk: id 0x71, frame-length=16, can-addressing-mode=STANDARD, can-frame-rx-behavior=CAN-FD, can-frame-tx-behavior=CAN-FD
        pdu TimeSyncDeviceOffsetFBD_Trunk: length=16, unused-bit-pattern=0
          signal TimeSyncDeviceOffsetFBD_Trunk_SessionIDShort: start 0, 8 bit, little-endian, data-type-policy=OVERRIDE, base-type=uint8, compu {phys=raw}, range phys 0..252
          signal TimeSyncDeviceOffsetFBD_Trunk_IRKListID: start 8, 8 bit, little-endian, data-type-policy=OVERRIDE, base-type=uint8, compu {phys=raw}, range phys 0..252
          signal TimeSyncDeviceOffsetFBD_Trunk_TimeOffset: start 16, 64 bit, little-endian, data-type-policy=OVERRIDE, base-type=uint64, compu {phys=raw}, range phys 0..18446744073709551612
          signal TimeSyncDeviceOffsetFBD_Trunk_TimeOffsetUncertainty: start 80, 16 bit, little-endian, data-type-policy=OVERRIDE, base-type=uint16, compu {phys=raw}, range phys 0..65532
          signal TimeSyncDeviceOffsetFBD_Trunk_UWBDeviceTimeUncertainity: start 96, 8 bit, little-endian, data-type-policy=OVERRIDE, base-type=uint8, compu {phys=raw}, range phys 0..252
          signal TimeSyncDeviceOffsetFBD_Trunk_UWBDeviceMaxPPM: start 104, 16 bit, little-endian, data-type-policy=OVERRIDE, base-type=uint16, compu {phys=raw}, range phys 0..65532
          signal TimeSyncDeviceOffsetFBD_Trunk_UWBClockSkewMeasurementAvailable: start 120, 8 bit, little-endian, data-type-policy=OVERRIDE, base-type=uint8, compu {phys=raw}, range phys 0..252
      frame TimeSyncDeviceOffsetFBD_VL: id 0x72, frame-length=16, can-addressing-mode=STANDARD, can-frame-rx-behavior=CAN-FD, can-frame-tx-behavior=CAN-FD
        pdu TimeSyncDeviceOffsetFBD_VL: length=16, unused-bit-pattern=0
          signal TimeSyncDeviceOffsetFBD_VL_SessionIDShort: start 0, 8 bit, little-endian, data-type-policy=OVERRIDE, base-type=uint8, compu {phys=raw}, range phys 0..252
          signal TimeSyncDeviceOffsetFBD_VL_IRKListID: start 8, 8 bit, little-endian, data-type-policy=OVERRIDE, base-type=uint8, compu {phys=raw}, range phys 0..252
          signal TimeSyncDeviceOffsetFBD_VL_TimeOffset: start 16, 64 bit, little-endian, data-type-policy=OVERRIDE, base-type=uint64, compu {phys=raw}, range phys 0..18446744073709551612
          signal TimeSyncDeviceOffsetFBD_VL_TimeOffsetUncertainty: start 80, 16 bit, little-endian, data-type-policy=OVERRIDE, base-type=uint16, compu {phys=raw}, range phys 0..65532
          signal TimeSyncDeviceOffsetFBD_VL_UWBDeviceTimeUncertainity: start 96, 8 bit, little-endian, data-type-policy=OVERRIDE, base-type=uint8, compu {phys=raw}, range phys 0..252
          signal TimeSyncDeviceOffsetFBD_VL_UWBDeviceMaxPPM: start 104, 16 bit, little-endian, data-type-policy=OVERRIDE, base-type=uint16, compu {phys=raw}, range phys 0..65532
          signal TimeSyncDeviceOffsetFBD_VL_UWBClockSkewMeasurementAvailable: start 120, 8 bit, little-endian, data-type-policy=OVERRIDE, base-type=uint8, compu {phys=raw}, range phys 0..252
      frame TimeSyncDeviceOffsetFBD_VM: id 0x6E, frame-length=16, can-addressing-mode=STANDARD, can-frame-rx-behavior=CAN-FD, can-frame-tx-behavior=CAN-FD
        pdu TimeSyncDeviceOffsetFBD_VM: length=16, unused-bit-pattern=0
          signal TimeSyncDeviceOffsetFBD_VM_SessionIDShort: start 0, 8 bit, little-endian, data-type-policy=OVERRIDE, base-type=uint8, compu {phys=raw}, range phys 0..252
          signal TimeSyncDeviceOffsetFBD_VM_IRKListID: start 8, 8 bit, little-endian, data-type-policy=OVERRIDE, base-type=uint8, compu {phys=raw}, range phys 0..252
          signal TimeSyncDeviceOffsetFBD_VM_TimeOffset: start 16, 64 bit, little-endian, data-type-policy=OVERRIDE, base-type=uint64, compu {phys=raw}, range phys 0..18446744073709551612
          signal TimeSyncDeviceOffsetFBD_VM_TimeOffsetUncertainty: start 80, 16 bit, little-endian, data-type-policy=OVERRIDE, base-type=uint16, compu {phys=raw}, range phys 0..65532
          signal TimeSyncDeviceOffsetFBD_VM_UWBDeviceTimeUncertainity: start 96, 8 bit, little-endian, data-type-policy=OVERRIDE, base-type=uint8, compu {phys=raw}, range phys 0..252
          signal TimeSyncDeviceOffsetFBD_VM_UWBDeviceMaxPPM: start 104, 16 bit, little-endian, data-type-policy=OVERRIDE, base-type=uint16, compu {phys=raw}, range phys 0..65532
          signal TimeSyncDeviceOffsetFBD_VM_UWBClockSkewMeasurementAvailable: start 120, 8 bit, little-endian, data-type-policy=OVERRIDE, base-type=uint8, compu {phys=raw}, range phys 0..252
      frame TimeSyncDeviceOffsetFBD_VR: id 0x73, frame-length=16, can-addressing-mode=STANDARD, can-frame-rx-behavior=CAN-FD, can-frame-tx-behavior=CAN-FD
        pdu TimeSyncDeviceOffsetFBD_VR: length=16, unused-bit-pattern=0
          signal TimeSyncDeviceOffsetFBD_VR_SessionIDShort: start 0, 8 bit, little-endian, data-type-policy=OVERRIDE, base-type=uint8, compu {phys=raw}, range phys 0..252
          signal TimeSyncDeviceOffsetFBD_VR_IRKListID: start 8, 8 bit, little-endian, data-type-policy=OVERRIDE, base-type=uint8, compu {phys=raw}, range phys 0..252
          signal TimeSyncDeviceOffsetFBD_VR_TimeOffset: start 16, 64 bit, little-endian, data-type-policy=OVERRIDE, base-type=uint64, compu {phys=raw}, range phys 0..18446744073709551612
          signal TimeSyncDeviceOffsetFBD_VR_TimeOffsetUncertainty: start 80, 16 bit, little-endian, data-type-policy=OVERRIDE, base-type=uint16, compu {phys=raw}, range phys 0..65532
          signal TimeSyncDeviceOffsetFBD_VR_UWBDeviceTimeUncertainity: start 96, 8 bit, little-endian, data-type-policy=OVERRIDE, base-type=uint8, compu {phys=raw}, range phys 0..252
          signal TimeSyncDeviceOffsetFBD_VR_UWBDeviceMaxPPM: start 104, 16 bit, little-endian, data-type-policy=OVERRIDE, base-type=uint16, compu {phys=raw}, range phys 0..65532
          signal TimeSyncDeviceOffsetFBD_VR_UWBClockSkewMeasurementAvailable: start 120, 8 bit, little-endian, data-type-policy=OVERRIDE, base-type=uint8, compu {phys=raw}, range phys 0..252
      frame TimeSyncFBD_HL: id 0x6A, frame-length=8, can-addressing-mode=STANDARD, can-frame-rx-behavior=CAN-20, can-frame-tx-behavior=CAN-20
        pdu TimeSyncFBD_HL: length=8, unused-bit-pattern=0
          signal TimeSyncFBD_HL_SyncTime: start 0, 64 bit, little-endian, data-type-policy=OVERRIDE, base-type=uint64, compu {phys=raw}, range phys 0..18446744073709551612
      frame TimeSyncFBD_HM: id 0x65, frame-length=8, can-addressing-mode=STANDARD, can-frame-rx-behavior=CAN-20, can-frame-tx-behavior=CAN-20
        pdu TimeSyncFBD_HM: length=8, unused-bit-pattern=0
          signal TimeSyncFBD_HM_SyncTime: start 0, 64 bit, little-endian, data-type-policy=OVERRIDE, base-type=uint64, compu {phys=raw}, range phys 0..18446744073709551612
      frame TimeSyncFBD_HR: id 0x6B, frame-length=8, can-addressing-mode=STANDARD, can-frame-rx-behavior=CAN-20, can-frame-tx-behavior=CAN-20
        pdu TimeSyncFBD_HR: length=8, unused-bit-pattern=0
          signal TimeSyncFBD_HR_SyncTime: start 0, 64 bit, little-endian, data-type-policy=OVERRIDE, base-type=uint64, compu {phys=raw}, range phys 0..18446744073709551612
      frame TimeSyncFBD_Miko: id 0x66, frame-length=8, can-addressing-mode=STANDARD, can-frame-rx-behavior=CAN-20, can-frame-tx-behavior=CAN-20
        pdu TimeSyncFBD_Miko: length=8, unused-bit-pattern=0
          signal TimeSyncFBD_Miko_SyncTime: start 0, 64 bit, little-endian, data-type-policy=OVERRIDE, base-type=uint64, compu {phys=raw}, range phys 0..18446744073709551612
      frame TimeSyncFBD_MM: id 0x32A, frame-length=8, can-addressing-mode=STANDARD, can-frame-rx-behavior=CAN-20, can-frame-tx-behavior=CAN-20
        pdu TimeSyncFBD_MM: length=8, unused-bit-pattern=0
          signal TimeSyncFBD_MM_SyncTime: start 0, 64 bit, little-endian, data-type-policy=OVERRIDE, base-type=uint64, compu {phys=raw}, range phys 0..18446744073709551612
      frame TimeSyncFBD_SML: id 0x6C, frame-length=8, can-addressing-mode=STANDARD, can-frame-rx-behavior=CAN-20, can-frame-tx-behavior=CAN-20
        pdu TimeSyncFBD_SML: length=8, unused-bit-pattern=0
          signal TimeSyncFBD_SML_SyncTime: start 0, 64 bit, little-endian, data-type-policy=OVERRIDE, base-type=uint64, compu {phys=raw}, range phys 0..18446744073709551612
      frame TimeSyncFBD_SMR: id 0x6D, frame-length=8, can-addressing-mode=STANDARD, can-frame-rx-behavior=CAN-20, can-frame-tx-behavior=CAN-20
        pdu TimeSyncFBD_SMR: length=8, unused-bit-pattern=0
          signal TimeSyncFBD_SMR_SyncTime: start 0, 64 bit, little-endian, data-type-policy=OVERRIDE, base-type=uint64, compu {phys=raw}, range phys 0..18446744073709551612
      frame TimeSyncFBD_Trunk: id 0x67, frame-length=8, can-addressing-mode=STANDARD, can-frame-rx-behavior=CAN-20, can-frame-tx-behavior=CAN-20
        pdu TimeSyncFBD_Trunk: length=8, unused-bit-pattern=0
          signal TimeSyncFBD_Trunk_SyncTime: start 0, 64 bit, little-endian, data-type-policy=OVERRIDE, base-type=uint64, compu {phys=raw}, range phys 0..18446744073709551612
      frame TimeSyncFBD_VL: id 0x68, frame-length=8, can-addressing-mode=STANDARD, can-frame-rx-behavior=CAN-20, can-frame-tx-behavior=CAN-20
        pdu TimeSyncFBD_VL: length=8, unused-bit-pattern=0
          signal TimeSyncFBD_VL_SyncTime: start 0, 64 bit, little-endian, data-type-policy=OVERRIDE, base-type=uint64, compu {phys=raw}, range phys 0..18446744073709551612
      frame TimeSyncFBD_VM: id 0x64, frame-length=8, can-addressing-mode=STANDARD, can-frame-rx-behavior=CAN-20, can-frame-tx-behavior=CAN-20
        pdu TimeSyncFBD_VM: length=8, unused-bit-pattern=0
          signal TimeSyncFBD_VM_SyncTime: start 0, 64 bit, little-endian, data-type-policy=OVERRIDE, base-type=uint64, compu {phys=raw}, range phys 0..18446744073709551612
      frame TimeSyncFBD_VR: id 0x69, frame-length=8, can-addressing-mode=STANDARD, can-frame-rx-behavior=CAN-20, can-frame-tx-behavior=CAN-20
        pdu TimeSyncFBD_VR: length=8, unused-bit-pattern=0
          signal TimeSyncFBD_VR_SyncTime: start 0, 64 bit, little-endian, data-type-policy=OVERRIDE, base-type=uint64, compu {phys=raw}, range phys 0..18446744073709551612
      frame TPBLEDaten_FBD_HL_IPB: id 0x204, frame-length=64, can-addressing-mode=STANDARD, can-frame-rx-behavior=CAN-FD, can-frame-tx-behavior=CAN-FD
        pdu TPBLEDaten_FBD_HL_IPB: length=64, unused-bit-pattern=0
          signal TPBLEDatenFBD_HLIPB_Byte00: start 0, 8 bit, little-endian, data-type-policy=OVERRIDE, base-type=uint8, compu {phys=raw}, range phys 0..252
          signal TPBLEDatenFBD_HLIPB_Byte01: start 8, 8 bit, little-endian, data-type-policy=OVERRIDE, base-type=uint8, compu {phys=raw}, range phys 0..252
          signal TPBLEDatenFBD_HLIPB_Byte02: start 16, 8 bit, little-endian, data-type-policy=OVERRIDE, base-type=uint8, compu {phys=raw}, range phys 0..252
          signal TPBLEDatenFBD_HLIPB_Byte03: start 24, 8 bit, little-endian, data-type-policy=OVERRIDE, base-type=uint8, compu {phys=raw}, range phys 0..252
          signal TPBLEDatenFBD_HLIPB_Byte04: start 32, 8 bit, little-endian, data-type-policy=OVERRIDE, base-type=uint8, compu {phys=raw}, range phys 0..252
          signal TPBLEDatenFBD_HLIPB_Byte05: start 40, 8 bit, little-endian, data-type-policy=OVERRIDE, base-type=uint8, compu {phys=raw}, range phys 0..252
          signal TPBLEDatenFBD_HLIPB_Byte06: start 48, 8 bit, little-endian, data-type-policy=OVERRIDE, base-type=uint8, compu {phys=raw}, range phys 0..252
          signal TPBLEDatenFBD_HLIPB_Byte07: start 56, 8 bit, little-endian, data-type-policy=OVERRIDE, base-type=uint8, compu {phys=raw}, range phys 0..252
          signal TPBLEDatenFBD_HLIPB_Byte08: start 64, 8 bit, little-endian, data-type-policy=OVERRIDE, base-type=uint8, compu {phys=raw}, range phys 0..252
          signal TPBLEDatenFBD_HLIPB_Byte09: start 72, 8 bit, little-endian, data-type-policy=OVERRIDE, base-type=uint8, compu {phys=raw}, range phys 0..252
          signal TPBLEDatenFBD_HLIPB_Byte10: start 80, 8 bit, little-endian, data-type-policy=OVERRIDE, base-type=uint8, compu {phys=raw}, range phys 0..252
          signal TPBLEDatenFBD_HLIPB_Byte11: start 88, 8 bit, little-endian, data-type-policy=OVERRIDE, base-type=uint8, compu {phys=raw}, range phys 0..252
          signal TPBLEDatenFBD_HLIPB_Byte12: start 96, 8 bit, little-endian, data-type-policy=OVERRIDE, base-type=uint8, compu {phys=raw}, range phys 0..252
          signal TPBLEDatenFBD_HLIPB_Byte13: start 104, 8 bit, little-endian, data-type-policy=OVERRIDE, base-type=uint8, compu {phys=raw}, range phys 0..252
          signal TPBLEDatenFBD_HLIPB_Byte14: start 112, 8 bit, little-endian, data-type-policy=OVERRIDE, base-type=uint8, compu {phys=raw}, range phys 0..252
          signal TPBLEDatenFBD_HLIPB_Byte15: start 120, 8 bit, little-endian, data-type-policy=OVERRIDE, base-type=uint8, compu {phys=raw}, range phys 0..252
          signal TPBLEDatenFBD_HLIPB_Byte16: start 128, 8 bit, little-endian, data-type-policy=OVERRIDE, base-type=uint8, compu {phys=raw}, range phys 0..252
          signal TPBLEDatenFBD_HLIPB_Byte17: start 136, 8 bit, little-endian, data-type-policy=OVERRIDE, base-type=uint8, compu {phys=raw}, range phys 0..252
          signal TPBLEDatenFBD_HLIPB_Byte18: start 144, 8 bit, little-endian, data-type-policy=OVERRIDE, base-type=uint8, compu {phys=raw}, range phys 0..252
          signal TPBLEDatenFBD_HLIPB_Byte19: start 152, 8 bit, little-endian, data-type-policy=OVERRIDE, base-type=uint8, compu {phys=raw}, range phys 0..252
          signal TPBLEDatenFBD_HLIPB_Byte20: start 160, 8 bit, little-endian, data-type-policy=OVERRIDE, base-type=uint8, compu {phys=raw}, range phys 0..252
          signal TPBLEDatenFBD_HLIPB_Byte21: start 168, 8 bit, little-endian, data-type-policy=OVERRIDE, base-type=uint8, compu {phys=raw}, range phys 0..252
          signal TPBLEDatenFBD_HLIPB_Byte22: start 176, 8 bit, little-endian, data-type-policy=OVERRIDE, base-type=uint8, compu {phys=raw}, range phys 0..252
          signal TPBLEDatenFBD_HLIPB_Byte23: start 184, 8 bit, little-endian, data-type-policy=OVERRIDE, base-type=uint8, compu {phys=raw}, range phys 0..252
          signal TPBLEDatenFBD_HLIPB_Byte24: start 192, 8 bit, little-endian, data-type-policy=OVERRIDE, base-type=uint8, compu {phys=raw}, range phys 0..252
          signal TPBLEDatenFBD_HLIPB_Byte25: start 200, 8 bit, little-endian, data-type-policy=OVERRIDE, base-type=uint8, compu {phys=raw}, range phys 0..252
          signal TPBLEDatenFBD_HLIPB_Byte26: start 208, 8 bit, little-endian, data-type-policy=OVERRIDE, base-type=uint8, compu {phys=raw}, range phys 0..252
          signal TPBLEDatenFBD_HLIPB_Byte27: start 216, 8 bit, little-endian, data-type-policy=OVERRIDE, base-type=uint8, compu {phys=raw}, range phys 0..252
          signal TPBLEDatenFBD_HLIPB_Byte28: start 224, 8 bit, little-endian, data-type-policy=OVERRIDE, base-type=uint8, compu {phys=raw}, range phys 0..252
          signal TPBLEDatenFBD_HLIPB_Byte29: start 232, 8 bit, little-endian, data-type-policy=OVERRIDE, base-type=uint8, compu {phys=raw}, range phys 0..252
          signal TPBLEDatenFBD_HLIPB_Byte30: start 240, 8 bit, little-endian, data-type-policy=OVERRIDE, base-type=uint8, compu {phys=raw}, range phys 0..252
          signal TPBLEDatenFBD_HLIPB_Byte31: start 248, 8 bit, little-endian, data-type-policy=OVERRIDE, base-type=uint8, compu {phys=raw}, range phys 0..252
          signal TPBLEDatenFBD_HLIPB_Byte32: start 256, 8 bit, little-endian, data-type-policy=OVERRIDE, base-type=uint8, compu {phys=raw}, range phys 0..252
          signal TPBLEDatenFBD_HLIPB_Byte33: start 264, 8 bit, little-endian, data-type-policy=OVERRIDE, base-type=uint8, compu {phys=raw}, range phys 0..252
          signal TPBLEDatenFBD_HLIPB_Byte34: start 272, 8 bit, little-endian, data-type-policy=OVERRIDE, base-type=uint8, compu {phys=raw}, range phys 0..252
          signal TPBLEDatenFBD_HLIPB_Byte35: start 280, 8 bit, little-endian, data-type-policy=OVERRIDE, base-type=uint8, compu {phys=raw}, range phys 0..252
          signal TPBLEDatenFBD_HLIPB_Byte36: start 288, 8 bit, little-endian, data-type-policy=OVERRIDE, base-type=uint8, compu {phys=raw}, range phys 0..252
          signal TPBLEDatenFBD_HLIPB_Byte37: start 296, 8 bit, little-endian, data-type-policy=OVERRIDE, base-type=uint8, compu {phys=raw}, range phys 0..252
          signal TPBLEDatenFBD_HLIPB_Byte38: start 304, 8 bit, little-endian, data-type-policy=OVERRIDE, base-type=uint8, compu {phys=raw}, range phys 0..252
          signal TPBLEDatenFBD_HLIPB_Byte39: start 312, 8 bit, little-endian, data-type-policy=OVERRIDE, base-type=uint8, compu {phys=raw}, range phys 0..252
          signal TPBLEDatenFBD_HLIPB_Byte40: start 320, 8 bit, little-endian, data-type-policy=OVERRIDE, base-type=uint8, compu {phys=raw}, range phys 0..252
          signal TPBLEDatenFBD_HLIPB_Byte41: start 328, 8 bit, little-endian, data-type-policy=OVERRIDE, base-type=uint8, compu {phys=raw}, range phys 0..252
          signal TPBLEDatenFBD_HLIPB_Byte42: start 336, 8 bit, little-endian, data-type-policy=OVERRIDE, base-type=uint8, compu {phys=raw}, range phys 0..252
          signal TPBLEDatenFBD_HLIPB_Byte43: start 344, 8 bit, little-endian, data-type-policy=OVERRIDE, base-type=uint8, compu {phys=raw}, range phys 0..252
          signal TPBLEDatenFBD_HLIPB_Byte44: start 352, 8 bit, little-endian, data-type-policy=OVERRIDE, base-type=uint8, compu {phys=raw}, range phys 0..252
          signal TPBLEDatenFBD_HLIPB_Byte45: start 360, 8 bit, little-endian, data-type-policy=OVERRIDE, base-type=uint8, compu {phys=raw}, range phys 0..252
          signal TPBLEDatenFBD_HLIPB_Byte46: start 368, 8 bit, little-endian, data-type-policy=OVERRIDE, base-type=uint8, compu {phys=raw}, range phys 0..252
          signal TPBLEDatenFBD_HLIPB_Byte47: start 376, 8 bit, little-endian, data-type-policy=OVERRIDE, base-type=uint8, compu {phys=raw}, range phys 0..252
          signal TPBLEDatenFBD_HLIPB_Byte48: start 384, 8 bit, little-endian, data-type-policy=OVERRIDE, base-type=uint8, compu {phys=raw}, range phys 0..252
          signal TPBLEDatenFBD_HLIPB_Byte49: start 392, 8 bit, little-endian, data-type-policy=OVERRIDE, base-type=uint8, compu {phys=raw}, range phys 0..252
          signal TPBLEDatenFBD_HLIPB_Byte50: start 400, 8 bit, little-endian, data-type-policy=OVERRIDE, base-type=uint8, compu {phys=raw}, range phys 0..252
          signal TPBLEDatenFBD_HLIPB_Byte51: start 408, 8 bit, little-endian, data-type-policy=OVERRIDE, base-type=uint8, compu {phys=raw}, range phys 0..252
          signal TPBLEDatenFBD_HLIPB_Byte52: start 416, 8 bit, little-endian, data-type-policy=OVERRIDE, base-type=uint8, compu {phys=raw}, range phys 0..252
          signal TPBLEDatenFBD_HLIPB_Byte53: start 424, 8 bit, little-endian, data-type-policy=OVERRIDE, base-type=uint8, compu {phys=raw}, range phys 0..252
          signal TPBLEDatenFBD_HLIPB_Byte54: start 432, 8 bit, little-endian, data-type-policy=OVERRIDE, base-type=uint8, compu {phys=raw}, range phys 0..252
          signal TPBLEDatenFBD_HLIPB_Byte55: start 440, 8 bit, little-endian, data-type-policy=OVERRIDE, base-type=uint8, compu {phys=raw}, range phys 0..252
          signal TPBLEDatenFBD_HLIPB_Byte56: start 448, 8 bit, little-endian, data-type-policy=OVERRIDE, base-type=uint8, compu {phys=raw}, range phys 0..252
          signal TPBLEDatenFBD_HLIPB_Byte57: start 456, 8 bit, little-endian, data-type-policy=OVERRIDE, base-type=uint8, compu {phys=raw}, range phys 0..252
          signal TPBLEDatenFBD_HLIPB_Byte58: start 464, 8 bit, little-endian, data-type-policy=OVERRIDE, base-type=uint8, compu {phys=raw}, range phys 0..252
          signal TPBLEDatenFBD_HLIPB_Byte59: start 472, 8 bit, little-endian, data-type-policy=OVERRIDE, base-type=uint8, compu {phys=raw}, range phys 0..252
          signal TPBLEDatenFBD_HLIPB_Byte60: start 480, 8 bit, little-endian, data-type-policy=OVERRIDE, base-type=uint8, compu {phys=raw}, range phys 0..252
          signal TPBLEDatenFBD_HLIPB_Byte61: start 488, 8 bit, little-endian, data-type-policy=OVERRIDE, base-type=uint8, compu {phys=raw}, range phys 0..252
          signal TPBLEDatenFBD_HLIPB_Byte62: start 496, 8 bit, little-endian, data-type-policy=OVERRIDE, base-type=uint8, compu {phys=raw}, range phys 0..252
          signal TPBLEDatenFBD_HLIPB_Byte63: start 504, 8 bit, little-endian, data-type-policy=OVERRIDE, base-type=uint8, compu {phys=raw}, range phys 0..252
      frame TPBLEDaten_FBD_HM_IPB: id 0x1FF, frame-length=64, can-addressing-mode=STANDARD, can-frame-rx-behavior=CAN-FD, can-frame-tx-behavior=CAN-FD
        pdu TPBLEDaten_FBD_HM_IPB: length=64, unused-bit-pattern=0
          signal TPBLEDatenFBD_HMIPB_Byte00: start 0, 8 bit, little-endian, data-type-policy=OVERRIDE, base-type=uint8, compu {phys=raw}, range phys 0..252
          signal TPBLEDatenFBD_HMIPB_Byte01: start 8, 8 bit, little-endian, data-type-policy=OVERRIDE, base-type=uint8, compu {phys=raw}, range phys 0..252
          signal TPBLEDatenFBD_HMIPB_Byte02: start 16, 8 bit, little-endian, data-type-policy=OVERRIDE, base-type=uint8, compu {phys=raw}, range phys 0..252
          signal TPBLEDatenFBD_HMIPB_Byte03: start 24, 8 bit, little-endian, data-type-policy=OVERRIDE, base-type=uint8, compu {phys=raw}, range phys 0..252
          signal TPBLEDatenFBD_HMIPB_Byte04: start 32, 8 bit, little-endian, data-type-policy=OVERRIDE, base-type=uint8, compu {phys=raw}, range phys 0..252
          signal TPBLEDatenFBD_HMIPB_Byte05: start 40, 8 bit, little-endian, data-type-policy=OVERRIDE, base-type=uint8, compu {phys=raw}, range phys 0..252
          signal TPBLEDatenFBD_HMIPB_Byte06: start 48, 8 bit, little-endian, data-type-policy=OVERRIDE, base-type=uint8, compu {phys=raw}, range phys 0..252
          signal TPBLEDatenFBD_HMIPB_Byte07: start 56, 8 bit, little-endian, data-type-policy=OVERRIDE, base-type=uint8, compu {phys=raw}, range phys 0..252
          signal TPBLEDatenFBD_HMIPB_Byte08: start 64, 8 bit, little-endian, data-type-policy=OVERRIDE, base-type=uint8, compu {phys=raw}, range phys 0..252
          signal TPBLEDatenFBD_HMIPB_Byte09: start 72, 8 bit, little-endian, data-type-policy=OVERRIDE, base-type=uint8, compu {phys=raw}, range phys 0..252
          signal TPBLEDatenFBD_HMIPB_Byte10: start 80, 8 bit, little-endian, data-type-policy=OVERRIDE, base-type=uint8, compu {phys=raw}, range phys 0..252
          signal TPBLEDatenFBD_HMIPB_Byte11: start 88, 8 bit, little-endian, data-type-policy=OVERRIDE, base-type=uint8, compu {phys=raw}, range phys 0..252
          signal TPBLEDatenFBD_HMIPB_Byte12: start 96, 8 bit, little-endian, data-type-policy=OVERRIDE, base-type=uint8, compu {phys=raw}, range phys 0..252
          signal TPBLEDatenFBD_HMIPB_Byte13: start 104, 8 bit, little-endian, data-type-policy=OVERRIDE, base-type=uint8, compu {phys=raw}, range phys 0..252
          signal TPBLEDatenFBD_HMIPB_Byte14: start 112, 8 bit, little-endian, data-type-policy=OVERRIDE, base-type=uint8, compu {phys=raw}, range phys 0..252
          signal TPBLEDatenFBD_HMIPB_Byte15: start 120, 8 bit, little-endian, data-type-policy=OVERRIDE, base-type=uint8, compu {phys=raw}, range phys 0..252
          signal TPBLEDatenFBD_HMIPB_Byte16: start 128, 8 bit, little-endian, data-type-policy=OVERRIDE, base-type=uint8, compu {phys=raw}, range phys 0..252
          signal TPBLEDatenFBD_HMIPB_Byte17: start 136, 8 bit, little-endian, data-type-policy=OVERRIDE, base-type=uint8, compu {phys=raw}, range phys 0..252
          signal TPBLEDatenFBD_HMIPB_Byte18: start 144, 8 bit, little-endian, data-type-policy=OVERRIDE, base-type=uint8, compu {phys=raw}, range phys 0..252
          signal TPBLEDatenFBD_HMIPB_Byte19: start 152, 8 bit, little-endian, data-type-policy=OVERRIDE, base-type=uint8, compu {phys=raw}, range phys 0..252
          signal TPBLEDatenFBD_HMIPB_Byte20: start 160, 8 bit, little-endian, data-type-policy=OVERRIDE, base-type=uint8, compu {phys=raw}, range phys 0..252
          signal TPBLEDatenFBD_HMIPB_Byte21: start 168, 8 bit, little-endian, data-type-policy=OVERRIDE, base-type=uint8, compu {phys=raw}, range phys 0..252
          signal TPBLEDatenFBD_HMIPB_Byte22: start 176, 8 bit, little-endian, data-type-policy=OVERRIDE, base-type=uint8, compu {phys=raw}, range phys 0..252
          signal TPBLEDatenFBD_HMIPB_Byte23: start 184, 8 bit, little-endian, data-type-policy=OVERRIDE, base-type=uint8, compu {phys=raw}, range phys 0..252
          signal TPBLEDatenFBD_HMIPB_Byte24: start 192, 8 bit, little-endian, data-type-policy=OVERRIDE, base-type=uint8, compu {phys=raw}, range phys 0..252
          signal TPBLEDatenFBD_HMIPB_Byte25: start 200, 8 bit, little-endian, data-type-policy=OVERRIDE, base-type=uint8, compu {phys=raw}, range phys 0..252
          signal TPBLEDatenFBD_HMIPB_Byte26: start 208, 8 bit, little-endian, data-type-policy=OVERRIDE, base-type=uint8, compu {phys=raw}, range phys 0..252
          signal TPBLEDatenFBD_HMIPB_Byte27: start 216, 8 bit, little-endian, data-type-policy=OVERRIDE, base-type=uint8, compu {phys=raw}, range phys 0..252
          signal TPBLEDatenFBD_HMIPB_Byte28: start 224, 8 bit, little-endian, data-type-policy=OVERRIDE, base-type=uint8, compu {phys=raw}, range phys 0..252
          signal TPBLEDatenFBD_HMIPB_Byte29: start 232, 8 bit, little-endian, data-type-policy=OVERRIDE, base-type=uint8, compu {phys=raw}, range phys 0..252
          signal TPBLEDatenFBD_HMIPB_Byte30: start 240, 8 bit, little-endian, data-type-policy=OVERRIDE, base-type=uint8, compu {phys=raw}, range phys 0..252
          signal TPBLEDatenFBD_HMIPB_Byte31: start 248, 8 bit, little-endian, data-type-policy=OVERRIDE, base-type=uint8, compu {phys=raw}, range phys 0..252
          signal TPBLEDatenFBD_HMIPB_Byte32: start 256, 8 bit, little-endian, data-type-policy=OVERRIDE, base-type=uint8, compu {phys=raw}, range phys 0..252
          signal TPBLEDatenFBD_HMIPB_Byte33: start 264, 8 bit, little-endian, data-type-policy=OVERRIDE, base-type=uint8, compu {phys=raw}, range phys 0..252
          signal TPBLEDatenFBD_HMIPB_Byte34: start 272, 8 bit, little-endian, data-type-policy=OVERRIDE, base-type=uint8, compu {phys=raw}, range phys 0..252
          signal TPBLEDatenFBD_HMIPB_Byte35: start 280, 8 bit, little-endian, data-type-policy=OVERRIDE, base-type=uint8, compu {phys=raw}, range phys 0..252
          signal TPBLEDatenFBD_HMIPB_Byte36: start 288, 8 bit, little-endian, data-type-policy=OVERRIDE, base-type=uint8, compu {phys=raw}, range phys 0..252
          signal TPBLEDatenFBD_HMIPB_Byte37: start 296, 8 bit, little-endian, data-type-policy=OVERRIDE, base-type=uint8, compu {phys=raw}, range phys 0..252
          signal TPBLEDatenFBD_HMIPB_Byte38: start 304, 8 bit, little-endian, data-type-policy=OVERRIDE, base-type=uint8, compu {phys=raw}, range phys 0..252
          signal TPBLEDatenFBD_HMIPB_Byte39: start 312, 8 bit, little-endian, data-type-policy=OVERRIDE, base-type=uint8, compu {phys=raw}, range phys 0..252
          signal TPBLEDatenFBD_HMIPB_Byte40: start 320, 8 bit, little-endian, data-type-policy=OVERRIDE, base-type=uint8, compu {phys=raw}, range phys 0..252
          signal TPBLEDatenFBD_HMIPB_Byte41: start 328, 8 bit, little-endian, data-type-policy=OVERRIDE, base-type=uint8, compu {phys=raw}, range phys 0..252
          signal TPBLEDatenFBD_HMIPB_Byte42: start 336, 8 bit, little-endian, data-type-policy=OVERRIDE, base-type=uint8, compu {phys=raw}, range phys 0..252
          signal TPBLEDatenFBD_HMIPB_Byte43: start 344, 8 bit, little-endian, data-type-policy=OVERRIDE, base-type=uint8, compu {phys=raw}, range phys 0..252
          signal TPBLEDatenFBD_HMIPB_Byte44: start 352, 8 bit, little-endian, data-type-policy=OVERRIDE, base-type=uint8, compu {phys=raw}, range phys 0..252
          signal TPBLEDatenFBD_HMIPB_Byte45: start 360, 8 bit, little-endian, data-type-policy=OVERRIDE, base-type=uint8, compu {phys=raw}, range phys 0..252
          signal TPBLEDatenFBD_HMIPB_Byte46: start 368, 8 bit, little-endian, data-type-policy=OVERRIDE, base-type=uint8, compu {phys=raw}, range phys 0..252
          signal TPBLEDatenFBD_HMIPB_Byte47: start 376, 8 bit, little-endian, data-type-policy=OVERRIDE, base-type=uint8, compu {phys=raw}, range phys 0..252
          signal TPBLEDatenFBD_HMIPB_Byte48: start 384, 8 bit, little-endian, data-type-policy=OVERRIDE, base-type=uint8, compu {phys=raw}, range phys 0..252
          signal TPBLEDatenFBD_HMIPB_Byte49: start 392, 8 bit, little-endian, data-type-policy=OVERRIDE, base-type=uint8, compu {phys=raw}, range phys 0..252
          signal TPBLEDatenFBD_HMIPB_Byte50: start 400, 8 bit, little-endian, data-type-policy=OVERRIDE, base-type=uint8, compu {phys=raw}, range phys 0..252
          signal TPBLEDatenFBD_HMIPB_Byte51: start 408, 8 bit, little-endian, data-type-policy=OVERRIDE, base-type=uint8, compu {phys=raw}, range phys 0..252
          signal TPBLEDatenFBD_HMIPB_Byte52: start 416, 8 bit, little-endian, data-type-policy=OVERRIDE, base-type=uint8, compu {phys=raw}, range phys 0..252
          signal TPBLEDatenFBD_HMIPB_Byte53: start 424, 8 bit, little-endian, data-type-policy=OVERRIDE, base-type=uint8, compu {phys=raw}, range phys 0..252
          signal TPBLEDatenFBD_HMIPB_Byte54: start 432, 8 bit, little-endian, data-type-policy=OVERRIDE, base-type=uint8, compu {phys=raw}, range phys 0..252
          signal TPBLEDatenFBD_HMIPB_Byte55: start 440, 8 bit, little-endian, data-type-policy=OVERRIDE, base-type=uint8, compu {phys=raw}, range phys 0..252
          signal TPBLEDatenFBD_HMIPB_Byte56: start 448, 8 bit, little-endian, data-type-policy=OVERRIDE, base-type=uint8, compu {phys=raw}, range phys 0..252
          signal TPBLEDatenFBD_HMIPB_Byte57: start 456, 8 bit, little-endian, data-type-policy=OVERRIDE, base-type=uint8, compu {phys=raw}, range phys 0..252
          signal TPBLEDatenFBD_HMIPB_Byte58: start 464, 8 bit, little-endian, data-type-policy=OVERRIDE, base-type=uint8, compu {phys=raw}, range phys 0..252
          signal TPBLEDatenFBD_HMIPB_Byte59: start 472, 8 bit, little-endian, data-type-policy=OVERRIDE, base-type=uint8, compu {phys=raw}, range phys 0..252
          signal TPBLEDatenFBD_HMIPB_Byte60: start 480, 8 bit, little-endian, data-type-policy=OVERRIDE, base-type=uint8, compu {phys=raw}, range phys 0..252
          signal TPBLEDatenFBD_HMIPB_Byte61: start 488, 8 bit, little-endian, data-type-policy=OVERRIDE, base-type=uint8, compu {phys=raw}, range phys 0..252
          signal TPBLEDatenFBD_HMIPB_Byte62: start 496, 8 bit, little-endian, data-type-policy=OVERRIDE, base-type=uint8, compu {phys=raw}, range phys 0..252
          signal TPBLEDatenFBD_HMIPB_Byte63: start 504, 8 bit, little-endian, data-type-policy=OVERRIDE, base-type=uint8, compu {phys=raw}, range phys 0..252
      frame TPBLEDaten_FBD_HR_IPB: id 0x205, frame-length=64, can-addressing-mode=STANDARD, can-frame-rx-behavior=CAN-FD, can-frame-tx-behavior=CAN-FD
        pdu TPBLEDaten_FBD_HR_IPB: length=64, unused-bit-pattern=0
          signal TPBLEDatenFBD_HRIPB_Byte00: start 0, 8 bit, little-endian, data-type-policy=OVERRIDE, base-type=uint8, compu {phys=raw}, range phys 0..252
          signal TPBLEDatenFBD_HRIPB_Byte01: start 8, 8 bit, little-endian, data-type-policy=OVERRIDE, base-type=uint8, compu {phys=raw}, range phys 0..252
          signal TPBLEDatenFBD_HRIPB_Byte02: start 16, 8 bit, little-endian, data-type-policy=OVERRIDE, base-type=uint8, compu {phys=raw}, range phys 0..252
          signal TPBLEDatenFBD_HRIPB_Byte03: start 24, 8 bit, little-endian, data-type-policy=OVERRIDE, base-type=uint8, compu {phys=raw}, range phys 0..252
          signal TPBLEDatenFBD_HRIPB_Byte04: start 32, 8 bit, little-endian, data-type-policy=OVERRIDE, base-type=uint8, compu {phys=raw}, range phys 0..252
          signal TPBLEDatenFBD_HRIPB_Byte05: start 40, 8 bit, little-endian, data-type-policy=OVERRIDE, base-type=uint8, compu {phys=raw}, range phys 0..252
          signal TPBLEDatenFBD_HRIPB_Byte06: start 48, 8 bit, little-endian, data-type-policy=OVERRIDE, base-type=uint8, compu {phys=raw}, range phys 0..252
          signal TPBLEDatenFBD_HRIPB_Byte07: start 56, 8 bit, little-endian, data-type-policy=OVERRIDE, base-type=uint8, compu {phys=raw}, range phys 0..252
          signal TPBLEDatenFBD_HRIPB_Byte08: start 64, 8 bit, little-endian, data-type-policy=OVERRIDE, base-type=uint8, compu {phys=raw}, range phys 0..252
          signal TPBLEDatenFBD_HRIPB_Byte09: start 72, 8 bit, little-endian, data-type-policy=OVERRIDE, base-type=uint8, compu {phys=raw}, range phys 0..252
          signal TPBLEDatenFBD_HRIPB_Byte10: start 80, 8 bit, little-endian, data-type-policy=OVERRIDE, base-type=uint8, compu {phys=raw}, range phys 0..252
          signal TPBLEDatenFBD_HRIPB_Byte11: start 88, 8 bit, little-endian, data-type-policy=OVERRIDE, base-type=uint8, compu {phys=raw}, range phys 0..252
          signal TPBLEDatenFBD_HRIPB_Byte12: start 96, 8 bit, little-endian, data-type-policy=OVERRIDE, base-type=uint8, compu {phys=raw}, range phys 0..252
          signal TPBLEDatenFBD_HRIPB_Byte13: start 104, 8 bit, little-endian, data-type-policy=OVERRIDE, base-type=uint8, compu {phys=raw}, range phys 0..252
          signal TPBLEDatenFBD_HRIPB_Byte14: start 112, 8 bit, little-endian, data-type-policy=OVERRIDE, base-type=uint8, compu {phys=raw}, range phys 0..252
          signal TPBLEDatenFBD_HRIPB_Byte15: start 120, 8 bit, little-endian, data-type-policy=OVERRIDE, base-type=uint8, compu {phys=raw}, range phys 0..252
          signal TPBLEDatenFBD_HRIPB_Byte16: start 128, 8 bit, little-endian, data-type-policy=OVERRIDE, base-type=uint8, compu {phys=raw}, range phys 0..252
          signal TPBLEDatenFBD_HRIPB_Byte17: start 136, 8 bit, little-endian, data-type-policy=OVERRIDE, base-type=uint8, compu {phys=raw}, range phys 0..252
          signal TPBLEDatenFBD_HRIPB_Byte18: start 144, 8 bit, little-endian, data-type-policy=OVERRIDE, base-type=uint8, compu {phys=raw}, range phys 0..252
          signal TPBLEDatenFBD_HRIPB_Byte19: start 152, 8 bit, little-endian, data-type-policy=OVERRIDE, base-type=uint8, compu {phys=raw}, range phys 0..252
          signal TPBLEDatenFBD_HRIPB_Byte20: start 160, 8 bit, little-endian, data-type-policy=OVERRIDE, base-type=uint8, compu {phys=raw}, range phys 0..252
          signal TPBLEDatenFBD_HRIPB_Byte21: start 168, 8 bit, little-endian, data-type-policy=OVERRIDE, base-type=uint8, compu {phys=raw}, range phys 0..252
          signal TPBLEDatenFBD_HRIPB_Byte22: start 176, 8 bit, little-endian, data-type-policy=OVERRIDE, base-type=uint8, compu {phys=raw}, range phys 0..252
          signal TPBLEDatenFBD_HRIPB_Byte23: start 184, 8 bit, little-endian, data-type-policy=OVERRIDE, base-type=uint8, compu {phys=raw}, range phys 0..252
          signal TPBLEDatenFBD_HRIPB_Byte24: start 192, 8 bit, little-endian, data-type-policy=OVERRIDE, base-type=uint8, compu {phys=raw}, range phys 0..252
          signal TPBLEDatenFBD_HRIPB_Byte25: start 200, 8 bit, little-endian, data-type-policy=OVERRIDE, base-type=uint8, compu {phys=raw}, range phys 0..252
          signal TPBLEDatenFBD_HRIPB_Byte26: start 208, 8 bit, little-endian, data-type-policy=OVERRIDE, base-type=uint8, compu {phys=raw}, range phys 0..252
          signal TPBLEDatenFBD_HRIPB_Byte27: start 216, 8 bit, little-endian, data-type-policy=OVERRIDE, base-type=uint8, compu {phys=raw}, range phys 0..252
          signal TPBLEDatenFBD_HRIPB_Byte28: start 224, 8 bit, little-endian, data-type-policy=OVERRIDE, base-type=uint8, compu {phys=raw}, range phys 0..252
          signal TPBLEDatenFBD_HRIPB_Byte29: start 232, 8 bit, little-endian, data-type-policy=OVERRIDE, base-type=uint8, compu {phys=raw}, range phys 0..252
          signal TPBLEDatenFBD_HRIPB_Byte30: start 240, 8 bit, little-endian, data-type-policy=OVERRIDE, base-type=uint8, compu {phys=raw}, range phys 0..252
          signal TPBLEDatenFBD_HRIPB_Byte31: start 248, 8 bit, little-endian, data-type-policy=OVERRIDE, base-type=uint8, compu {phys=raw}, range phys 0..252
          signal TPBLEDatenFBD_HRIPB_Byte32: start 256, 8 bit, little-endian, data-type-policy=OVERRIDE, base-type=uint8, compu {phys=raw}, range phys 0..252
          signal TPBLEDatenFBD_HRIPB_Byte33: start 264, 8 bit, little-endian, data-type-policy=OVERRIDE, base-type=uint8, compu {phys=raw}, range phys 0..252
          signal TPBLEDatenFBD_HRIPB_Byte34: start 272, 8 bit, little-endian, data-type-policy=OVERRIDE, base-type=uint8, compu {phys=raw}, range phys 0..252
          signal TPBLEDatenFBD_HRIPB_Byte35: start 280, 8 bit, little-endian, data-type-policy=OVERRIDE, base-type=uint8, compu {phys=raw}, range phys 0..252
          signal TPBLEDatenFBD_HRIPB_Byte36: start 288, 8 bit, little-endian, data-type-policy=OVERRIDE, base-type=uint8, compu {phys=raw}, range phys 0..252
          signal TPBLEDatenFBD_HRIPB_Byte37: start 296, 8 bit, little-endian, data-type-policy=OVERRIDE, base-type=uint8, compu {phys=raw}, range phys 0..252
          signal TPBLEDatenFBD_HRIPB_Byte38: start 304, 8 bit, little-endian, data-type-policy=OVERRIDE, base-type=uint8, compu {phys=raw}, range phys 0..252
          signal TPBLEDatenFBD_HRIPB_Byte39: start 312, 8 bit, little-endian, data-type-policy=OVERRIDE, base-type=uint8, compu {phys=raw}, range phys 0..252
          signal TPBLEDatenFBD_HRIPB_Byte40: start 320, 8 bit, little-endian, data-type-policy=OVERRIDE, base-type=uint8, compu {phys=raw}, range phys 0..252
          signal TPBLEDatenFBD_HRIPB_Byte41: start 328, 8 bit, little-endian, data-type-policy=OVERRIDE, base-type=uint8, compu {phys=raw}, range phys 0..252
          signal TPBLEDatenFBD_HRIPB_Byte42: start 336, 8 bit, little-endian, data-type-policy=OVERRIDE, base-type=uint8, compu {phys=raw}, range phys 0..252
          signal TPBLEDatenFBD_HRIPB_Byte43: start 344, 8 bit, little-endian, data-type-policy=OVERRIDE, base-type=uint8, compu {phys=raw}, range phys 0..252
          signal TPBLEDatenFBD_HRIPB_Byte44: start 352, 8 bit, little-endian, data-type-policy=OVERRIDE, base-type=uint8, compu {phys=raw}, range phys 0..252
          signal TPBLEDatenFBD_HRIPB_Byte45: start 360, 8 bit, little-endian, data-type-policy=OVERRIDE, base-type=uint8, compu {phys=raw}, range phys 0..252
          signal TPBLEDatenFBD_HRIPB_Byte46: start 368, 8 bit, little-endian, data-type-policy=OVERRIDE, base-type=uint8, compu {phys=raw}, range phys 0..252
          signal TPBLEDatenFBD_HRIPB_Byte47: start 376, 8 bit, little-endian, data-type-policy=OVERRIDE, base-type=uint8, compu {phys=raw}, range phys 0..252
          signal TPBLEDatenFBD_HRIPB_Byte48: start 384, 8 bit, little-endian, data-type-policy=OVERRIDE, base-type=uint8, compu {phys=raw}, range phys 0..252
          signal TPBLEDatenFBD_HRIPB_Byte49: start 392, 8 bit, little-endian, data-type-policy=OVERRIDE, base-type=uint8, compu {phys=raw}, range phys 0..252
          signal TPBLEDatenFBD_HRIPB_Byte50: start 400, 8 bit, little-endian, data-type-policy=OVERRIDE, base-type=uint8, compu {phys=raw}, range phys 0..252
          signal TPBLEDatenFBD_HRIPB_Byte51: start 408, 8 bit, little-endian, data-type-policy=OVERRIDE, base-type=uint8, compu {phys=raw}, range phys 0..252
          signal TPBLEDatenFBD_HRIPB_Byte52: start 416, 8 bit, little-endian, data-type-policy=OVERRIDE, base-type=uint8, compu {phys=raw}, range phys 0..252
          signal TPBLEDatenFBD_HRIPB_Byte53: start 424, 8 bit, little-endian, data-type-policy=OVERRIDE, base-type=uint8, compu {phys=raw}, range phys 0..252
          signal TPBLEDatenFBD_HRIPB_Byte54: start 432, 8 bit, little-endian, data-type-policy=OVERRIDE, base-type=uint8, compu {phys=raw}, range phys 0..252
          signal TPBLEDatenFBD_HRIPB_Byte55: start 440, 8 bit, little-endian, data-type-policy=OVERRIDE, base-type=uint8, compu {phys=raw}, range phys 0..252
          signal TPBLEDatenFBD_HRIPB_Byte56: start 448, 8 bit, little-endian, data-type-policy=OVERRIDE, base-type=uint8, compu {phys=raw}, range phys 0..252
          signal TPBLEDatenFBD_HRIPB_Byte57: start 456, 8 bit, little-endian, data-type-policy=OVERRIDE, base-type=uint8, compu {phys=raw}, range phys 0..252
          signal TPBLEDatenFBD_HRIPB_Byte58: start 464, 8 bit, little-endian, data-type-policy=OVERRIDE, base-type=uint8, compu {phys=raw}, range phys 0..252
          signal TPBLEDatenFBD_HRIPB_Byte59: start 472, 8 bit, little-endian, data-type-policy=OVERRIDE, base-type=uint8, compu {phys=raw}, range phys 0..252
          signal TPBLEDatenFBD_HRIPB_Byte60: start 480, 8 bit, little-endian, data-type-policy=OVERRIDE, base-type=uint8, compu {phys=raw}, range phys 0..252
          signal TPBLEDatenFBD_HRIPB_Byte61: start 488, 8 bit, little-endian, data-type-policy=OVERRIDE, base-type=uint8, compu {phys=raw}, range phys 0..252
          signal TPBLEDatenFBD_HRIPB_Byte62: start 496, 8 bit, little-endian, data-type-policy=OVERRIDE, base-type=uint8, compu {phys=raw}, range phys 0..252
          signal TPBLEDatenFBD_HRIPB_Byte63: start 504, 8 bit, little-endian, data-type-policy=OVERRIDE, base-type=uint8, compu {phys=raw}, range phys 0..252
      frame TPBLEDaten_FBD_Miko_IPB: id 0x200, frame-length=64, can-addressing-mode=STANDARD, can-frame-rx-behavior=CAN-FD, can-frame-tx-behavior=CAN-FD
        pdu TPBLEDaten_FBD_Miko_IPB: length=64, unused-bit-pattern=0
          signal TPBLEDatenFBD_MikoIPB_Byte00: start 0, 8 bit, little-endian, data-type-policy=OVERRIDE, base-type=uint8, compu {phys=raw}, range phys 0..252
          signal TPBLEDatenFBD_MikoIPB_Byte01: start 8, 8 bit, little-endian, data-type-policy=OVERRIDE, base-type=uint8, compu {phys=raw}, range phys 0..252
          signal TPBLEDatenFBD_MikoIPB_Byte02: start 16, 8 bit, little-endian, data-type-policy=OVERRIDE, base-type=uint8, compu {phys=raw}, range phys 0..252
          signal TPBLEDatenFBD_MikoIPB_Byte03: start 24, 8 bit, little-endian, data-type-policy=OVERRIDE, base-type=uint8, compu {phys=raw}, range phys 0..252
          signal TPBLEDatenFBD_MikoIPB_Byte04: start 32, 8 bit, little-endian, data-type-policy=OVERRIDE, base-type=uint8, compu {phys=raw}, range phys 0..252
          signal TPBLEDatenFBD_MikoIPB_Byte05: start 40, 8 bit, little-endian, data-type-policy=OVERRIDE, base-type=uint8, compu {phys=raw}, range phys 0..252
          signal TPBLEDatenFBD_MikoIPB_Byte06: start 48, 8 bit, little-endian, data-type-policy=OVERRIDE, base-type=uint8, compu {phys=raw}, range phys 0..252
          signal TPBLEDatenFBD_MikoIPB_Byte07: start 56, 8 bit, little-endian, data-type-policy=OVERRIDE, base-type=uint8, compu {phys=raw}, range phys 0..252
          signal TPBLEDatenFBD_MikoIPB_Byte08: start 64, 8 bit, little-endian, data-type-policy=OVERRIDE, base-type=uint8, compu {phys=raw}, range phys 0..252
          signal TPBLEDatenFBD_MikoIPB_Byte09: start 72, 8 bit, little-endian, data-type-policy=OVERRIDE, base-type=uint8, compu {phys=raw}, range phys 0..252
          signal TPBLEDatenFBD_MikoIPB_Byte10: start 80, 8 bit, little-endian, data-type-policy=OVERRIDE, base-type=uint8, compu {phys=raw}, range phys 0..252
          signal TPBLEDatenFBD_MikoIPB_Byte11: start 88, 8 bit, little-endian, data-type-policy=OVERRIDE, base-type=uint8, compu {phys=raw}, range phys 0..252
          signal TPBLEDatenFBD_MikoIPB_Byte12: start 96, 8 bit, little-endian, data-type-policy=OVERRIDE, base-type=uint8, compu {phys=raw}, range phys 0..252
          signal TPBLEDatenFBD_MikoIPB_Byte13: start 104, 8 bit, little-endian, data-type-policy=OVERRIDE, base-type=uint8, compu {phys=raw}, range phys 0..252
          signal TPBLEDatenFBD_MikoIPB_Byte14: start 112, 8 bit, little-endian, data-type-policy=OVERRIDE, base-type=uint8, compu {phys=raw}, range phys 0..252
          signal TPBLEDatenFBD_MikoIPB_Byte15: start 120, 8 bit, little-endian, data-type-policy=OVERRIDE, base-type=uint8, compu {phys=raw}, range phys 0..252
          signal TPBLEDatenFBD_MikoIPB_Byte16: start 128, 8 bit, little-endian, data-type-policy=OVERRIDE, base-type=uint8, compu {phys=raw}, range phys 0..252
          signal TPBLEDatenFBD_MikoIPB_Byte17: start 136, 8 bit, little-endian, data-type-policy=OVERRIDE, base-type=uint8, compu {phys=raw}, range phys 0..252
          signal TPBLEDatenFBD_MikoIPB_Byte18: start 144, 8 bit, little-endian, data-type-policy=OVERRIDE, base-type=uint8, compu {phys=raw}, range phys 0..252
          signal TPBLEDatenFBD_MikoIPB_Byte19: start 152, 8 bit, little-endian, data-type-policy=OVERRIDE, base-type=uint8, compu {phys=raw}, range phys 0..252
          signal TPBLEDatenFBD_MikoIPB_Byte20: start 160, 8 bit, little-endian, data-type-policy=OVERRIDE, base-type=uint8, compu {phys=raw}, range phys 0..252
          signal TPBLEDatenFBD_MikoIPB_Byte21: start 168, 8 bit, little-endian, data-type-policy=OVERRIDE, base-type=uint8, compu {phys=raw}, range phys 0..252
          signal TPBLEDatenFBD_MikoIPB_Byte22: start 176, 8 bit, little-endian, data-type-policy=OVERRIDE, base-type=uint8, compu {phys=raw}, range phys 0..252
          signal TPBLEDatenFBD_MikoIPB_Byte23: start 184, 8 bit, little-endian, data-type-policy=OVERRIDE, base-type=uint8, compu {phys=raw}, range phys 0..252
          signal TPBLEDatenFBD_MikoIPB_Byte24: start 192, 8 bit, little-endian, data-type-policy=OVERRIDE, base-type=uint8, compu {phys=raw}, range phys 0..252
          signal TPBLEDatenFBD_MikoIPB_Byte25: start 200, 8 bit, little-endian, data-type-policy=OVERRIDE, base-type=uint8, compu {phys=raw}, range phys 0..252
          signal TPBLEDatenFBD_MikoIPB_Byte26: start 208, 8 bit, little-endian, data-type-policy=OVERRIDE, base-type=uint8, compu {phys=raw}, range phys 0..252
          signal TPBLEDatenFBD_MikoIPB_Byte27: start 216, 8 bit, little-endian, data-type-policy=OVERRIDE, base-type=uint8, compu {phys=raw}, range phys 0..252
          signal TPBLEDatenFBD_MikoIPB_Byte28: start 224, 8 bit, little-endian, data-type-policy=OVERRIDE, base-type=uint8, compu {phys=raw}, range phys 0..252
          signal TPBLEDatenFBD_MikoIPB_Byte29: start 232, 8 bit, little-endian, data-type-policy=OVERRIDE, base-type=uint8, compu {phys=raw}, range phys 0..252
          signal TPBLEDatenFBD_MikoIPB_Byte30: start 240, 8 bit, little-endian, data-type-policy=OVERRIDE, base-type=uint8, compu {phys=raw}, range phys 0..252
          signal TPBLEDatenFBD_MikoIPB_Byte31: start 248, 8 bit, little-endian, data-type-policy=OVERRIDE, base-type=uint8, compu {phys=raw}, range phys 0..252
          signal TPBLEDatenFBD_MikoIPB_Byte32: start 256, 8 bit, little-endian, data-type-policy=OVERRIDE, base-type=uint8, compu {phys=raw}, range phys 0..252
          signal TPBLEDatenFBD_MikoIPB_Byte33: start 264, 8 bit, little-endian, data-type-policy=OVERRIDE, base-type=uint8, compu {phys=raw}, range phys 0..252
          signal TPBLEDatenFBD_MikoIPB_Byte34: start 272, 8 bit, little-endian, data-type-policy=OVERRIDE, base-type=uint8, compu {phys=raw}, range phys 0..252
          signal TPBLEDatenFBD_MikoIPB_Byte35: start 280, 8 bit, little-endian, data-type-policy=OVERRIDE, base-type=uint8, compu {phys=raw}, range phys 0..252
          signal TPBLEDatenFBD_MikoIPB_Byte36: start 288, 8 bit, little-endian, data-type-policy=OVERRIDE, base-type=uint8, compu {phys=raw}, range phys 0..252
          signal TPBLEDatenFBD_MikoIPB_Byte37: start 296, 8 bit, little-endian, data-type-policy=OVERRIDE, base-type=uint8, compu {phys=raw}, range phys 0..252
          signal TPBLEDatenFBD_MikoIPB_Byte38: start 304, 8 bit, little-endian, data-type-policy=OVERRIDE, base-type=uint8, compu {phys=raw}, range phys 0..252
          signal TPBLEDatenFBD_MikoIPB_Byte39: start 312, 8 bit, little-endian, data-type-policy=OVERRIDE, base-type=uint8, compu {phys=raw}, range phys 0..252
          signal TPBLEDatenFBD_MikoIPB_Byte40: start 320, 8 bit, little-endian, data-type-policy=OVERRIDE, base-type=uint8, compu {phys=raw}, range phys 0..252
          signal TPBLEDatenFBD_MikoIPB_Byte41: start 328, 8 bit, little-endian, data-type-policy=OVERRIDE, base-type=uint8, compu {phys=raw}, range phys 0..252
          signal TPBLEDatenFBD_MikoIPB_Byte42: start 336, 8 bit, little-endian, data-type-policy=OVERRIDE, base-type=uint8, compu {phys=raw}, range phys 0..252
          signal TPBLEDatenFBD_MikoIPB_Byte43: start 344, 8 bit, little-endian, data-type-policy=OVERRIDE, base-type=uint8, compu {phys=raw}, range phys 0..252
          signal TPBLEDatenFBD_MikoIPB_Byte44: start 352, 8 bit, little-endian, data-type-policy=OVERRIDE, base-type=uint8, compu {phys=raw}, range phys 0..252
          signal TPBLEDatenFBD_MikoIPB_Byte45: start 360, 8 bit, little-endian, data-type-policy=OVERRIDE, base-type=uint8, compu {phys=raw}, range phys 0..252
          signal TPBLEDatenFBD_MikoIPB_Byte46: start 368, 8 bit, little-endian, data-type-policy=OVERRIDE, base-type=uint8, compu {phys=raw}, range phys 0..252
          signal TPBLEDatenFBD_MikoIPB_Byte47: start 376, 8 bit, little-endian, data-type-policy=OVERRIDE, base-type=uint8, compu {phys=raw}, range phys 0..252
          signal TPBLEDatenFBD_MikoIPB_Byte48: start 384, 8 bit, little-endian, data-type-policy=OVERRIDE, base-type=uint8, compu {phys=raw}, range phys 0..252
          signal TPBLEDatenFBD_MikoIPB_Byte49: start 392, 8 bit, little-endian, data-type-policy=OVERRIDE, base-type=uint8, compu {phys=raw}, range phys 0..252
          signal TPBLEDatenFBD_MikoIPB_Byte50: start 400, 8 bit, little-endian, data-type-policy=OVERRIDE, base-type=uint8, compu {phys=raw}, range phys 0..252
          signal TPBLEDatenFBD_MikoIPB_Byte51: start 408, 8 bit, little-endian, data-type-policy=OVERRIDE, base-type=uint8, compu {phys=raw}, range phys 0..252
          signal TPBLEDatenFBD_MikoIPB_Byte52: start 416, 8 bit, little-endian, data-type-policy=OVERRIDE, base-type=uint8, compu {phys=raw}, range phys 0..252
          signal TPBLEDatenFBD_MikoIPB_Byte53: start 424, 8 bit, little-endian, data-type-policy=OVERRIDE, base-type=uint8, compu {phys=raw}, range phys 0..252
          signal TPBLEDatenFBD_MikoIPB_Byte54: start 432, 8 bit, little-endian, data-type-policy=OVERRIDE, base-type=uint8, compu {phys=raw}, range phys 0..252
          signal TPBLEDatenFBD_MikoIPB_Byte55: start 440, 8 bit, little-endian, data-type-policy=OVERRIDE, base-type=uint8, compu {phys=raw}, range phys 0..252
          signal TPBLEDatenFBD_MikoIPB_Byte56: start 448, 8 bit, little-endian, data-type-policy=OVERRIDE, base-type=uint8, compu {phys=raw}, range phys 0..252
          signal TPBLEDatenFBD_MikoIPB_Byte57: start 456, 8 bit, little-endian, data-type-policy=OVERRIDE, base-type=uint8, compu {phys=raw}, range phys 0..252
          signal TPBLEDatenFBD_MikoIPB_Byte58: start 464, 8 bit, little-endian, data-type-policy=OVERRIDE, base-type=uint8, compu {phys=raw}, range phys 0..252
          signal TPBLEDatenFBD_MikoIPB_Byte59: start 472, 8 bit, little-endian, data-type-policy=OVERRIDE, base-type=uint8, compu {phys=raw}, range phys 0..252
          signal TPBLEDatenFBD_MikoIPB_Byte60: start 480, 8 bit, little-endian, data-type-policy=OVERRIDE, base-type=uint8, compu {phys=raw}, range phys 0..252
          signal TPBLEDatenFBD_MikoIPB_Byte61: start 488, 8 bit, little-endian, data-type-policy=OVERRIDE, base-type=uint8, compu {phys=raw}, range phys 0..252
          signal TPBLEDatenFBD_MikoIPB_Byte62: start 496, 8 bit, little-endian, data-type-policy=OVERRIDE, base-type=uint8, compu {phys=raw}, range phys 0..252
          signal TPBLEDatenFBD_MikoIPB_Byte63: start 504, 8 bit, little-endian, data-type-policy=OVERRIDE, base-type=uint8, compu {phys=raw}, range phys 0..252
